[part 4 of 15: package /Cluster]
AUTOSAR XML (schema 4-3-0)
package /Cluster  (continued)
  can cluster HCP3_CANFD01: baudrate=500000, protocol-name=CAN, protocol-version=2.0, bus-off-recovery={bor-counter-l-1-to-l-2=1, bor-time-l-1=0.05, bor-time-l-2=0.2}, can-fd-baudrate=1000000  (continued)
    can physical channel CHNL: comm-connectors=CN_HCP3_CANFD01  (continued)
      frame LSR_Common_01_XIX_HCP3_CANFD01: id 0x1A5554CC, to HCP3_IONode, frame-length=12, can-addressing-mode=EXTENDED, can-frame-rx-behavior=CAN-FD, can-frame-tx-behavior=CAN-FD
        pdu LSR_Common_01_XIX_HCP3_CANFD01: length=12, transmission-mode-true-timing=cyclic-timing={time-offset=0.0, time-period=1.0}, unused-bit-pattern=0
          signal LSR_SystemMode_XIX_LSR_Common_01_XIX_HCP3_CANFD01: start 12, 1 bit, little-endian, data-type-policy=OVERRIDE, i-signal-type=PRIMITIVE, init-value=0, base-type=BT_LSR_SystemMode, compu {0=Cx0_bootloader (CM_LSR_SystemMode_Cx0_bootloader), 1=Cx1_applikation (CM_LSR_SystemMode_Cx1_applikation)}, range raw 0..1, transfer-property=PENDING, to HCP3_IONode(timeout 5 s)  # Current system mode of LSR
          signal LSR_CL30_Overvolt_Error_XIX_LSR_Common_01_XIX_HCP3_CANFD01: start 13, 1 bit, little-endian, data-type-policy=OVERRIDE, i-signal-type=PRIMITIVE, init-value=0, base-type=BT_LSR_CL30_Overvolt_Error, invalid-value=Invalid_LSR_CL30_Overvolt_Error_XIX_LSR_Common_01_XIX_HCP3_CANFD01:1, compu {1=Cx1_Fehler (CM_LSR_CL30_Overvolt_Error_Cx1_Fehler), 0=Cx0_normal (CM_LSR_CL30_Overvolt_Error_Cx0_normal)}, range raw 0..1, transfer-property=PENDING, to HCP3_IONode(timeout 5 s)  # LSR detected overvoltage error
          signal LSR_CL30_Undervoltage_Error_XIX_LSR_Common_01_XIX_HCP3_CANFD01: start 14, 1 bit, little-endian, data-type-policy=OVERRIDE, i-signal-type=PRIMITIVE, init-value=0, base-type=BT_LSR_CL30_Undervoltage_Error, invalid-value=Invalid_LSR_CL30_Undervoltage_Error_XIX_LSR_Common_01_XIX_HCP3_CANFD01:1, compu {1=Cx1_Fehler (CM_LSR_CL30_Undervoltage_Error_Cx1_Fehler), 0=Cx0_normal (CM_LSR_CL30_Undervoltage_Error_Cx0_normal)}, range raw 0..1, transfer-property=PENDING, to HCP3_IONode(timeout 5 s)  # LSR detected undervoltage error
          signal LSR_EEPROM_Error_TF_XIX_LSR_Common_01_XIX_HCP3_CANFD01: start 15, 1 bit, little-endian, data-type-policy=OVERRIDE, i-signal-type=PRIMITIVE, init-value=0, base-type=BT_LSR_EEPROM_Error_TF, compu {1=Cx1_active (CM_LSR_EEPROM_Error_TF_Cx1_active), 0=Cx0_passive (CM_LSR_EEPROM_Error_TF_Cx0_passive)}, range raw 0..1, transfer-property=PENDING, to HCP3_IONode(timeout 5 s)  # EEPROM_Error of LSR detected Diagnostic information TestFailed
          signal LSR_EEPROM_Error_TNCTOC_XIX_LSR_Common_01_XIX_HCP3_CANFD01: start 16, 1 bit, little-endian, data-type-policy=OVERRIDE, i-signal-type=PRIMITIVE, init-value=0, base-type=BT_LSR_EEPROM_Error_TNCTOC, compu {0=Cx0_completed (CM_LSR_EEPROM_Error_TNCTOC_Cx0_completed), 1=Cx1_not_completed (CM_LSR_EEPROM_Error_TNCTOC_Cx1_not_completed)}, range raw 0..1, transfer-property=PENDING, to HCP3_IONode(timeout 5 s)  # TestNotCompletedThisOperationCycle for DTC LSR_EEPROM_error
          signal LSR_dimming_PWM_XIX_LSR_Common_01_XIX_HCP3_CANFD01: start 17, 7 bit, little-endian, data-type-policy=OVERRIDE, i-signal-type=PRIMITIVE, init-value=0, base-type=BT_LSR_dimming_PWM, compu {phys=raw for raw 0..100; unit Unit_PerCent}, range phys 0..100 Unit_PerCent, raw 0..100, unit=Unit_PerCent, transfer-property=PENDING, to HCP3_IONode(timeout 5 s)  # PWM value of dimming
          signal LSR_dimming_post_carriage_XIX_LSR_Common_01_XIX_HCP3_CANFD01: start 24, 1 bit, little-endian, data-type-policy=OVERRIDE, i-signal-type=PRIMITIVE, init-value=0, base-type=BT_LSR_dimming_post_carriage, compu {0=Cx0_not_active (CM_LSR_dimming_post_carriage_Cx0_not_active), 1=Cx1_active (CM_LSR_dimming_post_carriage_Cx1_active)}, range raw 0..1, transfer-property=PENDING, to HCP3_IONode(timeout 5 s)  # dimming post carriage of LSR
          signal LSR_SW_inconsistent_TNCTOC_XIX_LSR_Common_01_XIX_HCP3_CANFD01: start 25, 1 bit, little-endian, data-type-policy=OVERRIDE, i-signal-type=PRIMITIVE, init-value=1, base-type=BT_LSR_SW_inconsistent_TNCTOC, compu {0=Cx0_completed (CM_LSR_SW_inconsistent_TNCTOC_Cx0_completed), 1=Cx1_not_completed (CM_LSR_SW_inconsistent_TNCTOC_Cx1_not_completed)}, range raw 0..1, transfer-property=PENDING, to HCP3_IONode(timeout 5 s)  # TestNotCompletedThisOperationCycle for LSR DTC LSR_SW_inconsistent
          signal LSR_SW_inconsistent_TF_XIX_LSR_Common_01_XIX_HCP3_CANFD01: start 26, 1 bit, little-endian, data-type-policy=OVERRIDE, i-signal-type=PRIMITIVE, init-value=0, base-type=BT_LSR_SW_inconsistent_TF, compu {1=Cx1_active (CM_LSR_SW_inconsistent_TF_Cx1_active), 0=Cx0_passive (CM_LSR_SW_inconsistent_TF_Cx0_passive)}, range raw 0..1, transfer-property=PENDING, to HCP3_IONode(timeout 5 s)  # SW_inconsistent of LSR detected Diagnostic information TestFailed
      frame LSR_KeyInpLSR_Req_FD_XIX_HCP3_CANFD01: id 0x1CD0246C, to HCP3_IONode, frame-length=64, can-addressing-mode=EXTENDED, can-frame-rx-behavior=CAN-FD, can-frame-tx-behavior=CAN-FD
        n pdu LSR_KeyInpLSR_Req_FD_XIX_HCP3_CANFD01: length=64
      frame LSR_KeyInpLSR_Resp_FD_XIX_HCP3_CANFD01: id 0x1CD2246C, from HCP3_IONode, frame-length=64, can-addressing-mode=EXTENDED, can-frame-rx-behavior=CAN-FD, can-frame-tx-behavior=CAN-FD
        n pdu LSR_KeyInpLSR_Resp_FD_XIX_HCP3_CANFD01: length=64
      frame MDK_02_XIX_HCP3_CANFD01: id 0x16A95574, from HCP3_IONode, frame-length=8, can-addressing-mode=EXTENDED, can-frame-rx-behavior=CAN-FD, can-frame-tx-behavior=CAN-FD
        pdu MDK_02_XIX_HCP3_CANFD01: length=8, transmission-mode-true-timing=cyclic-timing={time-offset=0.0, time-period=0.2}, unused-bit-pattern=0
          signal MDK_Change_Polling_Mode_XIX_MDK_02_XIX_HCP3_CANFD01: start 12, 4 bit, little-endian, data-type-policy=OVERRIDE, i-signal-type=PRIMITIVE, init-value=0, base-type=BT_MDK_Change_Polling_Mode, compu {1=Cx1_NormalMode (CM_MDK_Change_Polling_Mode_Cx1_NormalMode), 2=Cx2_OwnerPairingMode (CM_MDK_Change_Polling_Mode_Cx2_OwnerPairingMode), 0=Cx0_Init (CM_MDK_Change_Polling_Mode_Cx0_Init)}, range raw 0..2, transfer-property=PENDING  # Trigger um den Polling Modus zu wechseln
          signal MDK_Function_State_XIX_MDK_02_XIX_HCP3_CANFD01: start 16, 2 bit, little-endian, data-type-policy=OVERRIDE, i-signal-type=PRIMITIVE, init-value=0, base-type=BT_MDK_Function_State, compu {0=Cx0_Init (CM_MDK_Function_State_Cx0_Init), 1=Cx1_MDK_aktiviert (CM_MDK_Function_State_Cx1_MDK_aktiviert), 3=Cx3_MDK_auskodiert (CM_MDK_Function_State_Cx3_MDK_auskodiert), 2=Cx2_MDK_deaktiviert (CM_MDK_Function_State_Cx2_MDK_deaktiviert)}, range raw 0..3, transfer-property=PENDING  # Status über die Funktionalität des SW-Moduls MDK.
      frame MKGO_FBS_01_XIX_HCP3_CANFD01: id 0x16A95533, to HCP3_IONode, frame-length=64, can-addressing-mode=EXTENDED, can-frame-rx-behavior=CAN-FD, can-frame-tx-behavior=CAN-FD
        pdu MKGO_FBS_01_XIX_HCP3_CANFD01: length=64, transmission-mode-true-timing=event-controlled-timing={number-of-repetitions=0, repetition-period=0.0}, unused-bit-pattern=0
          signal MKGO_FBS_01_XIX_MKGO_FBS_01_XIX_HCP3_CANFD01: start 0, 512 bit, opaque, data-type-policy=OVERRIDE, i-signal-type=ARRAY, init-value=64 x 0, base-type=BT_MKGO_FBS_01, implementation-data-type=MKGO_FBS_01, transfer-property=TRIGGERED-WITHOUT-REPETITION  # NFC Kommunikation MKGO zu FBS
      frame MKGO_FBS_02_XIX_HCP3_CANFD01: id 0x16A95534, to HCP3_IONode, frame-length=64, can-addressing-mode=EXTENDED, can-frame-rx-behavior=CAN-FD, can-frame-tx-behavior=CAN-FD
        pdu MKGO_FBS_02_XIX_HCP3_CANFD01: length=64, transmission-mode-true-timing=event-controlled-timing={number-of-repetitions=0, repetition-period=0.0}, unused-bit-pattern=0
          signal MKGO_FBS_02_XIX_MKGO_FBS_02_XIX_HCP3_CANFD01: start 0, 512 bit, opaque, data-type-policy=OVERRIDE, i-signal-type=ARRAY, init-value=64 x 0, base-type=BT_MKGO_FBS_02, implementation-data-type=MKGO_FBS_02, transfer-property=TRIGGERED-WITHOUT-REPETITION  # NFC Kommunikation MKGO zu FBS
      frame MKGO_FBS_03_XIX_HCP3_CANFD01: id 0x16A95535, to HCP3_IONode, frame-length=64, can-addressing-mode=EXTENDED, can-frame-rx-behavior=CAN-FD, can-frame-tx-behavior=CAN-FD
        pdu MKGO_FBS_03_XIX_HCP3_CANFD01: length=64, transmission-mode-true-timing=event-controlled-timing={number-of-repetitions=0, repetition-period=0.0}, unused-bit-pattern=0
          signal MKGO_FBS_03_XIX_MKGO_FBS_03_XIX_HCP3_CANFD01: start 0, 512 bit, opaque, data-type-policy=OVERRIDE, i-signal-type=ARRAY, init-value=64 x 0, base-type=BT_MKGO_FBS_03, implementation-data-type=MKGO_FBS_03, transfer-property=TRIGGERED-WITHOUT-REPETITION  # NFC Kommunikation MKGO zu FBS
      frame MKGO_FBS_04_XIX_HCP3_CANFD01: id 0x16A95536, to HCP3_IONode, frame-length=64, can-addressing-mode=EXTENDED, can-frame-rx-behavior=CAN-FD, can-frame-tx-behavior=CAN-FD
        pdu MKGO_FBS_04_XIX_HCP3_CANFD01: length=64, transmission-mode-true-timing=event-controlled-timing={number-of-repetitions=0, repetition-period=0.0}, unused-bit-pattern=0
          signal MKGO_FBS_04_XIX_MKGO_FBS_04_XIX_HCP3_CANFD01: start 0, 512 bit, opaque, data-type-policy=OVERRIDE, i-signal-type=ARRAY, init-value=64 x 0, base-type=BT_MKGO_FBS_04, implementation-data-type=MKGO_FBS_04, transfer-property=TRIGGERED-WITHOUT-REPETITION  # NFC Kommunikation MKGO zu FBS
      frame MKGO_FBS_05_XIX_HCP3_CANFD01: id 0x16A95537, to HCP3_IONode, frame-length=64, can-addressing-mode=EXTENDED, can-frame-rx-behavior=CAN-FD, can-frame-tx-behavior=CAN-FD
        pdu MKGO_FBS_05_XIX_HCP3_CANFD01: length=64, transmission-mode-true-timing=event-controlled-timing={number-of-repetitions=0, repetition-period=0.0}, unused-bit-pattern=0
          signal MKGO_FBS_05_XIX_MKGO_FBS_05_XIX_HCP3_CANFD01: start 0, 512 bit, opaque, data-type-policy=OVERRIDE, i-signal-type=ARRAY, init-value=64 x 0, base-type=BT_MKGO_FBS_05, implementation-data-type=MKGO_FBS_05, transfer-property=TRIGGERED-WITHOUT-REPETITION  # NFC Kommunikation MKGO zu FBS
      frame NFC_MiKo_01_XIX_HCP3_CANFD01: id 0x16A9549D, to HCP3_IONode, frame-length=8, can-addressing-mode=EXTENDED, can-frame-rx-behavior=CAN-FD, can-frame-tx-behavior=CAN-FD
        pdu NFC_MiKo_01_XIX_HCP3_CANFD01: length=8, transmission-mode-true-timing=cyclic-timing={time-offset=0.0, time-period=0.2}, unused-bit-pattern=0
          signal NFC_MiKo_NFC_Device_Status_XIX_NFC_MiKo_01_XIX_HCP3_CANFD01: start 58, 3 bit, little-endian, data-type-policy=OVERRIDE, i-signal-type=PRIMITIVE, init-value=0, base-type=BT_NFC_MiKo_NFC_Device_Status, compu {3=Cx3_MDK_Applet_erkannt (CM_NFC_MiKo_NFC_Device_Status_Cx3_MDK_Applet_erkannt), 2=Cx2_MDK_Framework_erkannt (CM_NFC_MiKo_NFC_Device_Status_Cx2_MDK_Framework_erkannt), 1=Cx1_NFC_Device_erkannt (CM_NFC_MiKo_NFC_Device_Status_Cx1_NFC_Device_erkannt), 4=Cx4_MDK_Servicekarte_erkannt (CM_NFC_MiKo_NFC_Device_Status_Cx4_MDK_Servicekarte_erkannt), 5=Cx5_MDK_Device_authentifiziert (CM_NFC_MiKo_NFC_Device_Status_Cx5_MDK_Device_authentifiziert), 0=Cx0_Init_nicht_erkannt (CM_NFC_MiKo_NFC_Device_Status_Cx0_Init_nicht_erkannt)}, range raw 0..5, transfer-property=PENDING  # Status der aktuellen NFC Erkennung
          signal NFC_MiKo_NFC_Device_gekoppelt_XIX_NFC_MiKo_01_XIX_HCP3_CANFD01: start 61, 1 bit, little-endian, data-type-policy=OVERRIDE, i-signal-type=PRIMITIVE, init-value=0, base-type=BT_NFC_MiKo_NFC_Device_gekoppelt, compu {0=Cx0_Init_kein_NFC_Device_gekoppelt (CM_NFC_MiKo_NFC_Device_gekoppelt_Cx0_Init_kein_NFC_Device_gekoppelt), 1=Cx1_NFC_Device_gekoppelt (CM_NFC_MiKo_NFC_Device_gekoppelt_Cx1_NFC_Device_gekoppelt)}, range raw 0..1, transfer-property=PENDING  # Ein NFC-Device ist im Empfangsbereich und der NFC-Reader hat eine aktive Verbindung aufgebaut.
      frame NM_CCF_XIX_HCP3_CANFD01: id 0x1B000124, to HCP3_IONode, frame-length=24, can-addressing-mode=EXTENDED, can-frame-rx-behavior=CAN-FD, can-frame-tx-behavior=CAN-FD, rx-identifier-range={lower-can-id=452984832, upper-can-id=452985855}
        nm pdu NM_CCF_XIX_HCP3_CANFD01: length=24, unused-bit-pattern=0
          signal NM_CCF_CBV_AWB_XIX_NM_CCF_XIX_HCP3_CANFD01: start 4, 1 bit, little-endian, data-type-policy=OVERRIDE, i-signal-type=PRIMITIVE, init-value=0, base-type=BT_NM_CCF_CBV_AWB, compu {1=Cx1_Aktiver_WakeUp (CM_NM_CCF_CBV_AWB_Cx1_Aktiver_WakeUp), 0=Cx0_Passiver_WakeUp (CM_NM_CCF_CBV_AWB_Cx0_Passiver_WakeUp)}, range raw 0..1, transfer-property=TRIGGERED  # Das Signal ist zu setzen, wenn das SG aktiv den Bus geweckt hat 0 = Passiver_WakeUp = SG hat das Netzwerk nicht aktiv geweckt 1 = Akitiver_WakeUp = SG hat das Netzwerk aktiv geweckt
          signal NM_CCF_CBV_CRI_XIX_NM_CCF_XIX_HCP3_CANFD01: start 6, 1 bit, little-endian, data-type-policy=OVERRIDE, i-signal-type=PRIMITIVE, init-value=1, base-type=BT_NM_CCF_CBV_CRI, compu {0=Cx0_NM_ohne_Clusteranforderungen (CM_NM_CCF_CBV_CRI_Cx0_NM_ohne_Clusteranforderungen), 1=Cx1_NM_mit_Clusteranforderungen (CM_NM_CCF_CBV_CRI_Cx1_NM_mit_Clusteranforderungen)}, range raw 0..1, transfer-property=TRIGGERED  # Das Signal ist dauerhaft gesetzt, wenn das NM-Layout Cluster- Anforderungen enthält
          signal NM_CCF_FCAB_XIX_NM_CCF_XIX_HCP3_CANFD01: start 8, 56 bit, opaque, data-type-policy=OVERRIDE, i-signal-type=ARRAY, init-value=7 x 0b00000000, base-type=BT_NM_CCF_FCAB, compu {8=Cx8_04_Basefunction_DrivingAssistance (CM_NM_CCF_FCAB_Cx8_04_Basefunction_DrivingAssistance), 0=Cx0_Init (CM_NM_CCF_FCAB_Cx0_Init), 262144=Cx40000_19_Doors_Hatches (CM_NM_CCF_FCAB_Cx40000_19_Doors_Hatches), 140737488355328=Cx800000000000_48_Diagnosis_ClimateTmeLINs (CM_NM_CCF_FCAB_Cx800000000000_48_Diagnosis_ClimateTmeLINs), 1=Cx1_01_CarWakeUp (CM_NM_CCF_FCAB_Cx1_01_CarWakeUp), 2048=Cx800_12_GearSelector (CM_NM_CCF_FCAB_Cx800_12_GearSelector), 1073741824=Cx40000000_31_MultifunctionalSteeringWheel (CM_NM_CCF_FCAB_Cx40000000_31_MultifunctionalSteeringWheel), 1048576=Cx100000_21_AirSuspension (CM_NM_CCF_FCAB_Cx100000_21_AirSuspension), 4=Cx4_03_Basefunction_Chassis (CM_NM_CCF_FCAB_Cx4_03_Basefunction_Chassis), 4096=Cx1000_13_Airbag (CM_NM_CCF_FCAB_Cx1000_13_Airbag), 8192=Cx2000_14_InfotainmentExtensions (CM_NM_CCF_FCAB_Cx2000_14_InfotainmentExtensions), 8796093022208=Cx80000000000_44_Diagnosis_Infotainment (CM_NM_CCF_FCAB_Cx80000000000_44_Diagnosis_Infotainment), 2199023255552=Cx20000000000_42_Diagnosis_FlexRay (CM_NM_CCF_FCAB_Cx20000000000_42_Diagnosis_FlexRay), 32768=Cx8000_16_InfotainmentDisplay (CM_NM_CCF_FCAB_Cx8000_16_InfotainmentDisplay), 16777216=Cx1000000_25_AccessSystemSensors (CM_NM_CCF_FCAB_Cx1000000_25_AccessSystemSensors), 34359738368=Cx800000000_36_Preheater (CM_NM_CCF_FCAB_Cx800000000_36_Preheater), 64=Cx40_07_Basefunction_CrossSection (CM_NM_CCF_FCAB_Cx40_07_Basefunction_CrossSection), 281474976710656=Cx1000000000000_49_reserved (CM_NM_CCF_FCAB_Cx1000000000000_49_reserved) (49_<reserved>), 17179869184=Cx400000000_35_ExteriorSound (CM_NM_CCF_FCAB_Cx400000000_35_ExteriorSound), 68719476736=Cx1000000000_37_HighVoltage_WirelessChargingStation (CM_NM_CCF_FCAB_Cx1000000000_37_HighVoltage_WirelessChargingStation), 256=Cx100_09_reserved (CM_NM_CCF_FCAB_Cx100_09_reserved) (09_<reserved>), 4398046511104=Cx40000000000_43_Diagnosis_DrivingAssistance (CM_NM_CCF_FCAB_Cx40000000000_43_Diagnosis_DrivingAssistance), 2097152=Cx200000_22_ExteriorLights (CM_NM_CCF_FCAB_Cx200000_22_ExteriorLights), 2=Cx2_02_Basefunction_Powertrain (CM_NM_CCF_FCAB_Cx2_02_Basefunction_Powertrain), 35184372088832=Cx200000000000_46_Diagnosis_Light (CM_NM_CCF_FCAB_Cx200000000000_46_Diagnosis_Light), 36028797018963968=Cx80000000000000_56_ChargingStatus (CM_NM_CCF_FCAB_Cx80000000000000_56_ChargingStatus), 8589934592=Cx200000000_34_GPS_Localization (CM_NM_CCF_FCAB_Cx200000000_34_GPS_Localization), 128=Cx80_08_Basefunction_Connectivity (CM_NM_CCF_FCAB_Cx80_08_Basefunction_Connectivity), 4294967296=Cx100000000_33_ExternalWirelessCommunication (CM_NM_CCF_FCAB_Cx100000000_33_ExternalWirelessCommunication), 268435456=Cx10000000_29_SteeringColumnLock (CM_NM_CCF_FCAB_Cx10000000_29_SteeringColumnLock), 512=Cx200_10_Powertrain (CM_NM_CCF_FCAB_Cx200_10_Powertrain), 33554432=Cx2000000_26_HighVoltage_Charging (CM_NM_CCF_FCAB_Cx2000000_26_HighVoltage_Charging), 131072=Cx20000_18_VirtualSideMirrors (CM_NM_CCF_FCAB_Cx20000_18_VirtualSideMirrors), 16=Cx10_05_Basefunction_Infotainment (CM_NM_CCF_FCAB_Cx10_05_Basefunction_Infotainment), 67108864=Cx4000000_27_Timemaster_Timer (CM_NM_CCF_FCAB_Cx4000000_27_Timemaster_Timer), 4194304=Cx400000_23_Climate (CM_NM_CCF_FCAB_Cx400000_23_Climate), 70368744177664=Cx400000000000_47_Diagnosis_ComfortLINs (CM_NM_CCF_FCAB_Cx400000000000_47_Diagnosis_ComfortLINs), 18014398509481984=Cx40000000000000_55_Dimming (CM_NM_CCF_FCAB_Cx40000000000000_55_Dimming), 536870912=Cx20000000_30_EnergyManagement (CM_NM_CCF_FCAB_Cx20000000_30_EnergyManagement), 524288=Cx80000_20_OptionalComfort (CM_NM_CCF_FCAB_Cx80000_20_OptionalComfort), 16384=Cx4000_15_InstrumentclusterDisplay (CM_NM_CCF_FCAB_Cx4000_15_InstrumentclusterDisplay), 4503599627370496=Cx10000000000000_53_Lock_Unlock (CM_NM_CCF_FCAB_Cx10000000000000_53_Lock_Unlock), 17592186044416=Cx100000000000_45_Diagnosis_Comfort (CM_NM_CCF_FCAB_Cx100000000000_45_Diagnosis_Comfort), 1024=Cx400_11_Chassis (CM_NM_CCF_FCAB_Cx400_11_Chassis), 65536=Cx10000_17_Audio (CM_NM_CCF_FCAB_Cx10000_17_Audio), 8388608=Cx800000_24_ThermoManagement (CM_NM_CCF_FCAB_Cx800000_24_ThermoManagement), 2147483648=Cx80000000_32_OnlineAccess (CM_NM_CCF_FCAB_Cx80000000_32_OnlineAccess), 134217728=Cx8000000_28_OnboardTester_DataCollector (CM_NM_CCF_FCAB_Cx8000000_28_OnboardTester_DataCollector), 32=Cx20_06_Basefunction_ComfortLight (CM_NM_CCF_FCAB_Cx20_06_Basefunction_ComfortLight), 1099511627776=Cx10000000000_41_Diagnosis_Powertrain (CM_NM_CCF_FCAB_Cx10000000000_41_Diagnosis_Powertrain), 549755813888=Cx8000000000_40_Diagnosis_Energy (CM_NM_CCF_FCAB_Cx8000000000_40_Diagnosis_Energy), 9007199254740992=Cx20000000000000_54_reserved (CM_NM_CCF_FCAB_Cx20000000000000_54_reserved) (54_<reserved>)}, range raw 0..36028797018963968, transfer-property=TRIGGERED-ON-CHANGE  # FCAB = Funktions-Cluster-Aktiv-Bits
          signal NM_CCF_SNI_10_XIX_NM_CCF_XIX_HCP3_CANFD01: start 128, 10 bit, little-endian, data-type-policy=OVERRIDE, i-signal-type=PRIMITIVE, init-value=292, base-type=BT_NM_CCF_SNI_10, compu {292=Cx124_CCF_SNI (CM_NM_CCF_SNI_10_Cx124_CCF_SNI)}, range raw 292, transfer-property=TRIGGERED  # Source Node-Identifier (SNI) identifiziert den Sender der NM-Botschaft (Knotenadresse) eindeutig im Fahrzeug
          signal NM_CCF_NM_State_XIX_NM_CCF_XIX_HCP3_CANFD01: start 144, 6 bit, little-endian, data-type-policy=OVERRIDE, i-signal-type=PRIMITIVE, init-value=0, base-type=BT_NM_CCF_NM_State, compu {32=Cx20_reserved (CM_NM_CCF_NM_State_Cx20_reserved), 8=Cx8_NM_NO_aus_RS (CM_NM_CCF_NM_State_Cx8_NM_NO_aus_RS), 1=Cx1_NM_RM_aus_BSM (CM_NM_CCF_NM_State_Cx1_NM_RM_aus_BSM), 2=Cx2_NM_RM_aus_PBSM (CM_NM_CCF_NM_State_Cx2_NM_RM_aus_PBSM), 0=Cx0_Init (CM_NM_CCF_NM_State_Cx0_Init), 4=Cx4_NM_NO_aus_RM (CM_NM_CCF_NM_State_Cx4_NM_NO_aus_RM), 16=Cx10_reserved (CM_NM_CCF_NM_State_Cx10_reserved)}, range raw 0..32, transfer-property=TRIGGERED  # 1 = Zustand Repeat Message (<-- Bus-Sleep Mode) 2 = Zustand Repeat Message (<-- Prepare Bus-Sleep Mode) 4 = Zustand Normal Operation (<-- Repeat Message) 8 = Zustand Normal Operation (<-- Ready Sleep)
          signal NM_CCF_UDS_CC_XIX_NM_CCF_XIX_HCP3_CANFD01: start 151, 1 bit, little-endian, data-type-policy=OVERRIDE, i-signal-type=PRIMITIVE, init-value=0, base-type=BT_NM_CCF_UDS_CC, compu {0=Cx0_Inaktiv (CM_NM_CCF_UDS_CC_Cx0_Inaktiv), 1=Cx1_CC_aktiv (CM_NM_CCF_UDS_CC_Cx1_CC_aktiv)}, range raw 0..1, transfer-property=TRIGGERED  # Funktionseinschränkung aufgrund aktivem UDS-Communication Control, siehe VW80124
          signal NM_CCF_Wakeup_V12_XIX_NM_CCF_XIX_HCP3_CANFD01: start 152, 8 bit, little-endian, data-type-policy=OVERRIDE, i-signal-type=PRIMITIVE, init-value=0, base-type=BT_NM_CCF_Wakeup_V12, compu {0=Cx0_Peripherie_Wakeup_Ursache_nicht_bekannt (CM_NM_CCF_Wakeup_V12_Cx0_Peripherie_Wakeup_Ursache_nicht_bekannt), 1=Cx1_Bus_Wakeup (CM_NM_CCF_Wakeup_V12_Cx1_Bus_Wakeup), 2=Cx2_KL15_HW (CM_NM_CCF_Wakeup_V12_Cx2_KL15_HW)}, range raw 0..2, transfer-property=TRIGGERED  # enthält die Weckursache; stehen mehrere Weckursachen parallel an, dann muss der kleinste Wert übertragen werden
          signal NM_CCF_NM_aktiv_KL15_XIX_NM_CCF_XIX_HCP3_CANFD01: start 160, 1 bit, little-endian, data-type-policy=OVERRIDE, i-signal-type=PRIMITIVE, init-value=0, base-type=BT_NM_CCF_NM_aktiv_KL15, compu {0=Cx0_Inaktiv (CM_NM_CCF_NM_aktiv_KL15_Cx0_Inaktiv), 1=Cx1_KL15_EIN (CM_NM_CCF_NM_aktiv_KL15_Cx1_KL15_EIN)}, range raw 0..1, transfer-property=TRIGGERED  # Steuergerät hat KL15-EIN erkannt
          signal NM_CCF_NM_aktiv_Diag_XIX_NM_CCF_XIX_HCP3_CANFD01: start 161, 1 bit, little-endian, data-type-policy=OVERRIDE, i-signal-type=PRIMITIVE, init-value=0, base-type=BT_NM_CCF_NM_aktiv_Diag, compu {1=Cx1_Diagnose_aktiv (CM_NM_CCF_NM_aktiv_Diag_Cx1_Diagnose_aktiv), 0=Cx0_Inaktiv (CM_NM_CCF_NM_aktiv_Diag_Cx0_Inaktiv)}, range raw 0..1, transfer-property=TRIGGERED  # Diagnose befindet sich nach VW80124 in einer NonDefaultDiagnostic-Session, z.B. ExtendedDiagnostic-Session
          signal NM_CCF_NM_aktiv_Tmin_XIX_NM_CCF_XIX_HCP3_CANFD01: start 162, 1 bit, little-endian, data-type-policy=OVERRIDE, i-signal-type=PRIMITIVE, init-value=0, base-type=BT_NM_CCF_NM_aktiv_Tmin, compu {1=Cx1_Mindestaktivzeit (CM_NM_CCF_NM_aktiv_Tmin_Cx1_Mindestaktivzeit), 0=Cx0_Inaktiv (CM_NM_CCF_NM_aktiv_Tmin_Cx0_Inaktiv)}, range raw 0..1, transfer-property=TRIGGERED  # Mindestaktivzeit ist noch nicht abgelaufen (bei jedem Weckereignis wird die Mindestaktivzeit neu gestartet)
      frame NM_CID_XIX_HCP3_CANFD01: id 0x1B000122, to HCP3_IONode, frame-length=24, can-addressing-mode=EXTENDED, can-frame-rx-behavior=CAN-FD, can-frame-tx-behavior=CAN-FD, rx-identifier-range={lower-can-id=452984832, upper-can-id=452985855}
        nm pdu NM_CID_XIX_HCP3_CANFD01: length=24, unused-bit-pattern=0
          signal NM_CID_CBV_AWB_XIX_NM_CID_XIX_HCP3_CANFD01: start 4, 1 bit, little-endian, data-type-policy=OVERRIDE, i-signal-type=PRIMITIVE, init-value=0, base-type=BT_NM_CID_CBV_AWB, compu {0=Cx0_Passiver_WakeUp (CM_NM_CID_CBV_AWB_Cx0_Passiver_WakeUp), 1=Cx1_Aktiver_WakeUp (CM_NM_CID_CBV_AWB_Cx1_Aktiver_WakeUp)}, range raw 0..1, transfer-property=TRIGGERED  # Das Signal ist zu setzen, wenn das SG aktiv den Bus geweckt hat 0 = Passiver_WakeUp = SG hat das Netzwerk nicht aktiv geweckt 1 = Akitiver_WakeUp = SG hat das Netzwerk aktiv geweckt
          signal NM_CID_CBV_CRI_XIX_NM_CID_XIX_HCP3_CANFD01: start 6, 1 bit, little-endian, data-type-policy=OVERRIDE, i-signal-type=PRIMITIVE, init-value=1, base-type=BT_NM_CID_CBV_CRI, compu {1=Cx1_NM_mit_Clusteranforderungen (CM_NM_CID_CBV_CRI_Cx1_NM_mit_Clusteranforderungen), 0=Cx0_NM_ohne_Clusteranforderungen (CM_NM_CID_CBV_CRI_Cx0_NM_ohne_Clusteranforderungen)}, range raw 0..1, transfer-property=TRIGGERED  # Das Signal ist dauerhaft gesetzt, wenn das NM-Layout Cluster- Anforderungen enthält
          signal NM_CID_FCAB_XIX_NM_CID_XIX_HCP3_CANFD01: start 8, 56 bit, opaque, data-type-policy=OVERRIDE, i-signal-type=ARRAY, init-value=7 x 0b00000000, base-type=BT_NM_CID_FCAB, compu {1099511627776=Cx10000000000_41_Diagnosis_Powertrain (CM_NM_CID_FCAB_Cx10000000000_41_Diagnosis_Powertrain), 4194304=Cx400000_23_Climate (CM_NM_CID_FCAB_Cx400000_23_Climate), 0=Cx0_Init (CM_NM_CID_FCAB_Cx0_Init), 512=Cx200_10_Powertrain (CM_NM_CID_FCAB_Cx200_10_Powertrain), 2147483648=Cx80000000_32_OnlineAccess (CM_NM_CID_FCAB_Cx80000000_32_OnlineAccess), 262144=Cx40000_19_Doors_Hatches (CM_NM_CID_FCAB_Cx40000_19_Doors_Hatches), 4096=Cx1000_13_Airbag (CM_NM_CID_FCAB_Cx1000_13_Airbag), 128=Cx80_08_Basefunction_Connectivity (CM_NM_CID_FCAB_Cx80_08_Basefunction_Connectivity), 35184372088832=Cx200000000000_46_Diagnosis_Light (CM_NM_CID_FCAB_Cx200000000000_46_Diagnosis_Light), 68719476736=Cx1000000000_37_HighVoltage_WirelessChargingStation (CM_NM_CID_FCAB_Cx1000000000_37_HighVoltage_WirelessChargingStation), 140737488355328=Cx800000000000_48_Diagnosis_ClimateTmeLINs (CM_NM_CID_FCAB_Cx800000000000_48_Diagnosis_ClimateTmeLINs), 4=Cx4_03_Basefunction_Chassis (CM_NM_CID_FCAB_Cx4_03_Basefunction_Chassis), 8796093022208=Cx80000000000_44_Diagnosis_Infotainment (CM_NM_CID_FCAB_Cx80000000000_44_Diagnosis_Infotainment), 4398046511104=Cx40000000000_43_Diagnosis_DrivingAssistance (CM_NM_CID_FCAB_Cx40000000000_43_Diagnosis_DrivingAssistance), 4294967296=Cx100000000_33_ExternalWirelessCommunication (CM_NM_CID_FCAB_Cx100000000_33_ExternalWirelessCommunication), 256=Cx100_09_reserved (CM_NM_CID_FCAB_Cx100_09_reserved) (09_<reserved>), 16=Cx10_05_Basefunction_Infotainment (CM_NM_CID_FCAB_Cx10_05_Basefunction_Infotainment), 8589934592=Cx200000000_34_GPS_Localization (CM_NM_CID_FCAB_Cx200000000_34_GPS_Localization), 67108864=Cx4000000_27_Timemaster_Timer (CM_NM_CID_FCAB_Cx4000000_27_Timemaster_Timer), 4503599627370496=Cx10000000000000_53_Lock_Unlock (CM_NM_CID_FCAB_Cx10000000000000_53_Lock_Unlock), 65536=Cx10000_17_Audio (CM_NM_CID_FCAB_Cx10000_17_Audio), 131072=Cx20000_18_VirtualSideMirrors (CM_NM_CID_FCAB_Cx20000_18_VirtualSideMirrors), 32768=Cx8000_16_InfotainmentDisplay (CM_NM_CID_FCAB_Cx8000_16_InfotainmentDisplay), 8=Cx8_04_Basefunction_DrivingAssistance (CM_NM_CID_FCAB_Cx8_04_Basefunction_DrivingAssistance), 70368744177664=Cx400000000000_47_Diagnosis_ComfortLINs (CM_NM_CID_FCAB_Cx400000000000_47_Diagnosis_ComfortLINs), 8388608=Cx800000_24_ThermoManagement (CM_NM_CID_FCAB_Cx800000_24_ThermoManagement), 16777216=Cx1000000_25_AccessSystemSensors (CM_NM_CID_FCAB_Cx1000000_25_AccessSystemSensors), 8192=Cx2000_14_InfotainmentExtensions (CM_NM_CID_FCAB_Cx2000_14_InfotainmentExtensions), 549755813888=Cx8000000000_40_Diagnosis_Energy (CM_NM_CID_FCAB_Cx8000000000_40_Diagnosis_Energy), 1048576=Cx100000_21_AirSuspension (CM_NM_CID_FCAB_Cx100000_21_AirSuspension), 2=Cx2_02_Basefunction_Powertrain (CM_NM_CID_FCAB_Cx2_02_Basefunction_Powertrain), 1073741824=Cx40000000_31_MultifunctionalSteeringWheel (CM_NM_CID_FCAB_Cx40000000_31_MultifunctionalSteeringWheel), 34359738368=Cx800000000_36_Preheater (CM_NM_CID_FCAB_Cx800000000_36_Preheater), 2199023255552=Cx20000000000_42_Diagnosis_FlexRay (CM_NM_CID_FCAB_Cx20000000000_42_Diagnosis_FlexRay), 16384=Cx4000_15_InstrumentclusterDisplay (CM_NM_CID_FCAB_Cx4000_15_InstrumentclusterDisplay), 33554432=Cx2000000_26_HighVoltage_Charging (CM_NM_CID_FCAB_Cx2000000_26_HighVoltage_Charging), 2097152=Cx200000_22_ExteriorLights (CM_NM_CID_FCAB_Cx200000_22_ExteriorLights), 268435456=Cx10000000_29_SteeringColumnLock (CM_NM_CID_FCAB_Cx10000000_29_SteeringColumnLock), 1=Cx1_01_CarWakeUp (CM_NM_CID_FCAB_Cx1_01_CarWakeUp), 17179869184=Cx400000000_35_ExteriorSound (CM_NM_CID_FCAB_Cx400000000_35_ExteriorSound), 1024=Cx400_11_Chassis (CM_NM_CID_FCAB_Cx400_11_Chassis), 17592186044416=Cx100000000000_45_Diagnosis_Comfort (CM_NM_CID_FCAB_Cx100000000000_45_Diagnosis_Comfort), 524288=Cx80000_20_OptionalComfort (CM_NM_CID_FCAB_Cx80000_20_OptionalComfort), 281474976710656=Cx1000000000000_49_reserved (CM_NM_CID_FCAB_Cx1000000000000_49_reserved) (49_<reserved>), 2048=Cx800_12_GearSelector (CM_NM_CID_FCAB_Cx800_12_GearSelector), 64=Cx40_07_Basefunction_CrossSection (CM_NM_CID_FCAB_Cx40_07_Basefunction_CrossSection), 134217728=Cx8000000_28_OnboardTester_DataCollector (CM_NM_CID_FCAB_Cx8000000_28_OnboardTester_DataCollector), 536870912=Cx20000000_30_EnergyManagement (CM_NM_CID_FCAB_Cx20000000_30_EnergyManagement), 32=Cx20_06_Basefunction_ComfortLight (CM_NM_CID_FCAB_Cx20_06_Basefunction_ComfortLight), 36028797018963968=Cx80000000000000_56_ChargingStatus (CM_NM_CID_FCAB_Cx80000000000000_56_ChargingStatus), 18014398509481984=Cx40000000000000_55_Dimming (CM_NM_CID_FCAB_Cx40000000000000_55_Dimming), 9007199254740992=Cx20000000000000_54_reserved (CM_NM_CID_FCAB_Cx20000000000000_54_reserved) (54_<reserved>)}, range raw 0..36028797018963968, transfer-property=TRIGGERED-ON-CHANGE  # FCAB = Funktions-Cluster-Aktiv-Bits
          signal NM_CID_SNI_10_XIX_NM_CID_XIX_HCP3_CANFD01: start 128, 10 bit, little-endian, data-type-policy=OVERRIDE, i-signal-type=PRIMITIVE, init-value=290, base-type=BT_NM_CID_SNI_10, compu {290=Cx122_CID_SNI (CM_NM_CID_SNI_10_Cx122_CID_SNI)}, range raw 290, transfer-property=TRIGGERED  # Source Node-Identifier (SNI) identifiziert den Sender der NM-Botschaft (Knotenadresse) eindeutig im Fahrzeug
          signal NM_CID_NM_State_XIX_NM_CID_XIX_HCP3_CANFD01: start 144, 6 bit, little-endian, data-type-policy=OVERRIDE, i-signal-type=PRIMITIVE, init-value=0, base-type=BT_NM_CID_NM_State, compu {32=Cx20_reserved (CM_NM_CID_NM_State_Cx20_reserved), 1=Cx1_NM_RM_aus_BSM (CM_NM_CID_NM_State_Cx1_NM_RM_aus_BSM), 4=Cx4_NM_NO_aus_RM (CM_NM_CID_NM_State_Cx4_NM_NO_aus_RM), 0=Cx0_Init (CM_NM_CID_NM_State_Cx0_Init), 2=Cx2_NM_RM_aus_PBSM (CM_NM_CID_NM_State_Cx2_NM_RM_aus_PBSM), 8=Cx8_NM_NO_aus_RS (CM_NM_CID_NM_State_Cx8_NM_NO_aus_RS), 16=Cx10_reserved (CM_NM_CID_NM_State_Cx10_reserved)}, range raw 0..32, transfer-property=TRIGGERED  # 1 = Zustand Repeat Message (<-- Bus-Sleep Mode) 2 = Zustand Repeat Message (<-- Prepare Bus-Sleep Mode) 4 = Zustand Normal Operation (<-- Repeat Message) 8 = Zustand Normal Operation (<-- Ready Sleep)
          signal NM_CID_UDS_CC_XIX_NM_CID_XIX_HCP3_CANFD01: start 151, 1 bit, little-endian, data-type-policy=OVERRIDE, i-signal-type=PRIMITIVE, init-value=0, base-type=BT_NM_CID_UDS_CC, compu {1=Cx1_CC_aktiv (CM_NM_CID_UDS_CC_Cx1_CC_aktiv), 0=Cx0_Inaktiv (CM_NM_CID_UDS_CC_Cx0_Inaktiv)}, range raw 0..1, transfer-property=TRIGGERED  # Funktionseinschränkung aufgrund aktivem UDS-Communication Control, siehe VW80124
          signal NM_CID_Wakeup_V12_XIX_NM_CID_XIX_HCP3_CANFD01: start 152, 8 bit, little-endian, data-type-policy=OVERRIDE, i-signal-type=PRIMITIVE, init-value=0, base-type=BT_NM_CID_Wakeup_V12, compu {2=Cx2_KL15_HW (CM_NM_CID_Wakeup_V12_Cx2_KL15_HW), 0=Cx0_Peripherie_Wakeup_Ursache_nicht_bekannt (CM_NM_CID_Wakeup_V12_Cx0_Peripherie_Wakeup_Ursache_nicht_bekannt), 1=Cx1_Bus_Wakeup (CM_NM_CID_Wakeup_V12_Cx1_Bus_Wakeup)}, range raw 0..2, transfer-property=TRIGGERED  # enthält die Weckursache; stehen mehrere Weckursachen parallel an, dann muss der kleinste Wert übertragen werden
          signal NM_CID_NM_aktiv_KL15_XIX_NM_CID_XIX_HCP3_CANFD01: start 160, 1 bit, little-endian, data-type-policy=OVERRIDE, i-signal-type=PRIMITIVE, init-value=0, base-type=BT_NM_CID_NM_aktiv_KL15, compu {1=Cx1_KL15_EIN (CM_NM_CID_NM_aktiv_KL15_Cx1_KL15_EIN), 0=Cx0_Inaktiv (CM_NM_CID_NM_aktiv_KL15_Cx0_Inaktiv)}, range raw 0..1, transfer-property=TRIGGERED  # Steuergerät hat KL15-EIN erkannt
          signal NM_CID_NM_aktiv_Diag_XIX_NM_CID_XIX_HCP3_CANFD01: start 161, 1 bit, little-endian, data-type-policy=OVERRIDE, i-signal-type=PRIMITIVE, init-value=0, base-type=BT_NM_CID_NM_aktiv_Diag, compu {1=Cx1_Diagnose_aktiv (CM_NM_CID_NM_aktiv_Diag_Cx1_Diagnose_aktiv), 0=Cx0_Inaktiv (CM_NM_CID_NM_aktiv_Diag_Cx0_Inaktiv)}, range raw 0..1, transfer-property=TRIGGERED  # Diagnose befindet sich nach VW80124 in einer NonDefaultDiagnostic-Session, z.B. ExtendedDiagnostic-Session
          signal NM_CID_NM_aktiv_Tmin_XIX_NM_CID_XIX_HCP3_CANFD01: start 162, 1 bit, little-endian, data-type-policy=OVERRIDE, i-signal-type=PRIMITIVE, init-value=0, base-type=BT_NM_CID_NM_aktiv_Tmin, compu {1=Cx1_Mindestaktivzeit (CM_NM_CID_NM_aktiv_Tmin_Cx1_Mindestaktivzeit), 0=Cx0_Inaktiv (CM_NM_CID_NM_aktiv_Tmin_Cx0_Inaktiv)}, range raw 0..1, transfer-property=TRIGGERED  # Mindestaktivzeit ist noch nicht abgelaufen (bei jedem Weckereignis wird die Mindestaktivzeit neu gestartet)
      frame NM_DispKBI_FS_XIX_HCP3_CANFD01: id 0x1B000109, to HCP3_IONode, frame-length=24, can-addressing-mode=EXTENDED, can-frame-rx-behavior=CAN-FD, can-frame-tx-behavior=CAN-FD, rx-identifier-range={lower-can-id=452984832, upper-can-id=452985855}
        nm pdu NM_DispKBI_FS_XIX_HCP3_CANFD01: length=24, unused-bit-pattern=0
          signal NM_DispKBI_FS_CBV_AWB_XIX_NM_DispKBI_FS_XIX_HCP3_CANFD01: start 4, 1 bit, little-endian, data-type-policy=OVERRIDE, i-signal-type=PRIMITIVE, init-value=0, base-type=BT_NM_DispKBI_FS_CBV_AWB, compu {1=Cx1_Aktiver_WakeUp (CM_NM_DispKBI_FS_CBV_AWB_Cx1_Aktiver_WakeUp), 0=Cx0_Passiver_WakeUp (CM_NM_DispKBI_FS_CBV_AWB_Cx0_Passiver_WakeUp)}, range raw 0..1, transfer-property=TRIGGERED  # Das Signal ist zu setzen, wenn das SG aktiv den Bus geweckt hat
          signal NM_DispKBI_FS_CBV_CRI_XIX_NM_DispKBI_FS_XIX_HCP3_CANFD01: start 6, 1 bit, little-endian, data-type-policy=OVERRIDE, i-signal-type=PRIMITIVE, init-value=1, base-type=BT_NM_DispKBI_FS_CBV_CRI, compu {1=Cx1_NM_mit_Clusteranforderungen (CM_NM_DispKBI_FS_CBV_CRI_Cx1_NM_mit_Clusteranforderungen), 0=Cx0_NM_ohne_Clusteranforderungen (CM_NM_DispKBI_FS_CBV_CRI_Cx0_NM_ohne_Clusteranforderungen)}, range raw 0..1, transfer-property=TRIGGERED  # Das Signal ist dauerhaft gesetzt, wenn das NM-Layout Cluster- Anforderungen enthält
          signal NM_DispKBI_FS_FCAB_XIX_NM_DispKBI_FS_XIX_HCP3_CANFD01: start 8, 56 bit, opaque, data-type-policy=OVERRIDE, i-signal-type=ARRAY, init-value=7 x 0b00000000, base-type=BT_NM_DispKBI_FS_FCAB, compu {2199023255552=Cx20000000000_42_Diagnosis_FlexRay (CM_NM_DispKBI_FS_FCAB_Cx20000000000_42_Diagnosis_FlexRay), 8=Cx8_04_Basefunction_DrivingAssistance (CM_NM_DispKBI_FS_FCAB_Cx8_04_Basefunction_DrivingAssistance), 2097152=Cx200000_22_ExteriorLights (CM_NM_DispKBI_FS_FCAB_Cx200000_22_ExteriorLights), 8589934592=Cx200000000_34_GPS_Localization (CM_NM_DispKBI_FS_FCAB_Cx200000000_34_GPS_Localization), 9007199254740992=Cx20000000000000_54_reserved (CM_NM_DispKBI_FS_FCAB_Cx20000000000000_54_reserved) (54_<reserved>), 281474976710656=Cx1000000000000_49_reserved (CM_NM_DispKBI_FS_FCAB_Cx1000000000000_49_reserved) (49_<reserved>), 0=Cx0_Init (CM_NM_DispKBI_FS_FCAB_Cx0_Init), 32768=Cx8000_16_InfotainmentDisplay (CM_NM_DispKBI_FS_FCAB_Cx8000_16_InfotainmentDisplay), 8796093022208=Cx80000000000_44_Diagnosis_Infotainment (CM_NM_DispKBI_FS_FCAB_Cx80000000000_44_Diagnosis_Infotainment), 2048=Cx800_12_GearSelector (CM_NM_DispKBI_FS_FCAB_Cx800_12_GearSelector), 140737488355328=Cx800000000000_48_Diagnosis_ClimateTmeLINs (CM_NM_DispKBI_FS_FCAB_Cx800000000000_48_Diagnosis_ClimateTmeLINs), 16777216=Cx1000000_25_AccessSystemSensors (CM_NM_DispKBI_FS_FCAB_Cx1000000_25_AccessSystemSensors), 34359738368=Cx800000000_36_Preheater (CM_NM_DispKBI_FS_FCAB_Cx800000000_36_Preheater), 524288=Cx80000_20_OptionalComfort (CM_NM_DispKBI_FS_FCAB_Cx80000_20_OptionalComfort), 32=Cx20_06_Basefunction_ComfortLight (CM_NM_DispKBI_FS_FCAB_Cx20_06_Basefunction_ComfortLight), 16=Cx10_05_Basefunction_Infotainment (CM_NM_DispKBI_FS_FCAB_Cx10_05_Basefunction_Infotainment), 1024=Cx400_11_Chassis (CM_NM_DispKBI_FS_FCAB_Cx400_11_Chassis), 268435456=Cx10000000_29_SteeringColumnLock (CM_NM_DispKBI_FS_FCAB_Cx10000000_29_SteeringColumnLock), 36028797018963968=Cx80000000000000_56_ChargingStatus (CM_NM_DispKBI_FS_FCAB_Cx80000000000000_56_ChargingStatus), 256=Cx100_09_reserved (CM_NM_DispKBI_FS_FCAB_Cx100_09_reserved) (09_<reserved>), 17592186044416=Cx100000000000_45_Diagnosis_Comfort (CM_NM_DispKBI_FS_FCAB_Cx100000000000_45_Diagnosis_Comfort), 16384=Cx4000_15_InstrumentclusterDisplay (CM_NM_DispKBI_FS_FCAB_Cx4000_15_InstrumentclusterDisplay), 1=Cx1_01_CarWakeUp (CM_NM_DispKBI_FS_FCAB_Cx1_01_CarWakeUp), 4503599627370496=Cx10000000000000_53_Lock_Unlock (CM_NM_DispKBI_FS_FCAB_Cx10000000000000_53_Lock_Unlock), 1073741824=Cx40000000_31_MultifunctionalSteeringWheel (CM_NM_DispKBI_FS_FCAB_Cx40000000_31_MultifunctionalSteeringWheel), 2147483648=Cx80000000_32_OnlineAccess (CM_NM_DispKBI_FS_FCAB_Cx80000000_32_OnlineAccess), 536870912=Cx20000000_30_EnergyManagement (CM_NM_DispKBI_FS_FCAB_Cx20000000_30_EnergyManagement), 18014398509481984=Cx40000000000000_55_Dimming (CM_NM_DispKBI_FS_FCAB_Cx40000000000000_55_Dimming), 65536=Cx10000_17_Audio (CM_NM_DispKBI_FS_FCAB_Cx10000_17_Audio), 68719476736=Cx1000000000_37_HighVoltage_WirelessChargingStation (CM_NM_DispKBI_FS_FCAB_Cx1000000000_37_HighVoltage_WirelessChargingStation), 2=Cx2_02_Basefunction_Powertrain (CM_NM_DispKBI_FS_FCAB_Cx2_02_Basefunction_Powertrain), 17179869184=Cx400000000_35_ExteriorSound (CM_NM_DispKBI_FS_FCAB_Cx400000000_35_ExteriorSound), 8192=Cx2000_14_InfotainmentExtensions (CM_NM_DispKBI_FS_FCAB_Cx2000_14_InfotainmentExtensions), 4096=Cx1000_13_Airbag (CM_NM_DispKBI_FS_FCAB_Cx1000_13_Airbag), 262144=Cx40000_19_Doors_Hatches (CM_NM_DispKBI_FS_FCAB_Cx40000_19_Doors_Hatches), 70368744177664=Cx400000000000_47_Diagnosis_ComfortLINs (CM_NM_DispKBI_FS_FCAB_Cx400000000000_47_Diagnosis_ComfortLINs), 67108864=Cx4000000_27_Timemaster_Timer (CM_NM_DispKBI_FS_FCAB_Cx4000000_27_Timemaster_Timer), 35184372088832=Cx200000000000_46_Diagnosis_Light (CM_NM_DispKBI_FS_FCAB_Cx200000000000_46_Diagnosis_Light), 33554432=Cx2000000_26_HighVoltage_Charging (CM_NM_DispKBI_FS_FCAB_Cx2000000_26_HighVoltage_Charging), 549755813888=Cx8000000000_40_Diagnosis_Energy (CM_NM_DispKBI_FS_FCAB_Cx8000000000_40_Diagnosis_Energy), 64=Cx40_07_Basefunction_CrossSection (CM_NM_DispKBI_FS_FCAB_Cx40_07_Basefunction_CrossSection), 131072=Cx20000_18_VirtualSideMirrors (CM_NM_DispKBI_FS_FCAB_Cx20000_18_VirtualSideMirrors), 1048576=Cx100000_21_AirSuspension (CM_NM_DispKBI_FS_FCAB_Cx100000_21_AirSuspension), 134217728=Cx8000000_28_OnboardTester_DataCollector (CM_NM_DispKBI_FS_FCAB_Cx8000000_28_OnboardTester_DataCollector), 512=Cx200_10_Powertrain (CM_NM_DispKBI_FS_FCAB_Cx200_10_Powertrain), 4194304=Cx400000_23_Climate (CM_NM_DispKBI_FS_FCAB_Cx400000_23_Climate), 128=Cx80_08_Basefunction_Connectivity (CM_NM_DispKBI_FS_FCAB_Cx80_08_Basefunction_Connectivity), 4398046511104=Cx40000000000_43_Diagnosis_DrivingAssistance (CM_NM_DispKBI_FS_FCAB_Cx40000000000_43_Diagnosis_DrivingAssistance), 4=Cx4_03_Basefunction_Chassis (CM_NM_DispKBI_FS_FCAB_Cx4_03_Basefunction_Chassis), 8388608=Cx800000_24_ThermoManagement (CM_NM_DispKBI_FS_FCAB_Cx800000_24_ThermoManagement), 1099511627776=Cx10000000000_41_Diagnosis_Powertrain (CM_NM_DispKBI_FS_FCAB_Cx10000000000_41_Diagnosis_Powertrain), 4294967296=Cx100000000_33_ExternalWirelessCommunication (CM_NM_DispKBI_FS_FCAB_Cx100000000_33_ExternalWirelessCommunication)}, range raw 0..36028797018963968, transfer-property=TRIGGERED-ON-CHANGE  # FCAB = Funktions-Cluster-Aktiv-Bits
          signal NM_DispKBI_FS_SNI_10_XIX_NM_DispKBI_FS_XIX_HCP3_CANFD01: start 128, 10 bit, little-endian, data-type-policy=OVERRIDE, i-signal-type=PRIMITIVE, init-value=265, base-type=BT_NM_DispKBI_FS_SNI_10, compu {265=Cx109_DispKBI_FS_SNI (CM_NM_DispKBI_FS_SNI_10_Cx109_DispKBI_FS_SNI)}, range raw 265, transfer-property=TRIGGERED  # Source Node-Identifier (SNI) identifiziert den Sender der NM-Botschaft (Knotenadresse) eindeutig im Fahrzeug
          signal NM_DispKBI_FS_NM_State_XIX_NM_DispKBI_FS_XIX_HCP3_CANFD01: start 144, 6 bit, little-endian, data-type-policy=OVERRIDE, i-signal-type=PRIMITIVE, init-value=0, base-type=BT_NM_DispKBI_FS_NM_State, compu {1=Cx1_NM_RM_aus_BSM (CM_NM_DispKBI_FS_NM_State_Cx1_NM_RM_aus_BSM), 0=Cx0_Init (CM_NM_DispKBI_FS_NM_State_Cx0_Init), 16=Cx10_reserved (CM_NM_DispKBI_FS_NM_State_Cx10_reserved), 2=Cx2_NM_RM_aus_PBSM (CM_NM_DispKBI_FS_NM_State_Cx2_NM_RM_aus_PBSM), 8=Cx8_NM_NO_aus_RS (CM_NM_DispKBI_FS_NM_State_Cx8_NM_NO_aus_RS), 4=Cx4_NM_NO_aus_RM (CM_NM_DispKBI_FS_NM_State_Cx4_NM_NO_aus_RM), 32=Cx20_reserved (CM_NM_DispKBI_FS_NM_State_Cx20_reserved)}, range raw 0..32, transfer-property=TRIGGERED  # 1 = Zustand Repeat Message (<-- Bus-Sleep Mode) 2 = Zustand Repeat Message (<-- Prepare Bus-Sleep Mode) 4 = Zustand Normal Operation (<-- Repeat Message) 8 = Zustand Normal Operation (<-- Ready Sleep)
          signal NM_DispKBI_FS_UDS_CC_XIX_NM_DispKBI_FS_XIX_HCP3_CANFD01: start 151, 1 bit, little-endian, data-type-policy=OVERRIDE, i-signal-type=PRIMITIVE, init-value=0, base-type=BT_NM_DispKBI_FS_UDS_CC, compu {0=Cx0_Inaktiv (CM_NM_DispKBI_FS_UDS_CC_Cx0_Inaktiv), 1=Cx1_CC_aktiv (CM_NM_DispKBI_FS_UDS_CC_Cx1_CC_aktiv)}, range raw 0..1, transfer-property=TRIGGERED  # Funktionseinschränkung aufgrund aktivem UDS-Communication Control, siehe VW80124
          signal NM_DispKBI_FS_Wakeup_V12_XIX_NM_DispKBI_FS_XIX_HCP3_CANFD01: start 152, 8 bit, little-endian, data-type-policy=OVERRIDE, i-signal-type=PRIMITIVE, init-value=0, base-type=BT_NM_DispKBI_FS_Wakeup_V12, compu {1=Cx1_Bus_Wakeup (CM_NM_DispKBI_FS_Wakeup_V12_Cx1_Bus_Wakeup), 3=Cx3_KL30_Reset (CM_NM_DispKBI_FS_Wakeup_V12_Cx3_KL30_Reset), 2=Cx2_KL15_HW (CM_NM_DispKBI_FS_Wakeup_V12_Cx2_KL15_HW), 0=Cx0_Peripherie_Wakeup_Ursache_nicht_bekannt (CM_NM_DispKBI_FS_Wakeup_V12_Cx0_Peripherie_Wakeup_Ursache_nicht_bekannt)}, range raw 0..3, transfer-property=TRIGGERED  # enthält die Weckursache; stehen mehrere Weckursachen parallel an, dann muss der kleinste Wert übertragen werden
          signal NM_DispKBI_FS_NM_aktiv_Diag_XIX_NM_DispKBI_FS_XIX_HCP3_CANFD01: start 160, 1 bit, little-endian, data-type-policy=OVERRIDE, i-signal-type=PRIMITIVE, init-value=0, base-type=BT_NM_DispKBI_FS_NM_aktiv_Diag, compu {1=Cx1_Diagnose_aktiv (CM_NM_DispKBI_FS_NM_aktiv_Diag_Cx1_Diagnose_aktiv), 0=Cx0_Inaktiv (CM_NM_DispKBI_FS_NM_aktiv_Diag_Cx0_Inaktiv)}, range raw 0..1, transfer-property=TRIGGERED  # Diagnose befindet sich nach VW80124 in einer NonDefaultDiagnostic-Session, z.B. ExtendedDiagnostic-Session
          signal NM_DispKBI_FS_NM_aktiv_KL15_XIX_NM_DispKBI_FS_XIX_HCP3_CANFD01: start 161, 1 bit, little-endian, data-type-policy=OVERRIDE, i-signal-type=PRIMITIVE, init-value=0, base-type=BT_NM_DispKBI_FS_NM_aktiv_KL15, compu {0=Cx0_Inaktiv (CM_NM_DispKBI_FS_NM_aktiv_KL15_Cx0_Inaktiv), 1=Cx1_KL15_EIN (CM_NM_DispKBI_FS_NM_aktiv_KL15_Cx1_KL15_EIN)}, range raw 0..1, transfer-property=TRIGGERED  # Steuergerät hat KL15-EIN erkannt
          signal NM_DispKBI_FS_NM_aktiv_Tmin_XIX_NM_DispKBI_FS_XIX_HCP3_CANFD01: start 162, 1 bit, little-endian, data-type-policy=OVERRIDE, i-signal-type=PRIMITIVE, init-value=0, base-type=BT_NM_DispKBI_FS_NM_aktiv_Tmin, compu {1=Cx1_Mindestaktivzeit (CM_NM_DispKBI_FS_NM_aktiv_Tmin_Cx1_Mindestaktivzeit), 0=Cx0_Inaktiv (CM_NM_DispKBI_FS_NM_aktiv_Tmin_Cx0_Inaktiv)}, range raw 0..1, transfer-property=TRIGGERED  # Mindestaktivzeit ist noch nicht abgelaufen (bei jedem Weckereignis wird die Mindestaktivzeit neu gestartet)
          signal NM_aktiv_KL30_Reset_Kombi_XIX_NM_DispKBI_FS_XIX_HCP3_CANFD01: start 163, 1 bit, little-endian, data-type-policy=OVERRIDE, i-signal-type=PRIMITIVE, init-value=0, base-type=BT_NM_aktiv_KL30_Reset_Kombi, compu {0=Cx0_Inaktiv (CM_NM_aktiv_KL30_Reset_Kombi_Cx0_Inaktiv), 1=Cx1_Aktiv (CM_NM_aktiv_KL30_Reset_Kombi_Cx1_Aktiv)}, range raw 0..1, transfer-property=TRIGGERED  # Bei Kontaktierung der Betriebsspannung Kl.30 wird das Kombiinstrument initialiert. (
      frame NM_HUD_XIX_HCP3_CANFD01: id 0x1B00001B, to HCP3_IONode, frame-length=24, can-addressing-mode=EXTENDED, can-frame-rx-behavior=CAN-FD, can-frame-tx-behavior=CAN-FD, rx-identifier-range={lower-can-id=452984832, upper-can-id=452985855}
        nm pdu NM_HUD_XIX_HCP3_CANFD01: length=24, unused-bit-pattern=0
          signal NM_HUD_CBV_AWB_XIX_NM_HUD_XIX_HCP3_CANFD01: start 4, 1 bit, little-endian, data-type-policy=OVERRIDE, i-signal-type=PRIMITIVE, init-value=0, base-type=BT_NM_HUD_CBV_AWB, compu {1=Cx1_Aktiver_WakeUp (CM_NM_HUD_CBV_AWB_Cx1_Aktiver_WakeUp), 0=Cx0_Passiver_WakeUp (CM_NM_HUD_CBV_AWB_Cx0_Passiver_WakeUp)}, range raw 0..1, transfer-property=TRIGGERED  # Das Signal ist zu setzen, wenn das SG aktiv den Bus geweckt hat 0 = Passiver_WakeUp = SG hat das Netzwerk nicht aktiv geweckt 1 = Akitiver_WakeUp = SG hat das Netzwerk aktiv geweckt
          signal NM_HUD_CBV_CRI_XIX_NM_HUD_XIX_HCP3_CANFD01: start 6, 1 bit, little-endian, data-type-policy=OVERRIDE, i-signal-type=PRIMITIVE, init-value=1, base-type=BT_NM_HUD_CBV_CRI, compu {1=Cx1_NM_mit_Clusteranforderungen (CM_NM_HUD_CBV_CRI_Cx1_NM_mit_Clusteranforderungen), 0=Cx0_NM_ohne_Clusteranforderungen (CM_NM_HUD_CBV_CRI_Cx0_NM_ohne_Clusteranforderungen)}, range raw 0..1, transfer-property=TRIGGERED  # Das Signal ist dauerhaft gesetzt, wenn das NM-Layout Cluster- Anforderungen enthält
          signal NM_HUD_FCAB_XIX_NM_HUD_XIX_HCP3_CANFD01: start 8, 56 bit, opaque, data-type-policy=OVERRIDE, i-signal-type=ARRAY, init-value=7 x 0b00000000, base-type=BT_NM_HUD_FCAB, compu {17179869184=Cx400000000_35_ExteriorSound (CM_NM_HUD_FCAB_Cx400000000_35_ExteriorSound), 4194304=Cx400000_23_Climate (CM_NM_HUD_FCAB_Cx400000_23_Climate), 1048576=Cx100000_21_AirSuspension (CM_NM_HUD_FCAB_Cx100000_21_AirSuspension), 32=Cx20_06_Basefunction_ComfortLight (CM_NM_HUD_FCAB_Cx20_06_Basefunction_ComfortLight), 0=Cx0_Init (CM_NM_HUD_FCAB_Cx0_Init), 1=Cx1_01_CarWakeUp (CM_NM_HUD_FCAB_Cx1_01_CarWakeUp), 2=Cx2_02_Basefunction_Powertrain (CM_NM_HUD_FCAB_Cx2_02_Basefunction_Powertrain), 65536=Cx10000_17_Audio (CM_NM_HUD_FCAB_Cx10000_17_Audio), 268435456=Cx10000000_29_SteeringColumnLock (CM_NM_HUD_FCAB_Cx10000000_29_SteeringColumnLock), 8589934592=Cx200000000_34_GPS_Localization (CM_NM_HUD_FCAB_Cx200000000_34_GPS_Localization), 4398046511104=Cx40000000000_43_Diagnosis_DrivingAssistance (CM_NM_HUD_FCAB_Cx40000000000_43_Diagnosis_DrivingAssistance), 524288=Cx80000_20_OptionalComfort (CM_NM_HUD_FCAB_Cx80000_20_OptionalComfort), 4503599627370496=Cx10000000000000_53_Lock_Unlock (CM_NM_HUD_FCAB_Cx10000000000000_53_Lock_Unlock), 68719476736=Cx1000000000_37_HighVoltage_WirelessChargingStation (CM_NM_HUD_FCAB_Cx1000000000_37_HighVoltage_WirelessChargingStation), 1073741824=Cx40000000_31_MultifunctionalSteeringWheel (CM_NM_HUD_FCAB_Cx40000000_31_MultifunctionalSteeringWheel), 131072=Cx20000_18_VirtualSideMirrors (CM_NM_HUD_FCAB_Cx20000_18_VirtualSideMirrors), 8=Cx8_04_Basefunction_DrivingAssistance (CM_NM_HUD_FCAB_Cx8_04_Basefunction_DrivingAssistance), 2199023255552=Cx20000000000_42_Diagnosis_FlexRay (CM_NM_HUD_FCAB_Cx20000000000_42_Diagnosis_FlexRay), 17592186044416=Cx100000000000_45_Diagnosis_Comfort (CM_NM_HUD_FCAB_Cx100000000000_45_Diagnosis_Comfort), 2147483648=Cx80000000_32_OnlineAccess (CM_NM_HUD_FCAB_Cx80000000_32_OnlineAccess), 536870912=Cx20000000_30_EnergyManagement (CM_NM_HUD_FCAB_Cx20000000_30_EnergyManagement), 1099511627776=Cx10000000000_41_Diagnosis_Powertrain (CM_NM_HUD_FCAB_Cx10000000000_41_Diagnosis_Powertrain), 1024=Cx400_11_Chassis (CM_NM_HUD_FCAB_Cx400_11_Chassis), 8388608=Cx800000_24_ThermoManagement (CM_NM_HUD_FCAB_Cx800000_24_ThermoManagement), 140737488355328=Cx800000000000_48_Diagnosis_ClimateTmeLINs (CM_NM_HUD_FCAB_Cx800000000000_48_Diagnosis_ClimateTmeLINs), 134217728=Cx8000000_28_OnboardTester_DataCollector (CM_NM_HUD_FCAB_Cx8000000_28_OnboardTester_DataCollector), 8796093022208=Cx80000000000_44_Diagnosis_Infotainment (CM_NM_HUD_FCAB_Cx80000000000_44_Diagnosis_Infotainment), 256=Cx100_09_reserved (CM_NM_HUD_FCAB_Cx100_09_reserved) (09_<reserved>), 70368744177664=Cx400000000000_47_Diagnosis_ComfortLINs (CM_NM_HUD_FCAB_Cx400000000000_47_Diagnosis_ComfortLINs), 16777216=Cx1000000_25_AccessSystemSensors (CM_NM_HUD_FCAB_Cx1000000_25_AccessSystemSensors), 281474976710656=Cx1000000000000_49_reserved (CM_NM_HUD_FCAB_Cx1000000000000_49_reserved) (49_<reserved>), 35184372088832=Cx200000000000_46_Diagnosis_Light (CM_NM_HUD_FCAB_Cx200000000000_46_Diagnosis_Light), 4294967296=Cx100000000_33_ExternalWirelessCommunication (CM_NM_HUD_FCAB_Cx100000000_33_ExternalWirelessCommunication), 9007199254740992=Cx20000000000000_54_reserved (CM_NM_HUD_FCAB_Cx20000000000000_54_reserved) (54_<reserved>), 32768=Cx8000_16_InfotainmentDisplay (CM_NM_HUD_FCAB_Cx8000_16_InfotainmentDisplay), 36028797018963968=Cx80000000000000_56_ChargingStatus (CM_NM_HUD_FCAB_Cx80000000000000_56_ChargingStatus), 33554432=Cx2000000_26_HighVoltage_Charging (CM_NM_HUD_FCAB_Cx2000000_26_HighVoltage_Charging), 512=Cx200_10_Powertrain (CM_NM_HUD_FCAB_Cx200_10_Powertrain), 2048=Cx800_12_GearSelector (CM_NM_HUD_FCAB_Cx800_12_GearSelector), 18014398509481984=Cx40000000000000_55_Dimming (CM_NM_HUD_FCAB_Cx40000000000000_55_Dimming), 16384=Cx4000_15_InstrumentclusterDisplay (CM_NM_HUD_FCAB_Cx4000_15_InstrumentclusterDisplay), 16=Cx10_05_Basefunction_Infotainment (CM_NM_HUD_FCAB_Cx10_05_Basefunction_Infotainment), 8192=Cx2000_14_InfotainmentExtensions (CM_NM_HUD_FCAB_Cx2000_14_InfotainmentExtensions), 128=Cx80_08_Basefunction_Connectivity (CM_NM_HUD_FCAB_Cx80_08_Basefunction_Connectivity), 34359738368=Cx800000000_36_Preheater (CM_NM_HUD_FCAB_Cx800000000_36_Preheater), 64=Cx40_07_Basefunction_CrossSection (CM_NM_HUD_FCAB_Cx40_07_Basefunction_CrossSection), 2097152=Cx200000_22_ExteriorLights (CM_NM_HUD_FCAB_Cx200000_22_ExteriorLights), 4=Cx4_03_Basefunction_Chassis (CM_NM_HUD_FCAB_Cx4_03_Basefunction_Chassis), 262144=Cx40000_19_Doors_Hatches (CM_NM_HUD_FCAB_Cx40000_19_Doors_Hatches), 549755813888=Cx8000000000_40_Diagnosis_Energy (CM_NM_HUD_FCAB_Cx8000000000_40_Diagnosis_Energy), 67108864=Cx4000000_27_Timemaster_Timer (CM_NM_HUD_FCAB_Cx4000000_27_Timemaster_Timer), 4096=Cx1000_13_Airbag (CM_NM_HUD_FCAB_Cx1000_13_Airbag)}, range raw 0..36028797018963968, transfer-property=TRIGGERED-ON-CHANGE  # FCAB = Funktions-Cluster-Aktiv-Bits
          signal NM_HUD_SNI_10_XIX_NM_HUD_XIX_HCP3_CANFD01: start 128, 10 bit, little-endian, data-type-policy=OVERRIDE, i-signal-type=PRIMITIVE, init-value=27, base-type=BT_NM_HUD_SNI_10, compu {27=Cx1b_HUD_SNI (CM_NM_HUD_SNI_10_Cx1b_HUD_SNI)}, range raw 27, transfer-property=TRIGGERED  # Source Node-Identifier (SNI) identifiziert den Sender der NM-Botschaft (Knotenadresse) eindeutig im Fahrzeug
          signal NM_HUD_NM_State_XIX_NM_HUD_XIX_HCP3_CANFD01: start 144, 6 bit, little-endian, data-type-policy=OVERRIDE, i-signal-type=PRIMITIVE, init-value=0, base-type=BT_NM_HUD_NM_State, compu {4=Cx4_NM_NO_aus_RM (CM_NM_HUD_NM_State_Cx4_NM_NO_aus_RM), 32=Cx20_reserved (CM_NM_HUD_NM_State_Cx20_reserved), 16=Cx10_reserved (CM_NM_HUD_NM_State_Cx10_reserved), 0=Cx0_Init (CM_NM_HUD_NM_State_Cx0_Init), 2=Cx2_NM_RM_aus_PBSM (CM_NM_HUD_NM_State_Cx2_NM_RM_aus_PBSM), 1=Cx1_NM_RM_aus_BSM (CM_NM_HUD_NM_State_Cx1_NM_RM_aus_BSM), 8=Cx8_NM_NO_aus_RS (CM_NM_HUD_NM_State_Cx8_NM_NO_aus_RS)}, range raw 0..32, transfer-property=TRIGGERED  # 1 = Zustand Repeat Message (<-- Bus-Sleep Mode) 2 = Zustand Repeat Message (<-- Prepare Bus-Sleep Mode) 4 = Zustand Normal Operation (<-- Repeat Message) 8 = Zustand Normal Operation (<-- Ready Sleep)
          signal NM_HUD_UDS_CC_XIX_NM_HUD_XIX_HCP3_CANFD01: start 151, 1 bit, little-endian, data-type-policy=OVERRIDE, i-signal-type=PRIMITIVE, init-value=0, base-type=BT_NM_HUD_UDS_CC, compu {0=Cx0_Inaktiv (CM_NM_HUD_UDS_CC_Cx0_Inaktiv), 1=Cx1_CC_aktiv (CM_NM_HUD_UDS_CC_Cx1_CC_aktiv)}, range raw 0..1, transfer-property=TRIGGERED  # Funktionseinschränkung aufgrund aktivem UDS-Communication Control, siehe VW80124
          signal NM_HUD_Wakeup_V12_XIX_NM_HUD_XIX_HCP3_CANFD01: start 152, 8 bit, little-endian, data-type-policy=OVERRIDE, i-signal-type=PRIMITIVE, init-value=0, base-type=BT_NM_HUD_Wakeup_V12, compu {2=Cx2_KL15_HW (CM_NM_HUD_Wakeup_V12_Cx2_KL15_HW), 1=Cx1_Bus_Wakeup (CM_NM_HUD_Wakeup_V12_Cx1_Bus_Wakeup), 0=Cx0_Peripherie_Wakeup_Ursache_nicht_bekannt (CM_NM_HUD_Wakeup_V12_Cx0_Peripherie_Wakeup_Ursache_nicht_bekannt)}, range raw 0..2, transfer-property=TRIGGERED  # enthält die Weckursache; stehen mehrere Weckursachen parallel an, dann muss der kleinste Wert übertragen werden
          signal NM_HUD_NM_aktiv_KL15_XIX_NM_HUD_XIX_HCP3_CANFD01: start 160, 1 bit, little-endian, data-type-policy=OVERRIDE, i-signal-type=PRIMITIVE, init-value=0, base-type=BT_NM_HUD_NM_aktiv_KL15, compu {0=Cx0_Inaktiv (CM_NM_HUD_NM_aktiv_KL15_Cx0_Inaktiv), 1=Cx1_KL15_EIN (CM_NM_HUD_NM_aktiv_KL15_Cx1_KL15_EIN)}, range raw 0..1, transfer-property=TRIGGERED  # Steuergerät hat KL15-EIN erkannt
          signal NM_HUD_NM_aktiv_Diag_XIX_NM_HUD_XIX_HCP3_CANFD01: start 161, 1 bit, little-endian, data-type-policy=OVERRIDE, i-signal-type=PRIMITIVE, init-value=0, base-type=BT_NM_HUD_NM_aktiv_Diag, compu {0=Cx0_Inaktiv (CM_NM_HUD_NM_aktiv_Diag_Cx0_Inaktiv), 1=Cx1_Diagnose_aktiv (CM_NM_HUD_NM_aktiv_Diag_Cx1_Diagnose_aktiv)}, range raw 0..1, transfer-property=TRIGGERED  # Diagnose befindet sich nach VW80124 in einer NonDefaultDiagnostic-Session, z.B. ExtendedDiagnostic-Session
          signal NM_HUD_NM_aktiv_Tmin_XIX_NM_HUD_XIX_HCP3_CANFD01: start 162, 1 bit, little-endian, data-type-policy=OVERRIDE, i-signal-type=PRIMITIVE, init-value=0, base-type=BT_NM_HUD_NM_aktiv_Tmin, compu {1=Cx1_Mindestaktivzeit (CM_NM_HUD_NM_aktiv_Tmin_Cx1_Mindestaktivzeit), 0=Cx0_Inaktiv (CM_NM_HUD_NM_aktiv_Tmin_Cx0_Inaktiv)}, range raw 0..1, transfer-property=TRIGGERED  # Mindestaktivzeit ist noch nicht abgelaufen (bei jedem Weckereignis wird die Mindestaktivzeit neu gestartet)
      frame NM_Info_El_XIX_HCP3_CANFD01: id 0x1B000073, from HCP3_IONode, frame-length=24, can-addressing-mode=EXTENDED, can-frame-rx-behavior=CAN-FD, can-frame-tx-behavior=CAN-FD, rx-identifier-range={lower-can-id=452984832, upper-can-id=452985855}
        nm pdu NM_Info_El_XIX_HCP3_CANFD01: length=24, unused-bit-pattern=0
          signal NM_Info_El_CBV_AWB_XIX_NM_Info_El_XIX_HCP3_CANFD01: start 4, 1 bit, little-endian, data-type-policy=OVERRIDE, i-signal-type=PRIMITIVE, init-value=0, base-type=BT_NM_Info_El_CBV_AWB, compu {1=Cx1_Aktiver_WakeUp (CM_NM_Info_El_CBV_AWB_Cx1_Aktiver_WakeUp), 0=Cx0_Passiver_WakeUp (CM_NM_Info_El_CBV_AWB_Cx0_Passiver_WakeUp)}, range raw 0..1, transfer-property=TRIGGERED  # Das Signal ist zu setzen, wenn das SG aktiv den Bus geweckt hat 0 = Passiver_WakeUp = SG hat das Netzwerk nicht aktiv geweckt 1 = Akitiver_WakeUp = SG hat das Netzwerk aktiv geweckt
          signal NM_Info_El_CBV_CRI_XIX_NM_Info_El_XIX_HCP3_CANFD01: start 6, 1 bit, little-endian, data-type-policy=OVERRIDE, i-signal-type=PRIMITIVE, init-value=1, base-type=BT_NM_Info_El_CBV_CRI, compu {0=Cx0_NM_ohne_Clusteranforderungen (CM_NM_Info_El_CBV_CRI_Cx0_NM_ohne_Clusteranforderungen), 1=Cx1_NM_mit_Clusteranforderungen (CM_NM_Info_El_CBV_CRI_Cx1_NM_mit_Clusteranforderungen)}, range raw 0..1, transfer-property=TRIGGERED  # Das Signal ist dauerhaft gesetzt, wenn das NM-Layout Cluster- Anforderungen enthält
          signal NM_Info_El_FCAB_XIX_NM_Info_El_XIX_HCP3_CANFD01: start 8, 56 bit, opaque, data-type-policy=OVERRIDE, i-signal-type=ARRAY, init-value=7 x 0b00000000, base-type=BT_NM_Info_El_FCAB, compu {34359738368=Cx800000000_36_Preheater (CM_NM_Info_El_FCAB_Cx800000000_36_Preheater), 131072=Cx20000_18_VirtualSideMirrors (CM_NM_Info_El_FCAB_Cx20000_18_VirtualSideMirrors), 140737488355328=Cx800000000000_48_Diagnosis_ClimateTmeLINs (CM_NM_Info_El_FCAB_Cx800000000000_48_Diagnosis_ClimateTmeLINs), 36028797018963968=Cx80000000000000_56_ChargingStatus (CM_NM_Info_El_FCAB_Cx80000000000000_56_ChargingStatus), 549755813888=Cx8000000000_40_Diagnosis_Energy (CM_NM_Info_El_FCAB_Cx8000000000_40_Diagnosis_Energy), 134217728=Cx8000000_28_OnboardTester_DataCollector (CM_NM_Info_El_FCAB_Cx8000000_28_OnboardTester_DataCollector), 18014398509481984=Cx40000000000000_55_Dimming (CM_NM_Info_El_FCAB_Cx40000000000000_55_Dimming), 1024=Cx400_11_Chassis (CM_NM_Info_El_FCAB_Cx400_11_Chassis), 9007199254740992=Cx20000000000000_54_reserved (CM_NM_Info_El_FCAB_Cx20000000000000_54_reserved) (54_<reserved>), 2=Cx2_02_Basefunction_Powertrain (CM_NM_Info_El_FCAB_Cx2_02_Basefunction_Powertrain), 17592186044416=Cx100000000000_45_Diagnosis_Comfort (CM_NM_Info_El_FCAB_Cx100000000000_45_Diagnosis_Comfort), 262144=Cx40000_19_Doors_Hatches (CM_NM_Info_El_FCAB_Cx40000_19_Doors_Hatches), 16384=Cx4000_15_InstrumentclusterDisplay (CM_NM_Info_El_FCAB_Cx4000_15_InstrumentclusterDisplay), 70368744177664=Cx400000000000_47_Diagnosis_ComfortLINs (CM_NM_Info_El_FCAB_Cx400000000000_47_Diagnosis_ComfortLINs), 8=Cx8_04_Basefunction_DrivingAssistance (CM_NM_Info_El_FCAB_Cx8_04_Basefunction_DrivingAssistance), 2048=Cx800_12_GearSelector (CM_NM_Info_El_FCAB_Cx800_12_GearSelector), 65536=Cx10000_17_Audio (CM_NM_Info_El_FCAB_Cx10000_17_Audio), 68719476736=Cx1000000000_37_HighVoltage_WirelessChargingStation (CM_NM_Info_El_FCAB_Cx1000000000_37_HighVoltage_WirelessChargingStation), 128=Cx80_08_Basefunction_Connectivity (CM_NM_Info_El_FCAB_Cx80_08_Basefunction_Connectivity), 1=Cx1_01_CarWakeUp (CM_NM_Info_El_FCAB_Cx1_01_CarWakeUp), 536870912=Cx20000000_30_EnergyManagement (CM_NM_Info_El_FCAB_Cx20000000_30_EnergyManagement), 2199023255552=Cx20000000000_42_Diagnosis_FlexRay (CM_NM_Info_El_FCAB_Cx20000000000_42_Diagnosis_FlexRay), 524288=Cx80000_20_OptionalComfort (CM_NM_Info_El_FCAB_Cx80000_20_OptionalComfort), 67108864=Cx4000000_27_Timemaster_Timer (CM_NM_Info_El_FCAB_Cx4000000_27_Timemaster_Timer), 512=Cx200_10_Powertrain (CM_NM_Info_El_FCAB_Cx200_10_Powertrain), 35184372088832=Cx200000000000_46_Diagnosis_Light (CM_NM_Info_El_FCAB_Cx200000000000_46_Diagnosis_Light), 8796093022208=Cx80000000000_44_Diagnosis_Infotainment (CM_NM_Info_El_FCAB_Cx80000000000_44_Diagnosis_Infotainment), 0=Cx0_Init (CM_NM_Info_El_FCAB_Cx0_Init), 8388608=Cx800000_24_ThermoManagement (CM_NM_Info_El_FCAB_Cx800000_24_ThermoManagement), 268435456=Cx10000000_29_SteeringColumnLock (CM_NM_Info_El_FCAB_Cx10000000_29_SteeringColumnLock), 17179869184=Cx400000000_35_ExteriorSound (CM_NM_Info_El_FCAB_Cx400000000_35_ExteriorSound), 32=Cx20_06_Basefunction_ComfortLight (CM_NM_Info_El_FCAB_Cx20_06_Basefunction_ComfortLight), 4503599627370496=Cx10000000000000_53_Lock_Unlock (CM_NM_Info_El_FCAB_Cx10000000000000_53_Lock_Unlock), 8192=Cx2000_14_InfotainmentExtensions (CM_NM_Info_El_FCAB_Cx2000_14_InfotainmentExtensions), 2147483648=Cx80000000_32_OnlineAccess (CM_NM_Info_El_FCAB_Cx80000000_32_OnlineAccess), 64=Cx40_07_Basefunction_CrossSection (CM_NM_Info_El_FCAB_Cx40_07_Basefunction_CrossSection), 16=Cx10_05_Basefunction_Infotainment (CM_NM_Info_El_FCAB_Cx10_05_Basefunction_Infotainment), 1073741824=Cx40000000_31_MultifunctionalSteeringWheel (CM_NM_Info_El_FCAB_Cx40000000_31_MultifunctionalSteeringWheel), 16777216=Cx1000000_25_AccessSystemSensors (CM_NM_Info_El_FCAB_Cx1000000_25_AccessSystemSensors), 8589934592=Cx200000000_34_GPS_Localization (CM_NM_Info_El_FCAB_Cx200000000_34_GPS_Localization), 1048576=Cx100000_21_AirSuspension (CM_NM_Info_El_FCAB_Cx100000_21_AirSuspension), 1099511627776=Cx10000000000_41_Diagnosis_Powertrain (CM_NM_Info_El_FCAB_Cx10000000000_41_Diagnosis_Powertrain), 4194304=Cx400000_23_Climate (CM_NM_Info_El_FCAB_Cx400000_23_Climate), 4294967296=Cx100000000_33_ExternalWirelessCommunication (CM_NM_Info_El_FCAB_Cx100000000_33_ExternalWirelessCommunication), 32768=Cx8000_16_InfotainmentDisplay (CM_NM_Info_El_FCAB_Cx8000_16_InfotainmentDisplay), 4=Cx4_03_Basefunction_Chassis (CM_NM_Info_El_FCAB_Cx4_03_Basefunction_Chassis), 2097152=Cx200000_22_ExteriorLights (CM_NM_Info_El_FCAB_Cx200000_22_ExteriorLights), 256=Cx100_09_reserved (CM_NM_Info_El_FCAB_Cx100_09_reserved) (09_<reserved>), 33554432=Cx2000000_26_HighVoltage_Charging (CM_NM_Info_El_FCAB_Cx2000000_26_HighVoltage_Charging), 4096=Cx1000_13_Airbag (CM_NM_Info_El_FCAB_Cx1000_13_Airbag), 4398046511104=Cx40000000000_43_Diagnosis_DrivingAssistance (CM_NM_Info_El_FCAB_Cx40000000000_43_Diagnosis_DrivingAssistance), 281474976710656=Cx1000000000000_49_reserved (CM_NM_Info_El_FCAB_Cx1000000000000_49_reserved) (49_<reserved>)}, range raw 0..36028797018963968, transfer-property=TRIGGERED-ON-CHANGE  # FCAB = Funktions-Cluster-Aktiv-Bits
          signal NM_Info_El_SNI_10_XIX_NM_Info_El_XIX_HCP3_CANFD01: start 128, 10 bit, little-endian, data-type-policy=OVERRIDE, i-signal-type=PRIMITIVE, init-value=115, base-type=BT_NM_Info_El_SNI_10, compu {115=Cx73_Info_El_SNI (CM_NM_Info_El_SNI_10_Cx73_Info_El_SNI)}, range raw 115, transfer-property=TRIGGERED  # Source Node-Identifier (SNI) identifiziert den Sender der NM-Botschaft (Knotenadresse) eindeutig im Fahrzeug
          signal NM_Info_El_NM_State_XIX_NM_Info_El_XIX_HCP3_CANFD01: start 144, 6 bit, little-endian, data-type-policy=OVERRIDE, i-signal-type=PRIMITIVE, init-value=0, base-type=BT_NM_Info_El_NM_State, compu {8=Cx8_NM_NO_aus_RS (CM_NM_Info_El_NM_State_Cx8_NM_NO_aus_RS), 2=Cx2_NM_RM_aus_PBSM (CM_NM_Info_El_NM_State_Cx2_NM_RM_aus_PBSM), 0=Cx0_Init (CM_NM_Info_El_NM_State_Cx0_Init), 4=Cx4_NM_NO_aus_RM (CM_NM_Info_El_NM_State_Cx4_NM_NO_aus_RM), 32=Cx20_reserved (CM_NM_Info_El_NM_State_Cx20_reserved), 1=Cx1_NM_RM_aus_BSM (CM_NM_Info_El_NM_State_Cx1_NM_RM_aus_BSM), 16=Cx10_reserved (CM_NM_Info_El_NM_State_Cx10_reserved)}, range raw 0..32, transfer-property=TRIGGERED  # 1 = Zustand Repeat Message (<-- Bus-Sleep Mode) 2 = Zustand Repeat Message (<-- Prepare Bus-Sleep Mode) 4 = Zustand Normal Operation (<-- Repeat Message) 8 = Zustand Normal Operation (<-- Ready Sleep)
          signal NM_Info_El_UDS_CC_XIX_NM_Info_El_XIX_HCP3_CANFD01: start 151, 1 bit, little-endian, data-type-policy=OVERRIDE, i-signal-type=PRIMITIVE, init-value=0, base-type=BT_NM_Info_El_UDS_CC, compu {0=Cx0_Inaktiv (CM_NM_Info_El_UDS_CC_Cx0_Inaktiv), 1=Cx1_CC_aktiv (CM_NM_Info_El_UDS_CC_Cx1_CC_aktiv)}, range raw 0..1, transfer-property=TRIGGERED  # Funktionseinschränkung aufgrund aktivem UDS-Communication Control, siehe VW80124
          signal NM_Info_El_Wakeup_V12_XIX_NM_Info_El_XIX_HCP3_CANFD01: start 152, 8 bit, little-endian, data-type-policy=OVERRIDE, i-signal-type=PRIMITIVE, init-value=0, base-type=BT_NM_Info_El_Wakeup_V12, compu {132=Cx84_IVIPartition_3 (CM_NM_Info_El_Wakeup_V12_Cx84_IVIPartition_3), 131=Cx83_IVIPartition_2 (CM_NM_Info_El_Wakeup_V12_Cx83_IVIPartition_2), 129=Cx81_ScreenUpdate (CM_NM_Info_El_Wakeup_V12_Cx81_ScreenUpdate), 135=Cx87_Systempartition_3 (CM_NM_Info_El_Wakeup_V12_Cx87_Systempartition_3), 2=Cx2_KL15_HW (CM_NM_Info_El_Wakeup_V12_Cx2_KL15_HW), 130=Cx82_IVIPartition_1 (CM_NM_Info_El_Wakeup_V12_Cx82_IVIPartition_1), 136=Cx88_User_Anmeldung (CM_NM_Info_El_Wakeup_V12_Cx88_User_Anmeldung), 0=Cx0_Peripherie_Wakeup_Ursache_nicht_bekannt (CM_NM_Info_El_Wakeup_V12_Cx0_Peripherie_Wakeup_Ursache_nicht_bekannt), 137=Cx89_BAP_Kommunikation_Klima (CM_NM_Info_El_Wakeup_V12_Cx89_BAP_Kommunikation_Klima), 1=Cx1_Bus_Wakeup (CM_NM_Info_El_Wakeup_V12_Cx1_Bus_Wakeup), 167=Cxa7_SOK_Master_Anforderung (CM_NM_Info_El_Wakeup_V12_Cxa7_SOK_Master_Anforderung), 4=Cx4_Buswakeup_WU_HCP3_CANFD (CM_NM_Info_El_Wakeup_V12_Cx4_Buswakeup_WU_HCP3_CANFD), 134=Cx86_Systempartition_2 (CM_NM_Info_El_Wakeup_V12_Cx86_Systempartition_2), 5=Cx5_Buswakeup_HCP3_CANFD01 (CM_NM_Info_El_Wakeup_V12_Cx5_Buswakeup_HCP3_CANFD01), 6=Cx6_Buswakeup_HCP3_CANFD02 (CM_NM_Info_El_Wakeup_V12_Cx6_Buswakeup_HCP3_CANFD02), 133=Cx85_Systempartition_1 (CM_NM_Info_El_Wakeup_V12_Cx85_Systempartition_1), 128=Cx80_VNSM_Anforderung (CM_NM_Info_El_Wakeup_V12_Cx80_VNSM_Anforderung)}, range raw 0..167, transfer-property=TRIGGERED  # enthält die Weckursache; stehen mehrere Weckursachen parallel an, dann muss der kleinste Wert übertragen werden
          signal NM_Info_El_NM_aktiv_KL15_XIX_NM_Info_El_XIX_HCP3_CANFD01: start 160, 1 bit, little-endian, data-type-policy=OVERRIDE, i-signal-type=PRIMITIVE, init-value=0, base-type=BT_NM_Info_El_NM_aktiv_KL15, compu {1=Cx1_KL15_EIN (CM_NM_Info_El_NM_aktiv_KL15_Cx1_KL15_EIN), 0=Cx0_Inaktiv (CM_NM_Info_El_NM_aktiv_KL15_Cx0_Inaktiv)}, range raw 0..1, transfer-property=TRIGGERED  # Steuergerät hat KL15-EIN erkannt
          signal NM_Info_El_NM_aktiv_Diag_XIX_NM_Info_El_XIX_HCP3_CANFD01: start 161, 1 bit, little-endian, data-type-policy=OVERRIDE, i-signal-type=PRIMITIVE, init-value=0, base-type=BT_NM_Info_El_NM_aktiv_Diag, compu {1=Cx1_Diagnose_aktiv (CM_NM_Info_El_NM_aktiv_Diag_Cx1_Diagnose_aktiv), 0=Cx0_Inaktiv (CM_NM_Info_El_NM_aktiv_Diag_Cx0_Inaktiv)}, range raw 0..1, transfer-property=TRIGGERED  # Diagnose befindet sich nach VW80124 in einer NonDefaultDiagnostic-Session, z.B. ExtendedDiagnostic-Session
          signal NM_Info_El_NM_aktiv_Tmin_XIX_NM_Info_El_XIX_HCP3_CANFD01: start 162, 1 bit, little-endian, data-type-policy=OVERRIDE, i-signal-type=PRIMITIVE, init-value=0, base-type=BT_NM_Info_El_NM_aktiv_Tmin, compu {1=Cx1_Mindestaktivzeit (CM_NM_Info_El_NM_aktiv_Tmin_Cx1_Mindestaktivzeit), 0=Cx0_Inaktiv (CM_NM_Info_El_NM_aktiv_Tmin_Cx0_Inaktiv)}, range raw 0..1, transfer-property=TRIGGERED  # Mindestaktivzeit ist noch nicht abgelaufen (bei jedem Weckereignis wird die Mindestaktivzeit neu gestartet)
          signal NM_Info_El_NM_aktiv_CABaktiv_XIX_NM_Info_El_XIX_HCP3_CANFD01: start 163, 1 bit, little-endian, data-type-policy=OVERRIDE, i-signal-type=PRIMITIVE, init-value=0, base-type=BT_NM_Info_El_NM_aktiv_CABaktiv, compu {1=Cx1_Cluster_Min_Req_TimeOfVNSM (CM_NM_Info_El_NM_aktiv_CABaktiv_Cx1_Cluster_Min_Req_TimeOfVNSM), 0=Cx0_Inaktiv (CM_NM_Info_El_NM_aktiv_CABaktiv_Cx0_Inaktiv)}, range raw 0..1, transfer-property=TRIGGERED  # Nachlauf aufgrund Funktionscluster Anforderung
          signal NM_aktiv_GoodbyeScreen_XIX_NM_Info_El_XIX_HCP3_CANFD01: start 164, 1 bit, little-endian, data-type-policy=OVERRIDE, i-signal-type=PRIMITIVE, init-value=0, base-type=BT_NM_aktiv_GoodbyeScreen, compu {1=Cx1_Aktiv (CM_NM_aktiv_GoodbyeScreen_Cx1_Aktiv), 0=Cx0_Inaktiv (CM_NM_aktiv_GoodbyeScreen_Cx0_Inaktiv)}, range raw 0..1, transfer-property=TRIGGERED  # Der Goodbye-Screen wird im Infotainment beim wechsel von KL15=ON zu KL15=OFF aufgeschalten und beinhaltet unterschiedliche Informationen die beim Aussteigen von Relevanz sind.
          signal NM_aktiv_SysPartition_1_XIX_NM_Info_El_XIX_HCP3_CANFD01: start 165, 1 bit, little-endian, data-type-policy=OVERRIDE, i-signal-type=PRIMITIVE, init-value=0, base-type=BT_NM_aktiv_SysPartition_1, compu {1=Cx1_Aktiv (CM_NM_aktiv_SysPartition_1_Cx1_Aktiv), 0=Cx0_Inaktiv (CM_NM_aktiv_SysPartition_1_Cx0_Inaktiv)}, range raw 0..1, transfer-property=TRIGGERED  # Vorhalt VNSM_UsrId und NM-Aktivgrund-Signal für künftig möglichen Funktionshub ohne erforderlichen K-Matrix Update
          signal NM_aktiv_SysPartition_2_XIX_NM_Info_El_XIX_HCP3_CANFD01: start 166, 1 bit, little-endian, data-type-policy=OVERRIDE, i-signal-type=PRIMITIVE, init-value=0, base-type=BT_NM_aktiv_SysPartition_2, compu {0=Cx0_Inaktiv (CM_NM_aktiv_SysPartition_2_Cx0_Inaktiv), 1=Cx1_Aktiv (CM_NM_aktiv_SysPartition_2_Cx1_Aktiv)}, range raw 0..1, transfer-property=PENDING  # Vorhalt VNSM_UsrId und NM-Aktivgrund-Signal für künftig möglichen Funktionshub ohne erforderlichen K-Matrix Update
          signal NM_aktiv_SysPartition_3_XIX_NM_Info_El_XIX_HCP3_CANFD01: start 167, 1 bit, little-endian, data-type-policy=OVERRIDE, i-signal-type=PRIMITIVE, init-value=0, base-type=BT_NM_aktiv_SysPartition_3, compu {0=Cx0_Inaktiv (CM_NM_aktiv_SysPartition_3_Cx0_Inaktiv), 1=Cx1_Aktiv (CM_NM_aktiv_SysPartition_3_Cx1_Aktiv)}, range raw 0..1, transfer-property=TRIGGERED  # Vorhalt VNSM_UsrId und NM-Aktivgrund-Signal für künftig möglichen Funktionshub ohne erforderlichen K-Matrix Update
          signal NM_aktiv_IVIPartition_1_XIX_NM_Info_El_XIX_HCP3_CANFD01: start 168, 1 bit, little-endian, data-type-policy=OVERRIDE, i-signal-type=PRIMITIVE, init-value=0, base-type=BT_NM_aktiv_IVIPartition_1, compu {0=Cx0_Inaktiv (CM_NM_aktiv_IVIPartition_1_Cx0_Inaktiv), 1=Cx1_Aktiv (CM_NM_aktiv_IVIPartition_1_Cx1_Aktiv)}, range raw 0..1, transfer-property=TRIGGERED  # Vorhalt VNSM_UsrId und NM-Aktivgrund-Signal für künftig möglichen Funktionshub ohne erforderlichen K-Matrix Update
          signal NM_aktiv_IVIPartition_2_XIX_NM_Info_El_XIX_HCP3_CANFD01: start 169, 1 bit, little-endian, data-type-policy=OVERRIDE, i-signal-type=PRIMITIVE, init-value=0, base-type=BT_NM_aktiv_IVIPartition_2, compu {0=Cx0_Inaktiv (CM_NM_aktiv_IVIPartition_2_Cx0_Inaktiv), 1=Cx1_Aktiv (CM_NM_aktiv_IVIPartition_2_Cx1_Aktiv)}, range raw 0..1, transfer-property=TRIGGERED  # Vorhalt VNSM_UsrId und NM-Aktivgrund-Signal für künftig möglichen Funktionshub ohne erforderlichen K-Matrix Update
          signal NM_aktiv_IVIPartition_3_XIX_NM_Info_El_XIX_HCP3_CANFD01: start 170, 1 bit, little-endian, data-type-policy=OVERRIDE, i-signal-type=PRIMITIVE, base-type=BT_NM_aktiv_IVIPartition_3, compu {0=Cx0_Inaktiv (CM_NM_aktiv_IVIPartition_3_Cx0_Inaktiv), 1=Cx1_Aktiv (CM_NM_aktiv_IVIPartition_3_Cx1_Aktiv)}, range raw 0..1, transfer-property=PENDING  # Vorhalt VNSM_UsrId und NM-Aktivgrund-Signal für künftig möglichen Funktionshub ohne erforderlichen K-Matrix Update
          signal NM_aktiv_Internetverbindung_XIX_NM_Info_El_XIX_HCP3_CANFD01: start 171, 1 bit, little-endian, data-type-policy=OVERRIDE, i-signal-type=PRIMITIVE, init-value=0, base-type=BT_NM_aktiv_Internetverbindung, compu {0=Cx0_Inaktiv (CM_NM_aktiv_Internetverbindung_Cx0_Inaktiv), 1=Cx1_Aktiv (CM_NM_aktiv_Internetverbindung_Cx1_Aktiv)}, range raw 0..1, transfer-property=TRIGGERED  # Nach Klemme 15 aus wird eine Anbindung an die ConMod benötigt, um Internet-Funktionalitäten sicherzustellen.
          signal NM_aktiv_Tankinhalt_ermitteln_XIX_NM_Info_El_XIX_HCP3_CANFD01: start 172, 1 bit, little-endian, data-type-policy=OVERRIDE, i-signal-type=PRIMITIVE, init-value=0, base-type=BT_NM_aktiv_Tankinhalt_ermitteln, compu {1=Cx1_Aktiv (CM_NM_aktiv_Tankinhalt_ermitteln_Cx1_Aktiv), 0=Cx0_Inaktiv (CM_NM_aktiv_Tankinhalt_ermitteln_Cx0_Inaktiv)}, range raw 0..1, transfer-property=TRIGGERED  # Der Tankalgorithmus bildet für die Nachtankerkennung beginnend mit Fahrzeugstillstand einen Referenzwert aus mindestens 8 gültigen Tankfüllstands- Messwerten. Fällt der Vorgang unmittelbar in eine KL15 Aus -phase, so muss der Bus wachgehalten werden bis die Referenzwertbildung abgeschlossen ist.
          signal NM_aktiv_SOK_Master_Anf_Info_El_XIX_NM_Info_El_XIX_HCP3_CANFD01: start 173, 1 bit, little-endian, data-type-policy=OVERRIDE, i-signal-type=PRIMITIVE, init-value=0, base-type=BT_NM_aktiv_SOK_Master_Anf_Info_El, compu {0=Cx0_Inaktiv (CM_NM_aktiv_SOK_Master_Anf_Info_El_Cx0_Inaktiv), 1=Cx1_Aktiv (CM_NM_aktiv_SOK_Master_Anf_Info_El_Cx1_Aktiv)}, range raw 0..1, transfer-property=TRIGGERED  # Für die korrekte Funktionsweise von SOK wird der sog. SOK Zeimtaster auf dem HCP5 µC benötigt.
          signal NM_aktiv_User_Anmeldung_XIX_NM_Info_El_XIX_HCP3_CANFD01: start 174, 1 bit, little-endian, data-type-policy=OVERRIDE, i-signal-type=PRIMITIVE, init-value=0, base-type=BT_NM_aktiv_User_Anmeldung, compu {0=Cx0_Inaktiv (CM_NM_aktiv_User_Anmeldung_Cx0_Inaktiv), 1=Cx1_Aktiv (CM_NM_aktiv_User_Anmeldung_Cx1_Aktiv)}, range raw 0..1, transfer-property=TRIGGERED  # Zur Nutzung des Nutzerlogins bzw. der Nutzerumschaltung auch bei KL15 Aus ist es notwendig, dass die beteiligten Steuergeräte wie HCP4, HCP5 und als Wecker HCP3 aufgeweckt und wachgehalten werden.
          signal NM_aktiv_Innenraumerlebnis_XIX_NM_Info_El_XIX_HCP3_CANFD01: start 175, 1 bit, little-endian, data-type-policy=OVERRIDE, i-signal-type=PRIMITIVE, init-value=0, base-type=BT_NM_aktiv_Innenraumerlebnis, compu {1=Cx1_Aktiv (CM_NM_aktiv_Innenraumerlebnis_Cx1_Aktiv), 0=Cx0_Inaktiv (CM_NM_aktiv_Innenraumerlebnis_Cx0_Inaktiv)}, range raw 0..1, transfer-property=TRIGGERED  # Erlebnis Innenraum (Inszenierungsmaster-App im HCP3) schaltet verschiedene Komfortfunktionen möglichst harmonisch zusammen um dem Kunden den Fahrzeuginnenraum zu inszenieren. Dabei überstimmt die Funktion für die Dauer der Inszenierung die Kundeneinstellungen, z.B. im Ambientelicht und am Ende der Inszenierung stellt die Funktion wieder die letzte Kundeneinstellung ein.
          signal NM_aktiv_BAP_Kommunikation_SYS_XIX_NM_Info_El_XIX_HCP3_CANFD01: start 176, 1 bit, little-endian, data-type-policy=OVERRIDE, i-signal-type=PRIMITIVE, init-value=0, base-type=BT_NM_aktiv_BAP_Kommunikation_SYS, compu {1=Cx1_Aktiv (CM_NM_aktiv_BAP_Kommunikation_SYS_Cx1_Aktiv), 0=Cx0_Inaktiv (CM_NM_aktiv_BAP_Kommunikation_SYS_Cx0_Inaktiv)}, range raw 0..1, transfer-property=PENDING  # Die Native BAP Business Logik ist eine SW Komponente die im HCP3 für die BAP Kommunikation zuständig ist. Da es funktionen gibt gibt die eine BAP Kommunikation bei KL15=OFF benötigen (Klima, TME) muss diese SW Komponente die Möglichkeit haben CABs anzufragen/wecken/wachzuhalten um die BAP Kommuniation für die betroffenen Funktionen auch bei KL15=OFF zu ermöglichen.
      frame NM_LSR_1_XIX_HCP3_CANFD01: id 0x1B0000F6, to HCP3_IONode, frame-length=24, can-addressing-mode=EXTENDED, can-frame-rx-behavior=CAN-FD, can-frame-tx-behavior=CAN-FD, rx-identifier-range={lower-can-id=452984832, upper-can-id=452985855}
        nm pdu NM_LSR_1_XIX_HCP3_CANFD01: length=24, unused-bit-pattern=0
          signal NM_LSR_1_CBV_AWB_XIX_NM_LSR_1_XIX_HCP3_CANFD01: start 4, 1 bit, little-endian, data-type-policy=OVERRIDE, i-signal-type=PRIMITIVE, init-value=0, base-type=BT_NM_LSR_1_CBV_AWB, compu {1=Cx1_Aktiver_WakeUp (CM_NM_LSR_1_CBV_AWB_Cx1_Aktiver_WakeUp), 0=Cx0_Passiver_WakeUp (CM_NM_LSR_1_CBV_AWB_Cx0_Passiver_WakeUp)}, range raw 0..1, transfer-property=TRIGGERED  # Das Signal ist zu setzen, wenn das SG aktiv den Bus geweckt hat 0 = Passiver_WakeUp = SG hat das Netzwerk nicht aktiv geweckt 1 = Akitiver_WakeUp = SG hat das Netzwerk aktiv geweckt
          signal NM_LSR_1_CBV_CRI_XIX_NM_LSR_1_XIX_HCP3_CANFD01: start 6, 1 bit, little-endian, data-type-policy=OVERRIDE, i-signal-type=PRIMITIVE, init-value=1, base-type=BT_NM_LSR_1_CBV_CRI, compu {1=Cx1_NM_mit_Clusteranforderungen (CM_NM_LSR_1_CBV_CRI_Cx1_NM_mit_Clusteranforderungen), 0=Cx0_NM_ohne_Clusteranforderungen (CM_NM_LSR_1_CBV_CRI_Cx0_NM_ohne_Clusteranforderungen)}, range raw 0..1, transfer-property=TRIGGERED  # Das Signal ist dauerhaft gesetzt, wenn das NM-Layout Cluster- Anforderungen enthält
          signal NM_LSR_1_FCAB_XIX_NM_LSR_1_XIX_HCP3_CANFD01: start 8, 56 bit, opaque, data-type-policy=OVERRIDE, i-signal-type=ARRAY, init-value=7 x 0b00000000, base-type=BT_NM_LSR_1_FCAB, compu {4398046511104=Cx40000000000_43_Diagnosis_DrivingAssistance (CM_NM_LSR_1_FCAB_Cx40000000000_43_Diagnosis_DrivingAssistance), 68719476736=Cx1000000000_37_HighVoltage_WirelessChargingStation (CM_NM_LSR_1_FCAB_Cx1000000000_37_HighVoltage_WirelessChargingStation), 140737488355328=Cx800000000000_48_Diagnosis_ClimateTmeLINs (CM_NM_LSR_1_FCAB_Cx800000000000_48_Diagnosis_ClimateTmeLINs), 1099511627776=Cx10000000000_41_Diagnosis_Powertrain (CM_NM_LSR_1_FCAB_Cx10000000000_41_Diagnosis_Powertrain), 4194304=Cx400000_23_Climate (CM_NM_LSR_1_FCAB_Cx400000_23_Climate), 17592186044416=Cx100000000000_45_Diagnosis_Comfort (CM_NM_LSR_1_FCAB_Cx100000000000_45_Diagnosis_Comfort), 64=Cx40_07_Basefunction_CrossSection (CM_NM_LSR_1_FCAB_Cx40_07_Basefunction_CrossSection), 4294967296=Cx100000000_33_ExternalWirelessCommunication (CM_NM_LSR_1_FCAB_Cx100000000_33_ExternalWirelessCommunication), 512=Cx200_10_Powertrain (CM_NM_LSR_1_FCAB_Cx200_10_Powertrain), 134217728=Cx8000000_28_OnboardTester_DataCollector (CM_NM_LSR_1_FCAB_Cx8000000_28_OnboardTester_DataCollector), 17179869184=Cx400000000_35_ExteriorSound (CM_NM_LSR_1_FCAB_Cx400000000_35_ExteriorSound), 65536=Cx10000_17_Audio (CM_NM_LSR_1_FCAB_Cx10000_17_Audio), 34359738368=Cx800000000_36_Preheater (CM_NM_LSR_1_FCAB_Cx800000000_36_Preheater), 8589934592=Cx200000000_34_GPS_Localization (CM_NM_LSR_1_FCAB_Cx200000000_34_GPS_Localization), 1024=Cx400_11_Chassis (CM_NM_LSR_1_FCAB_Cx400_11_Chassis), 16=Cx10_05_Basefunction_Infotainment (CM_NM_LSR_1_FCAB_Cx10_05_Basefunction_Infotainment), 36028797018963968=Cx80000000000000_56_ChargingStatus (CM_NM_LSR_1_FCAB_Cx80000000000000_56_ChargingStatus), 35184372088832=Cx200000000000_46_Diagnosis_Light (CM_NM_LSR_1_FCAB_Cx200000000000_46_Diagnosis_Light), 0=Cx0_Init (CM_NM_LSR_1_FCAB_Cx0_Init), 4096=Cx1000_13_Airbag (CM_NM_LSR_1_FCAB_Cx1000_13_Airbag), 8=Cx8_04_Basefunction_DrivingAssistance (CM_NM_LSR_1_FCAB_Cx8_04_Basefunction_DrivingAssistance), 549755813888=Cx8000000000_40_Diagnosis_Energy (CM_NM_LSR_1_FCAB_Cx8000000000_40_Diagnosis_Energy), 16384=Cx4000_15_InstrumentclusterDisplay (CM_NM_LSR_1_FCAB_Cx4000_15_InstrumentclusterDisplay), 8796093022208=Cx80000000000_44_Diagnosis_Infotainment (CM_NM_LSR_1_FCAB_Cx80000000000_44_Diagnosis_Infotainment), 16777216=Cx1000000_25_AccessSystemSensors (CM_NM_LSR_1_FCAB_Cx1000000_25_AccessSystemSensors), 2147483648=Cx80000000_32_OnlineAccess (CM_NM_LSR_1_FCAB_Cx80000000_32_OnlineAccess), 131072=Cx20000_18_VirtualSideMirrors (CM_NM_LSR_1_FCAB_Cx20000_18_VirtualSideMirrors), 268435456=Cx10000000_29_SteeringColumnLock (CM_NM_LSR_1_FCAB_Cx10000000_29_SteeringColumnLock), 2=Cx2_02_Basefunction_Powertrain (CM_NM_LSR_1_FCAB_Cx2_02_Basefunction_Powertrain), 2048=Cx800_12_GearSelector (CM_NM_LSR_1_FCAB_Cx800_12_GearSelector), 2097152=Cx200000_22_ExteriorLights (CM_NM_LSR_1_FCAB_Cx200000_22_ExteriorLights), 128=Cx80_08_Basefunction_Connectivity (CM_NM_LSR_1_FCAB_Cx80_08_Basefunction_Connectivity), 1=Cx1_01_CarWakeUp (CM_NM_LSR_1_FCAB_Cx1_01_CarWakeUp), 524288=Cx80000_20_OptionalComfort (CM_NM_LSR_1_FCAB_Cx80000_20_OptionalComfort), 9007199254740992=Cx20000000000000_54_reserved (CM_NM_LSR_1_FCAB_Cx20000000000000_54_reserved) (54_<reserved>), 8192=Cx2000_14_InfotainmentExtensions (CM_NM_LSR_1_FCAB_Cx2000_14_InfotainmentExtensions), 536870912=Cx20000000_30_EnergyManagement (CM_NM_LSR_1_FCAB_Cx20000000_30_EnergyManagement), 32=Cx20_06_Basefunction_ComfortLight (CM_NM_LSR_1_FCAB_Cx20_06_Basefunction_ComfortLight), 1048576=Cx100000_21_AirSuspension (CM_NM_LSR_1_FCAB_Cx100000_21_AirSuspension), 70368744177664=Cx400000000000_47_Diagnosis_ComfortLINs (CM_NM_LSR_1_FCAB_Cx400000000000_47_Diagnosis_ComfortLINs), 262144=Cx40000_19_Doors_Hatches (CM_NM_LSR_1_FCAB_Cx40000_19_Doors_Hatches), 32768=Cx8000_16_InfotainmentDisplay (CM_NM_LSR_1_FCAB_Cx8000_16_InfotainmentDisplay), 8388608=Cx800000_24_ThermoManagement (CM_NM_LSR_1_FCAB_Cx800000_24_ThermoManagement), 2199023255552=Cx20000000000_42_Diagnosis_FlexRay (CM_NM_LSR_1_FCAB_Cx20000000000_42_Diagnosis_FlexRay), 256=Cx100_09_reserved (CM_NM_LSR_1_FCAB_Cx100_09_reserved) (09_<reserved>), 18014398509481984=Cx40000000000000_55_Dimming (CM_NM_LSR_1_FCAB_Cx40000000000000_55_Dimming), 1073741824=Cx40000000_31_MultifunctionalSteeringWheel (CM_NM_LSR_1_FCAB_Cx40000000_31_MultifunctionalSteeringWheel), 67108864=Cx4000000_27_Timemaster_Timer (CM_NM_LSR_1_FCAB_Cx4000000_27_Timemaster_Timer), 4=Cx4_03_Basefunction_Chassis (CM_NM_LSR_1_FCAB_Cx4_03_Basefunction_Chassis), 33554432=Cx2000000_26_HighVoltage_Charging (CM_NM_LSR_1_FCAB_Cx2000000_26_HighVoltage_Charging), 4503599627370496=Cx10000000000000_53_Lock_Unlock (CM_NM_LSR_1_FCAB_Cx10000000000000_53_Lock_Unlock), 281474976710656=Cx1000000000000_49_reserved (CM_NM_LSR_1_FCAB_Cx1000000000000_49_reserved) (49_<reserved>)}, range raw 0..36028797018963968, transfer-property=TRIGGERED-ON-CHANGE  # FCAB = Funktions-Cluster-Aktiv-Bits
          signal NM_LSR_1_SNI_10_XIX_NM_LSR_1_XIX_HCP3_CANFD01: start 128, 10 bit, little-endian, data-type-policy=OVERRIDE, i-signal-type=PRIMITIVE, init-value=147, base-type=BT_NM_LSR_1_SNI_10, compu {147=Cx93_LSR_1_SNI (CM_NM_LSR_1_SNI_10_Cx93_LSR_1_SNI)}, range raw 147, transfer-property=TRIGGERED  # Source Node-Identifier (SNI) identifiziert den Sender der NM-Botschaft (Knotenadresse) eindeutig im Fahrzeug
          signal NM_LSR_1_NM_State_XIX_NM_LSR_1_XIX_HCP3_CANFD01: start 144, 6 bit, little-endian, data-type-policy=OVERRIDE, i-signal-type=PRIMITIVE, init-value=0, base-type=BT_NM_LSR_1_NM_State, compu {0=Cx0_Init (CM_NM_LSR_1_NM_State_Cx0_Init), 4=Cx4_NM_NO_aus_RM (CM_NM_LSR_1_NM_State_Cx4_NM_NO_aus_RM), 1=Cx1_NM_RM_aus_BSM (CM_NM_LSR_1_NM_State_Cx1_NM_RM_aus_BSM), 8=Cx8_NM_NO_aus_RS (CM_NM_LSR_1_NM_State_Cx8_NM_NO_aus_RS), 2=Cx2_NM_RM_aus_PBSM (CM_NM_LSR_1_NM_State_Cx2_NM_RM_aus_PBSM), 16=Cx10_reserved (CM_NM_LSR_1_NM_State_Cx10_reserved), 32=Cx20_reserved (CM_NM_LSR_1_NM_State_Cx20_reserved)}, range raw 0..32, transfer-property=TRIGGERED  # 1 = Zustand Repeat Message (<-- Bus-Sleep Mode) 2 = Zustand Repeat Message (<-- Prepare Bus-Sleep Mode) 4 = Zustand Normal Operation (<-- Repeat Message) 8 = Zustand Normal Operation (<-- Ready Sleep)
          signal NM_LSR_1_UDS_CC_XIX_NM_LSR_1_XIX_HCP3_CANFD01: start 151, 1 bit, little-endian, data-type-policy=OVERRIDE, i-signal-type=PRIMITIVE, init-value=0, base-type=BT_NM_LSR_1_UDS_CC, compu {1=Cx1_CC_aktiv (CM_NM_LSR_1_UDS_CC_Cx1_CC_aktiv), 0=Cx0_Inaktiv (CM_NM_LSR_1_UDS_CC_Cx0_Inaktiv)}, range raw 0..1, transfer-property=TRIGGERED  # Funktionseinschränkung aufgrund aktivem UDS-Communication Control, siehe VW80124
          signal NM_LSR_1_Wakeup_V12_XIX_NM_LSR_1_XIX_HCP3_CANFD01: start 152, 8 bit, little-endian, data-type-policy=OVERRIDE, i-signal-type=PRIMITIVE, init-value=0, base-type=BT_NM_LSR_1_Wakeup_V12, compu {4=Cx4_OnOff_Tasterbetaetigung (CM_NM_LSR_1_Wakeup_V12_Cx4_OnOff_Tasterbetaetigung), 2=Cx2_KL15_HW (CM_NM_LSR_1_Wakeup_V12_Cx2_KL15_HW), 0=Cx0_Peripherie_Wakeup_Ursache_nicht_bekannt (CM_NM_LSR_1_Wakeup_V12_Cx0_Peripherie_Wakeup_Ursache_nicht_bekannt), 1=Cx1_Bus_Wakeup (CM_NM_LSR_1_Wakeup_V12_Cx1_Bus_Wakeup)}, range raw 0..4, transfer-property=TRIGGERED  # enthält die Weckursache; stehen mehrere Weckursachen parallel an, dann muss der kleinste Wert übertragen werden
          signal NM_LSR_1_NM_aktiv_KL15_XIX_NM_LSR_1_XIX_HCP3_CANFD01: start 160, 1 bit, little-endian, data-type-policy=OVERRIDE, i-signal-type=PRIMITIVE, init-value=0, base-type=BT_NM_LSR_1_NM_aktiv_KL15, compu {1=Cx1_KL15_EIN (CM_NM_LSR_1_NM_aktiv_KL15_Cx1_KL15_EIN), 0=Cx0_Inaktiv (CM_NM_LSR_1_NM_aktiv_KL15_Cx0_Inaktiv)}, range raw 0..1, transfer-property=TRIGGERED  # Steuergerät hat KL15-EIN erkannt
          signal NM_LSR_1_NM_aktiv_Diag_XIX_NM_LSR_1_XIX_HCP3_CANFD01: start 161, 1 bit, little-endian, data-type-policy=OVERRIDE, i-signal-type=PRIMITIVE, init-value=0, base-type=BT_NM_LSR_1_NM_aktiv_Diag, compu {1=Cx1_Diagnose_aktiv (CM_NM_LSR_1_NM_aktiv_Diag_Cx1_Diagnose_aktiv), 0=Cx0_Inaktiv (CM_NM_LSR_1_NM_aktiv_Diag_Cx0_Inaktiv)}, range raw 0..1, transfer-property=TRIGGERED  # Diagnose befindet sich nach VW80124 in einer NonDefaultDiagnostic-Session, z.B. ExtendedDiagnostic-Session
          signal NM_LSR_1_NM_aktiv_Tmin_XIX_NM_LSR_1_XIX_HCP3_CANFD01: start 162, 1 bit, little-endian, data-type-policy=OVERRIDE, i-signal-type=PRIMITIVE, init-value=0, base-type=BT_NM_LSR_1_NM_aktiv_Tmin, compu {1=Cx1_Mindestaktivzeit (CM_NM_LSR_1_NM_aktiv_Tmin_Cx1_Mindestaktivzeit), 0=Cx0_Inaktiv (CM_NM_LSR_1_NM_aktiv_Tmin_Cx0_Inaktiv)}, range raw 0..1, transfer-property=TRIGGERED  # Mindestaktivzeit ist noch nicht abgelaufen (bei jedem Weckereignis wird die Mindestaktivzeit neu gestartet)
          signal NM_aktiv_OnOff_Lautstaerkeregler_XIX_NM_LSR_1_XIX_HCP3_CANFD01: start 163, 1 bit, little-endian, data-type-policy=OVERRIDE, i-signal-type=PRIMITIVE, init-value=0, base-type=BT_NM_aktiv_OnOff_Lautstaerkeregler, compu {1=Cx1_Aktiv (CM_NM_aktiv_OnOff_Lautstaerkeregler_Cx1_Aktiv), 0=Cx0_Inaktiv (CM_NM_aktiv_OnOff_Lautstaerkeregler_Cx0_Inaktiv)}, range raw 0..1, transfer-property=TRIGGERED  # Durch Kundenbetätigung des OnOff-Tasters des Lautstärkereglers soll das MIB über den CAN geweckt werden.
      frame NM_PID_XIX_HCP3_CANFD01: id 0x1B000123, to HCP3_IONode, frame-length=24, can-addressing-mode=EXTENDED, can-frame-rx-behavior=CAN-FD, can-frame-tx-behavior=CAN-FD, rx-identifier-range={lower-can-id=452984832, upper-can-id=452985855}
        nm pdu NM_PID_XIX_HCP3_CANFD01: length=24, unused-bit-pattern=0
          signal NM_PID_CBV_AWB_XIX_NM_PID_XIX_HCP3_CANFD01: start 4, 1 bit, little-endian, data-type-policy=OVERRIDE, i-signal-type=PRIMITIVE, init-value=0, base-type=BT_NM_PID_CBV_AWB, compu {0=Cx0_Passiver_WakeUp (CM_NM_PID_CBV_AWB_Cx0_Passiver_WakeUp), 1=Cx1_Aktiver_WakeUp (CM_NM_PID_CBV_AWB_Cx1_Aktiver_WakeUp)}, range raw 0..1, transfer-property=TRIGGERED  # Das Signal ist zu setzen, wenn das SG aktiv den Bus geweckt hat 0 = Passiver_WakeUp = SG hat das Netzwerk nicht aktiv geweckt 1 = Akitiver_WakeUp = SG hat das Netzwerk aktiv geweckt
          signal NM_PID_CBV_CRI_XIX_NM_PID_XIX_HCP3_CANFD01: start 6, 1 bit, little-endian, data-type-policy=OVERRIDE, i-signal-type=PRIMITIVE, init-value=1, base-type=BT_NM_PID_CBV_CRI, compu {1=Cx1_NM_mit_Clusteranforderungen (CM_NM_PID_CBV_CRI_Cx1_NM_mit_Clusteranforderungen), 0=Cx0_NM_ohne_Clusteranforderungen (CM_NM_PID_CBV_CRI_Cx0_NM_ohne_Clusteranforderungen)}, range raw 0..1, transfer-property=TRIGGERED  # Das Signal ist dauerhaft gesetzt, wenn das NM-Layout Cluster- Anforderungen enthält
          signal NM_PID_FCAB_XIX_NM_PID_XIX_HCP3_CANFD01: start 8, 56 bit, opaque, data-type-policy=OVERRIDE, i-signal-type=ARRAY, init-value=7 x 0b00000000, base-type=BT_NM_PID_FCAB, compu {65536=Cx10000_17_Audio (CM_NM_PID_FCAB_Cx10000_17_Audio), 17179869184=Cx400000000_35_ExteriorSound (CM_NM_PID_FCAB_Cx400000000_35_ExteriorSound), 1024=Cx400_11_Chassis (CM_NM_PID_FCAB_Cx400_11_Chassis), 4194304=Cx400000_23_Climate (CM_NM_PID_FCAB_Cx400000_23_Climate), 8796093022208=Cx80000000000_44_Diagnosis_Infotainment (CM_NM_PID_FCAB_Cx80000000000_44_Diagnosis_Infotainment), 16777216=Cx1000000_25_AccessSystemSensors (CM_NM_PID_FCAB_Cx1000000_25_AccessSystemSensors), 262144=Cx40000_19_Doors_Hatches (CM_NM_PID_FCAB_Cx40000_19_Doors_Hatches), 18014398509481984=Cx40000000000000_55_Dimming (CM_NM_PID_FCAB_Cx40000000000000_55_Dimming), 268435456=Cx10000000_29_SteeringColumnLock (CM_NM_PID_FCAB_Cx10000000_29_SteeringColumnLock), 35184372088832=Cx200000000000_46_Diagnosis_Light (CM_NM_PID_FCAB_Cx200000000000_46_Diagnosis_Light), 4294967296=Cx100000000_33_ExternalWirelessCommunication (CM_NM_PID_FCAB_Cx100000000_33_ExternalWirelessCommunication), 36028797018963968=Cx80000000000000_56_ChargingStatus (CM_NM_PID_FCAB_Cx80000000000000_56_ChargingStatus), 2147483648=Cx80000000_32_OnlineAccess (CM_NM_PID_FCAB_Cx80000000_32_OnlineAccess), 512=Cx200_10_Powertrain (CM_NM_PID_FCAB_Cx200_10_Powertrain), 4398046511104=Cx40000000000_43_Diagnosis_DrivingAssistance (CM_NM_PID_FCAB_Cx40000000000_43_Diagnosis_DrivingAssistance), 140737488355328=Cx800000000000_48_Diagnosis_ClimateTmeLINs (CM_NM_PID_FCAB_Cx800000000000_48_Diagnosis_ClimateTmeLINs), 549755813888=Cx8000000000_40_Diagnosis_Energy (CM_NM_PID_FCAB_Cx8000000000_40_Diagnosis_Energy), 4503599627370496=Cx10000000000000_53_Lock_Unlock (CM_NM_PID_FCAB_Cx10000000000000_53_Lock_Unlock), 524288=Cx80000_20_OptionalComfort (CM_NM_PID_FCAB_Cx80000_20_OptionalComfort), 256=Cx100_09_reserved (CM_NM_PID_FCAB_Cx100_09_reserved) (09_<reserved>), 536870912=Cx20000000_30_EnergyManagement (CM_NM_PID_FCAB_Cx20000000_30_EnergyManagement), 1099511627776=Cx10000000000_41_Diagnosis_Powertrain (CM_NM_PID_FCAB_Cx10000000000_41_Diagnosis_Powertrain), 34359738368=Cx800000000_36_Preheater (CM_NM_PID_FCAB_Cx800000000_36_Preheater), 70368744177664=Cx400000000000_47_Diagnosis_ComfortLINs (CM_NM_PID_FCAB_Cx400000000000_47_Diagnosis_ComfortLINs), 134217728=Cx8000000_28_OnboardTester_DataCollector (CM_NM_PID_FCAB_Cx8000000_28_OnboardTester_DataCollector), 2048=Cx800_12_GearSelector (CM_NM_PID_FCAB_Cx800_12_GearSelector), 64=Cx40_07_Basefunction_CrossSection (CM_NM_PID_FCAB_Cx40_07_Basefunction_CrossSection), 32=Cx20_06_Basefunction_ComfortLight (CM_NM_PID_FCAB_Cx20_06_Basefunction_ComfortLight), 4=Cx4_03_Basefunction_Chassis (CM_NM_PID_FCAB_Cx4_03_Basefunction_Chassis), 32768=Cx8000_16_InfotainmentDisplay (CM_NM_PID_FCAB_Cx8000_16_InfotainmentDisplay), 67108864=Cx4000000_27_Timemaster_Timer (CM_NM_PID_FCAB_Cx4000000_27_Timemaster_Timer), 1048576=Cx100000_21_AirSuspension (CM_NM_PID_FCAB_Cx100000_21_AirSuspension), 2097152=Cx200000_22_ExteriorLights (CM_NM_PID_FCAB_Cx200000_22_ExteriorLights), 33554432=Cx2000000_26_HighVoltage_Charging (CM_NM_PID_FCAB_Cx2000000_26_HighVoltage_Charging), 128=Cx80_08_Basefunction_Connectivity (CM_NM_PID_FCAB_Cx80_08_Basefunction_Connectivity), 281474976710656=Cx1000000000000_49_reserved (CM_NM_PID_FCAB_Cx1000000000000_49_reserved) (49_<reserved>), 16384=Cx4000_15_InstrumentclusterDisplay (CM_NM_PID_FCAB_Cx4000_15_InstrumentclusterDisplay), 8589934592=Cx200000000_34_GPS_Localization (CM_NM_PID_FCAB_Cx200000000_34_GPS_Localization), 8=Cx8_04_Basefunction_DrivingAssistance (CM_NM_PID_FCAB_Cx8_04_Basefunction_DrivingAssistance), 1=Cx1_01_CarWakeUp (CM_NM_PID_FCAB_Cx1_01_CarWakeUp), 8388608=Cx800000_24_ThermoManagement (CM_NM_PID_FCAB_Cx800000_24_ThermoManagement), 0=Cx0_Init (CM_NM_PID_FCAB_Cx0_Init), 1073741824=Cx40000000_31_MultifunctionalSteeringWheel (CM_NM_PID_FCAB_Cx40000000_31_MultifunctionalSteeringWheel), 4096=Cx1000_13_Airbag (CM_NM_PID_FCAB_Cx1000_13_Airbag), 17592186044416=Cx100000000000_45_Diagnosis_Comfort (CM_NM_PID_FCAB_Cx100000000000_45_Diagnosis_Comfort), 9007199254740992=Cx20000000000000_54_reserved (CM_NM_PID_FCAB_Cx20000000000000_54_reserved) (54_<reserved>), 2=Cx2_02_Basefunction_Powertrain (CM_NM_PID_FCAB_Cx2_02_Basefunction_Powertrain), 8192=Cx2000_14_InfotainmentExtensions (CM_NM_PID_FCAB_Cx2000_14_InfotainmentExtensions), 2199023255552=Cx20000000000_42_Diagnosis_FlexRay (CM_NM_PID_FCAB_Cx20000000000_42_Diagnosis_FlexRay), 68719476736=Cx1000000000_37_HighVoltage_WirelessChargingStation (CM_NM_PID_FCAB_Cx1000000000_37_HighVoltage_WirelessChargingStation), 131072=Cx20000_18_VirtualSideMirrors (CM_NM_PID_FCAB_Cx20000_18_VirtualSideMirrors), 16=Cx10_05_Basefunction_Infotainment (CM_NM_PID_FCAB_Cx10_05_Basefunction_Infotainment)}, range raw 0..36028797018963968, transfer-property=TRIGGERED-ON-CHANGE  # FCAB = Funktions-Cluster-Aktiv-Bits
          signal NM_PID_SNI_10_XIX_NM_PID_XIX_HCP3_CANFD01: start 128, 10 bit, little-endian, data-type-policy=OVERRIDE, i-signal-type=PRIMITIVE, init-value=291, base-type=BT_NM_PID_SNI_10, compu {291=Cx123_PID_SNI (CM_NM_PID_SNI_10_Cx123_PID_SNI)}, range raw 291, transfer-property=TRIGGERED  # Source Node-Identifier (SNI) identifiziert den Sender der NM-Botschaft (Knotenadresse) eindeutig im Fahrzeug
          signal NM_PID_NM_State_XIX_NM_PID_XIX_HCP3_CANFD01: start 144, 6 bit, little-endian, data-type-policy=OVERRIDE, i-signal-type=PRIMITIVE, init-value=0, base-type=BT_NM_PID_NM_State, compu {0=Cx0_Init (CM_NM_PID_NM_State_Cx0_Init), 2=Cx2_NM_RM_aus_PBSM (CM_NM_PID_NM_State_Cx2_NM_RM_aus_PBSM), 32=Cx20_reserved (CM_NM_PID_NM_State_Cx20_reserved), 16=Cx10_reserved (CM_NM_PID_NM_State_Cx10_reserved), 1=Cx1_NM_RM_aus_BSM (CM_NM_PID_NM_State_Cx1_NM_RM_aus_BSM), 8=Cx8_NM_NO_aus_RS (CM_NM_PID_NM_State_Cx8_NM_NO_aus_RS), 4=Cx4_NM_NO_aus_RM (CM_NM_PID_NM_State_Cx4_NM_NO_aus_RM)}, range raw 0..32, transfer-property=TRIGGERED  # 1 = Zustand Repeat Message (<-- Bus-Sleep Mode) 2 = Zustand Repeat Message (<-- Prepare Bus-Sleep Mode) 4 = Zustand Normal Operation (<-- Repeat Message) 8 = Zustand Normal Operation (<-- Ready Sleep)
          signal NM_PID_UDS_CC_XIX_NM_PID_XIX_HCP3_CANFD01: start 151, 1 bit, little-endian, data-type-policy=OVERRIDE, i-signal-type=PRIMITIVE, init-value=0, base-type=BT_NM_PID_UDS_CC, compu {0=Cx0_Inaktiv (CM_NM_PID_UDS_CC_Cx0_Inaktiv), 1=Cx1_CC_aktiv (CM_NM_PID_UDS_CC_Cx1_CC_aktiv)}, range raw 0..1, transfer-property=TRIGGERED  # Funktionseinschränkung aufgrund aktivem UDS-Communication Control, siehe VW80124
          signal NM_PID_Wakeup_V12_XIX_NM_PID_XIX_HCP3_CANFD01: start 152, 8 bit, little-endian, data-type-policy=OVERRIDE, i-signal-type=PRIMITIVE, init-value=0, base-type=BT_NM_PID_Wakeup_V12, compu {0=Cx0_Peripherie_Wakeup_Ursache_nicht_bekannt (CM_NM_PID_Wakeup_V12_Cx0_Peripherie_Wakeup_Ursache_nicht_bekannt), 2=Cx2_KL15_HW (CM_NM_PID_Wakeup_V12_Cx2_KL15_HW), 1=Cx1_Bus_Wakeup (CM_NM_PID_Wakeup_V12_Cx1_Bus_Wakeup)}, range raw 0..2, transfer-property=TRIGGERED  # enthält die Weckursache; stehen mehrere Weckursachen parallel an, dann muss der kleinste Wert übertragen werden
          signal NM_PID_NM_aktiv_KL15_XIX_NM_PID_XIX_HCP3_CANFD01: start 160, 1 bit, little-endian, data-type-policy=OVERRIDE, i-signal-type=PRIMITIVE, init-value=0, base-type=BT_NM_PID_NM_aktiv_KL15, compu {0=Cx0_Inaktiv (CM_NM_PID_NM_aktiv_KL15_Cx0_Inaktiv), 1=Cx1_KL15_EIN (CM_NM_PID_NM_aktiv_KL15_Cx1_KL15_EIN)}, range raw 0..1, transfer-property=TRIGGERED  # Steuergerät hat KL15-EIN erkannt
          signal NM_PID_NM_aktiv_Diag_XIX_NM_PID_XIX_HCP3_CANFD01: start 161, 1 bit, little-endian, data-type-policy=OVERRIDE, i-signal-type=PRIMITIVE, init-value=0, base-type=BT_NM_PID_NM_aktiv_Diag, compu {1=Cx1_Diagnose_aktiv (CM_NM_PID_NM_aktiv_Diag_Cx1_Diagnose_aktiv), 0=Cx0_Inaktiv (CM_NM_PID_NM_aktiv_Diag_Cx0_Inaktiv)}, range raw 0..1, transfer-property=TRIGGERED  # Diagnose befindet sich nach VW80124 in einer NonDefaultDiagnostic-Session, z.B. ExtendedDiagnostic-Session
          signal NM_PID_NM_aktiv_Tmin_XIX_NM_PID_XIX_HCP3_CANFD01: start 162, 1 bit, little-endian, data-type-policy=OVERRIDE, i-signal-type=PRIMITIVE, init-value=0, base-type=BT_NM_PID_NM_aktiv_Tmin, compu {1=Cx1_Mindestaktivzeit (CM_NM_PID_NM_aktiv_Tmin_Cx1_Mindestaktivzeit), 0=Cx0_Inaktiv (CM_NM_PID_NM_aktiv_Tmin_Cx0_Inaktiv)}, range raw 0..1, transfer-property=TRIGGERED  # Mindestaktivzeit ist noch nicht abgelaufen (bei jedem Weckereignis wird die Mindestaktivzeit neu gestartet)
      frame NM_WLC1_XIX_HCP3_CANFD01: id 0x1B0000A5, to HCP3_IONode, frame-length=24, can-addressing-mode=EXTENDED, can-frame-rx-behavior=CAN-FD, can-frame-tx-behavior=CAN-FD, rx-identifier-range={lower-can-id=452984832, upper-can-id=452985855}
        nm pdu NM_WLC1_XIX_HCP3_CANFD01: length=24, unused-bit-pattern=0
          signal NM_WLC1_CBV_AWB_XIX_NM_WLC1_XIX_HCP3_CANFD01: start 4, 1 bit, little-endian, data-type-policy=OVERRIDE, i-signal-type=PRIMITIVE, init-value=0, base-type=BT_NM_WLC1_CBV_AWB, compu {1=Cx1_Aktiver_WakeUp (CM_NM_WLC1_CBV_AWB_Cx1_Aktiver_WakeUp), 0=Cx0_Passiver_WakeUp (CM_NM_WLC1_CBV_AWB_Cx0_Passiver_WakeUp)}, range raw 0..1, transfer-property=TRIGGERED  # Das Signal ist zu setzen, wenn das SG aktiv den Bus geweckt hat 0 = Passiver_WakeUp = SG hat das Netzwerk nicht aktiv geweckt 1 = Akitiver_WakeUp = SG hat das Netzwerk aktiv geweckt
          signal NM_WLC1_CBV_CRI_XIX_NM_WLC1_XIX_HCP3_CANFD01: start 6, 1 bit, little-endian, data-type-policy=OVERRIDE, i-signal-type=PRIMITIVE, init-value=1, base-type=BT_NM_WLC1_CBV_CRI, compu {0=Cx0_NM_ohne_Clusteranforderungen (CM_NM_WLC1_CBV_CRI_Cx0_NM_ohne_Clusteranforderungen), 1=Cx1_NM_mit_Clusteranforderungen (CM_NM_WLC1_CBV_CRI_Cx1_NM_mit_Clusteranforderungen)}, range raw 0..1, transfer-property=TRIGGERED  # Das Signal ist dauerhaft gesetzt, wenn das NM-Layout Cluster- Anforderungen enthält
          signal NM_WLC1_FCAB_XIX_NM_WLC1_XIX_HCP3_CANFD01: start 8, 56 bit, opaque, data-type-policy=OVERRIDE, i-signal-type=ARRAY, init-value=7 x 0b00000000, base-type=BT_NM_WLC1_FCAB, compu {16384=Cx4000_15_InstrumentclusterDisplay (CM_NM_WLC1_FCAB_Cx4000_15_InstrumentclusterDisplay), 17179869184=Cx400000000_35_ExteriorSound (CM_NM_WLC1_FCAB_Cx400000000_35_ExteriorSound), 16777216=Cx1000000_25_AccessSystemSensors (CM_NM_WLC1_FCAB_Cx1000000_25_AccessSystemSensors), 140737488355328=Cx800000000000_48_Diagnosis_ClimateTmeLINs (CM_NM_WLC1_FCAB_Cx800000000000_48_Diagnosis_ClimateTmeLINs), 4=Cx4_03_Basefunction_Chassis (CM_NM_WLC1_FCAB_Cx4_03_Basefunction_Chassis), 256=Cx100_09_reserved (CM_NM_WLC1_FCAB_Cx100_09_reserved) (09_<reserved>), 64=Cx40_07_Basefunction_CrossSection (CM_NM_WLC1_FCAB_Cx40_07_Basefunction_CrossSection), 2097152=Cx200000_22_ExteriorLights (CM_NM_WLC1_FCAB_Cx200000_22_ExteriorLights), 2147483648=Cx80000000_32_OnlineAccess (CM_NM_WLC1_FCAB_Cx80000000_32_OnlineAccess), 8=Cx8_04_Basefunction_DrivingAssistance (CM_NM_WLC1_FCAB_Cx8_04_Basefunction_DrivingAssistance), 1024=Cx400_11_Chassis (CM_NM_WLC1_FCAB_Cx400_11_Chassis), 512=Cx200_10_Powertrain (CM_NM_WLC1_FCAB_Cx200_10_Powertrain), 1099511627776=Cx10000000000_41_Diagnosis_Powertrain (CM_NM_WLC1_FCAB_Cx10000000000_41_Diagnosis_Powertrain), 536870912=Cx20000000_30_EnergyManagement (CM_NM_WLC1_FCAB_Cx20000000_30_EnergyManagement), 18014398509481984=Cx40000000000000_55_Dimming (CM_NM_WLC1_FCAB_Cx40000000000000_55_Dimming), 4503599627370496=Cx10000000000000_53_Lock_Unlock (CM_NM_WLC1_FCAB_Cx10000000000000_53_Lock_Unlock), 16=Cx10_05_Basefunction_Infotainment (CM_NM_WLC1_FCAB_Cx10_05_Basefunction_Infotainment), 2199023255552=Cx20000000000_42_Diagnosis_FlexRay (CM_NM_WLC1_FCAB_Cx20000000000_42_Diagnosis_FlexRay), 70368744177664=Cx400000000000_47_Diagnosis_ComfortLINs (CM_NM_WLC1_FCAB_Cx400000000000_47_Diagnosis_ComfortLINs), 0=Cx0_Init (CM_NM_WLC1_FCAB_Cx0_Init), 134217728=Cx8000000_28_OnboardTester_DataCollector (CM_NM_WLC1_FCAB_Cx8000000_28_OnboardTester_DataCollector), 131072=Cx20000_18_VirtualSideMirrors (CM_NM_WLC1_FCAB_Cx20000_18_VirtualSideMirrors), 1073741824=Cx40000000_31_MultifunctionalSteeringWheel (CM_NM_WLC1_FCAB_Cx40000000_31_MultifunctionalSteeringWheel), 1048576=Cx100000_21_AirSuspension (CM_NM_WLC1_FCAB_Cx100000_21_AirSuspension), 1=Cx1_01_CarWakeUp (CM_NM_WLC1_FCAB_Cx1_01_CarWakeUp), 2=Cx2_02_Basefunction_Powertrain (CM_NM_WLC1_FCAB_Cx2_02_Basefunction_Powertrain), 4194304=Cx400000_23_Climate (CM_NM_WLC1_FCAB_Cx400000_23_Climate), 34359738368=Cx800000000_36_Preheater (CM_NM_WLC1_FCAB_Cx800000000_36_Preheater), 33554432=Cx2000000_26_HighVoltage_Charging (CM_NM_WLC1_FCAB_Cx2000000_26_HighVoltage_Charging), 67108864=Cx4000000_27_Timemaster_Timer (CM_NM_WLC1_FCAB_Cx4000000_27_Timemaster_Timer), 262144=Cx40000_19_Doors_Hatches (CM_NM_WLC1_FCAB_Cx40000_19_Doors_Hatches), 524288=Cx80000_20_OptionalComfort (CM_NM_WLC1_FCAB_Cx80000_20_OptionalComfort), 549755813888=Cx8000000000_40_Diagnosis_Energy (CM_NM_WLC1_FCAB_Cx8000000000_40_Diagnosis_Energy), 17592186044416=Cx100000000000_45_Diagnosis_Comfort (CM_NM_WLC1_FCAB_Cx100000000000_45_Diagnosis_Comfort), 8796093022208=Cx80000000000_44_Diagnosis_Infotainment (CM_NM_WLC1_FCAB_Cx80000000000_44_Diagnosis_Infotainment), 32=Cx20_06_Basefunction_ComfortLight (CM_NM_WLC1_FCAB_Cx20_06_Basefunction_ComfortLight), 8192=Cx2000_14_InfotainmentExtensions (CM_NM_WLC1_FCAB_Cx2000_14_InfotainmentExtensions), 36028797018963968=Cx80000000000000_56_ChargingStatus (CM_NM_WLC1_FCAB_Cx80000000000000_56_ChargingStatus), 4096=Cx1000_13_Airbag (CM_NM_WLC1_FCAB_Cx1000_13_Airbag), 35184372088832=Cx200000000000_46_Diagnosis_Light (CM_NM_WLC1_FCAB_Cx200000000000_46_Diagnosis_Light), 8388608=Cx800000_24_ThermoManagement (CM_NM_WLC1_FCAB_Cx800000_24_ThermoManagement), 2048=Cx800_12_GearSelector (CM_NM_WLC1_FCAB_Cx800_12_GearSelector), 4294967296=Cx100000000_33_ExternalWirelessCommunication (CM_NM_WLC1_FCAB_Cx100000000_33_ExternalWirelessCommunication), 68719476736=Cx1000000000_37_HighVoltage_WirelessChargingStation (CM_NM_WLC1_FCAB_Cx1000000000_37_HighVoltage_WirelessChargingStation), 9007199254740992=Cx20000000000000_54_reserved (CM_NM_WLC1_FCAB_Cx20000000000000_54_reserved) (54_<reserved>), 128=Cx80_08_Basefunction_Connectivity (CM_NM_WLC1_FCAB_Cx80_08_Basefunction_Connectivity), 8589934592=Cx200000000_34_GPS_Localization (CM_NM_WLC1_FCAB_Cx200000000_34_GPS_Localization), 32768=Cx8000_16_InfotainmentDisplay (CM_NM_WLC1_FCAB_Cx8000_16_InfotainmentDisplay), 65536=Cx10000_17_Audio (CM_NM_WLC1_FCAB_Cx10000_17_Audio), 281474976710656=Cx1000000000000_49_reserved (CM_NM_WLC1_FCAB_Cx1000000000000_49_reserved) (49_<reserved>), 268435456=Cx10000000_29_SteeringColumnLock (CM_NM_WLC1_FCAB_Cx10000000_29_SteeringColumnLock), 4398046511104=Cx40000000000_43_Diagnosis_DrivingAssistance (CM_NM_WLC1_FCAB_Cx40000000000_43_Diagnosis_DrivingAssistance)}, range raw 0..36028797018963968, transfer-property=TRIGGERED-ON-CHANGE  # FCAB = Funktions-Cluster-Aktiv-Bits
          signal NM_WLC1_SNI_10_XIX_NM_WLC1_XIX_HCP3_CANFD01: start 128, 10 bit, little-endian, data-type-policy=OVERRIDE, i-signal-type=PRIMITIVE, init-value=165, base-type=BT_NM_WLC1_SNI_10, compu {165=Cxa5_WLC1_SNI (CM_NM_WLC1_SNI_10_Cxa5_WLC1_SNI)}, range raw 165, transfer-property=TRIGGERED  # Source Node-Identifier (SNI) identifiziert den Sender der NM-Botschaft (Knotenadresse) eindeutig im Fahrzeug
          signal NM_WLC1_NM_State_XIX_NM_WLC1_XIX_HCP3_CANFD01: start 144, 6 bit, little-endian, data-type-policy=OVERRIDE, i-signal-type=PRIMITIVE, init-value=0, base-type=BT_NM_WLC1_NM_State, compu {1=Cx1_NM_RM_aus_BSM (CM_NM_WLC1_NM_State_Cx1_NM_RM_aus_BSM), 2=Cx2_NM_RM_aus_PBSM (CM_NM_WLC1_NM_State_Cx2_NM_RM_aus_PBSM), 8=Cx8_NM_NO_aus_RS (CM_NM_WLC1_NM_State_Cx8_NM_NO_aus_RS), 32=Cx20_reserved (CM_NM_WLC1_NM_State_Cx20_reserved), 4=Cx4_NM_NO_aus_RM (CM_NM_WLC1_NM_State_Cx4_NM_NO_aus_RM), 0=Cx0_Init (CM_NM_WLC1_NM_State_Cx0_Init), 16=Cx10_reserved (CM_NM_WLC1_NM_State_Cx10_reserved)}, range raw 0..32, transfer-property=TRIGGERED  # 1 = Zustand Repeat Message (<-- Bus-Sleep Mode) 2 = Zustand Repeat Message (<-- Prepare Bus-Sleep Mode) 4 = Zustand Normal Operation (<-- Repeat Message) 8 = Zustand Normal Operation (<-- Ready Sleep)
          signal NM_WLC1_UDS_CC_XIX_NM_WLC1_XIX_HCP3_CANFD01: start 151, 1 bit, little-endian, data-type-policy=OVERRIDE, i-signal-type=PRIMITIVE, init-value=0, base-type=BT_NM_WLC1_UDS_CC, compu {1=Cx1_CC_aktiv (CM_NM_WLC1_UDS_CC_Cx1_CC_aktiv), 0=Cx0_Inaktiv (CM_NM_WLC1_UDS_CC_Cx0_Inaktiv)}, range raw 0..1, transfer-property=TRIGGERED  # Funktionseinschränkung aufgrund aktivem UDS-Communication Control, siehe VW80124
          signal NM_WLC1_Wakeup_V12_XIX_NM_WLC1_XIX_HCP3_CANFD01: start 152, 8 bit, little-endian, data-type-policy=OVERRIDE, i-signal-type=PRIMITIVE, init-value=0, base-type=BT_NM_WLC1_Wakeup_V12, compu {0=Cx0_Peripherie_Wakeup_Ursache_nicht_bekannt (CM_NM_WLC1_Wakeup_V12_Cx0_Peripherie_Wakeup_Ursache_nicht_bekannt), 1=Cx1_Bus_Wakeup (CM_NM_WLC1_Wakeup_V12_Cx1_Bus_Wakeup), 2=Cx2_KL15_HW (CM_NM_WLC1_Wakeup_V12_Cx2_KL15_HW)}, range raw 0..2, transfer-property=TRIGGERED  # enthält die Weckursache; stehen mehrere Weckursachen parallel an, dann muss der kleinste Wert übertragen werden
          signal NM_WLC1_NM_aktiv_KL15_XIX_NM_WLC1_XIX_HCP3_CANFD01: start 160, 1 bit, little-endian, data-type-policy=OVERRIDE, i-signal-type=PRIMITIVE, init-value=0, base-type=BT_NM_WLC1_NM_aktiv_KL15, compu {0=Cx0_Inaktiv (CM_NM_WLC1_NM_aktiv_KL15_Cx0_Inaktiv), 1=Cx1_KL15_EIN (CM_NM_WLC1_NM_aktiv_KL15_Cx1_KL15_EIN)}, range raw 0..1, transfer-property=TRIGGERED  # Steuergerät hat KL15-EIN erkannt
          signal NM_WLC1_NM_aktiv_Diag_XIX_NM_WLC1_XIX_HCP3_CANFD01: start 161, 1 bit, little-endian, data-type-policy=OVERRIDE, i-signal-type=PRIMITIVE, init-value=0, base-type=BT_NM_WLC1_NM_aktiv_Diag, compu {1=Cx1_Diagnose_aktiv (CM_NM_WLC1_NM_aktiv_Diag_Cx1_Diagnose_aktiv), 0=Cx0_Inaktiv (CM_NM_WLC1_NM_aktiv_Diag_Cx0_Inaktiv)}, range raw 0..1, transfer-property=TRIGGERED  # Diagnose befindet sich nach VW80124 in einer NonDefaultDiagnostic-Session, z.B. ExtendedDiagnostic-Session
          signal NM_WLC1_NM_aktiv_Tmin_XIX_NM_WLC1_XIX_HCP3_CANFD01: start 162, 1 bit, little-endian, data-type-policy=OVERRIDE, i-signal-type=PRIMITIVE, init-value=0, base-type=BT_NM_WLC1_NM_aktiv_Tmin, compu {0=Cx0_Inaktiv (CM_NM_WLC1_NM_aktiv_Tmin_Cx0_Inaktiv), 1=Cx1_Mindestaktivzeit (CM_NM_WLC1_NM_aktiv_Tmin_Cx1_Mindestaktivzeit)}, range raw 0..1, transfer-property=TRIGGERED  # Mindestaktivzeit ist noch nicht abgelaufen (bei jedem Weckereignis wird die Mindestaktivzeit neu gestartet)
      frame NM_WLC2_XIX_HCP3_CANFD01: id 0x1B0000A6, to HCP3_IONode, frame-length=24, can-addressing-mode=EXTENDED, can-frame-rx-behavior=CAN-FD, can-frame-tx-behavior=CAN-FD, rx-identifier-range={lower-can-id=452984832, upper-can-id=452985855}
        nm pdu NM_WLC2_XIX_HCP3_CANFD01: length=24, unused-bit-pattern=0
          signal NM_WLC2_CBV_AWB_XIX_NM_WLC2_XIX_HCP3_CANFD01: start 4, 1 bit, little-endian, data-type-policy=OVERRIDE, i-signal-type=PRIMITIVE, init-value=0, base-type=BT_NM_WLC2_CBV_AWB, compu {1=Cx1_Aktiver_WakeUp (CM_NM_WLC2_CBV_AWB_Cx1_Aktiver_WakeUp), 0=Cx0_Passiver_WakeUp (CM_NM_WLC2_CBV_AWB_Cx0_Passiver_WakeUp)}, range raw 0..1, transfer-property=TRIGGERED  # Das Signal ist zu setzen, wenn das SG aktiv den Bus geweckt hat 0 = Passiver_WakeUp = SG hat das Netzwerk nicht aktiv geweckt 1 = Akitiver_WakeUp = SG hat das Netzwerk aktiv geweckt
          signal NM_WLC2_CBV_CRI_XIX_NM_WLC2_XIX_HCP3_CANFD01: start 6, 1 bit, little-endian, data-type-policy=OVERRIDE, i-signal-type=PRIMITIVE, init-value=1, base-type=BT_NM_WLC2_CBV_CRI, compu {0=Cx0_NM_ohne_Clusteranforderungen (CM_NM_WLC2_CBV_CRI_Cx0_NM_ohne_Clusteranforderungen), 1=Cx1_NM_mit_Clusteranforderungen (CM_NM_WLC2_CBV_CRI_Cx1_NM_mit_Clusteranforderungen)}, range raw 0..1, transfer-property=TRIGGERED  # Das Signal ist dauerhaft gesetzt, wenn das NM-Layout Cluster- Anforderungen enthält
          signal NM_WLC2_FCAB_XIX_NM_WLC2_XIX_HCP3_CANFD01: start 8, 56 bit, opaque, data-type-policy=OVERRIDE, i-signal-type=ARRAY, init-value=7 x 0b00000000, base-type=BT_NM_WLC2_FCAB, compu {32=Cx20_06_Basefunction_ComfortLight (CM_NM_WLC2_FCAB_Cx20_06_Basefunction_ComfortLight), 8589934592=Cx200000000_34_GPS_Localization (CM_NM_WLC2_FCAB_Cx200000000_34_GPS_Localization), 4096=Cx1000_13_Airbag (CM_NM_WLC2_FCAB_Cx1000_13_Airbag), 4294967296=Cx100000000_33_ExternalWirelessCommunication (CM_NM_WLC2_FCAB_Cx100000000_33_ExternalWirelessCommunication), 9007199254740992=Cx20000000000000_54_reserved (CM_NM_WLC2_FCAB_Cx20000000000000_54_reserved) (54_<reserved>), 68719476736=Cx1000000000_37_HighVoltage_WirelessChargingStation (CM_NM_WLC2_FCAB_Cx1000000000_37_HighVoltage_WirelessChargingStation), 2097152=Cx200000_22_ExteriorLights (CM_NM_WLC2_FCAB_Cx200000_22_ExteriorLights), 1024=Cx400_11_Chassis (CM_NM_WLC2_FCAB_Cx400_11_Chassis), 70368744177664=Cx400000000000_47_Diagnosis_ComfortLINs (CM_NM_WLC2_FCAB_Cx400000000000_47_Diagnosis_ComfortLINs), 1048576=Cx100000_21_AirSuspension (CM_NM_WLC2_FCAB_Cx100000_21_AirSuspension), 17179869184=Cx400000000_35_ExteriorSound (CM_NM_WLC2_FCAB_Cx400000000_35_ExteriorSound), 16777216=Cx1000000_25_AccessSystemSensors (CM_NM_WLC2_FCAB_Cx1000000_25_AccessSystemSensors), 64=Cx40_07_Basefunction_CrossSection (CM_NM_WLC2_FCAB_Cx40_07_Basefunction_CrossSection), 549755813888=Cx8000000000_40_Diagnosis_Energy (CM_NM_WLC2_FCAB_Cx8000000000_40_Diagnosis_Energy), 2048=Cx800_12_GearSelector (CM_NM_WLC2_FCAB_Cx800_12_GearSelector), 281474976710656=Cx1000000000000_49_reserved (CM_NM_WLC2_FCAB_Cx1000000000000_49_reserved) (49_<reserved>), 1073741824=Cx40000000_31_MultifunctionalSteeringWheel (CM_NM_WLC2_FCAB_Cx40000000_31_MultifunctionalSteeringWheel), 16384=Cx4000_15_InstrumentclusterDisplay (CM_NM_WLC2_FCAB_Cx4000_15_InstrumentclusterDisplay), 1099511627776=Cx10000000000_41_Diagnosis_Powertrain (CM_NM_WLC2_FCAB_Cx10000000000_41_Diagnosis_Powertrain), 8=Cx8_04_Basefunction_DrivingAssistance (CM_NM_WLC2_FCAB_Cx8_04_Basefunction_DrivingAssistance), 128=Cx80_08_Basefunction_Connectivity (CM_NM_WLC2_FCAB_Cx80_08_Basefunction_Connectivity), 34359738368=Cx800000000_36_Preheater (CM_NM_WLC2_FCAB_Cx800000000_36_Preheater), 4194304=Cx400000_23_Climate (CM_NM_WLC2_FCAB_Cx400000_23_Climate), 262144=Cx40000_19_Doors_Hatches (CM_NM_WLC2_FCAB_Cx40000_19_Doors_Hatches), 18014398509481984=Cx40000000000000_55_Dimming (CM_NM_WLC2_FCAB_Cx40000000000000_55_Dimming), 4503599627370496=Cx10000000000000_53_Lock_Unlock (CM_NM_WLC2_FCAB_Cx10000000000000_53_Lock_Unlock), 134217728=Cx8000000_28_OnboardTester_DataCollector (CM_NM_WLC2_FCAB_Cx8000000_28_OnboardTester_DataCollector), 8388608=Cx800000_24_ThermoManagement (CM_NM_WLC2_FCAB_Cx800000_24_ThermoManagement), 16=Cx10_05_Basefunction_Infotainment (CM_NM_WLC2_FCAB_Cx10_05_Basefunction_Infotainment), 8192=Cx2000_14_InfotainmentExtensions (CM_NM_WLC2_FCAB_Cx2000_14_InfotainmentExtensions), 8796093022208=Cx80000000000_44_Diagnosis_Infotainment (CM_NM_WLC2_FCAB_Cx80000000000_44_Diagnosis_Infotainment), 524288=Cx80000_20_OptionalComfort (CM_NM_WLC2_FCAB_Cx80000_20_OptionalComfort), 2=Cx2_02_Basefunction_Powertrain (CM_NM_WLC2_FCAB_Cx2_02_Basefunction_Powertrain), 36028797018963968=Cx80000000000000_56_ChargingStatus (CM_NM_WLC2_FCAB_Cx80000000000000_56_ChargingStatus), 35184372088832=Cx200000000000_46_Diagnosis_Light (CM_NM_WLC2_FCAB_Cx200000000000_46_Diagnosis_Light), 0=Cx0_Init (CM_NM_WLC2_FCAB_Cx0_Init), 256=Cx100_09_reserved (CM_NM_WLC2_FCAB_Cx100_09_reserved) (09_<reserved>), 67108864=Cx4000000_27_Timemaster_Timer (CM_NM_WLC2_FCAB_Cx4000000_27_Timemaster_Timer), 65536=Cx10000_17_Audio (CM_NM_WLC2_FCAB_Cx10000_17_Audio), 2199023255552=Cx20000000000_42_Diagnosis_FlexRay (CM_NM_WLC2_FCAB_Cx20000000000_42_Diagnosis_FlexRay), 32768=Cx8000_16_InfotainmentDisplay (CM_NM_WLC2_FCAB_Cx8000_16_InfotainmentDisplay), 140737488355328=Cx800000000000_48_Diagnosis_ClimateTmeLINs (CM_NM_WLC2_FCAB_Cx800000000000_48_Diagnosis_ClimateTmeLINs), 512=Cx200_10_Powertrain (CM_NM_WLC2_FCAB_Cx200_10_Powertrain), 17592186044416=Cx100000000000_45_Diagnosis_Comfort (CM_NM_WLC2_FCAB_Cx100000000000_45_Diagnosis_Comfort), 1=Cx1_01_CarWakeUp (CM_NM_WLC2_FCAB_Cx1_01_CarWakeUp), 536870912=Cx20000000_30_EnergyManagement (CM_NM_WLC2_FCAB_Cx20000000_30_EnergyManagement), 4398046511104=Cx40000000000_43_Diagnosis_DrivingAssistance (CM_NM_WLC2_FCAB_Cx40000000000_43_Diagnosis_DrivingAssistance), 2147483648=Cx80000000_32_OnlineAccess (CM_NM_WLC2_FCAB_Cx80000000_32_OnlineAccess), 268435456=Cx10000000_29_SteeringColumnLock (CM_NM_WLC2_FCAB_Cx10000000_29_SteeringColumnLock), 33554432=Cx2000000_26_HighVoltage_Charging (CM_NM_WLC2_FCAB_Cx2000000_26_HighVoltage_Charging), 131072=Cx20000_18_VirtualSideMirrors (CM_NM_WLC2_FCAB_Cx20000_18_VirtualSideMirrors), 4=Cx4_03_Basefunction_Chassis (CM_NM_WLC2_FCAB_Cx4_03_Basefunction_Chassis)}, range raw 0..36028797018963968, transfer-property=TRIGGERED-ON-CHANGE  # FCAB = Funktions-Cluster-Aktiv-Bits
          signal NM_WLC2_SNI_10_XIX_NM_WLC2_XIX_HCP3_CANFD01: start 128, 10 bit, little-endian, data-type-policy=OVERRIDE, i-signal-type=PRIMITIVE, init-value=166, base-type=BT_NM_WLC2_SNI_10, compu {166=Cxa6_WLC2_SNI (CM_NM_WLC2_SNI_10_Cxa6_WLC2_SNI)}, range raw 166, transfer-property=TRIGGERED  # Source Node-Identifier (SNI) identifiziert den Sender der NM-Botschaft (Knotenadresse) eindeutig im Fahrzeug
          signal NM_WLC2_NM_State_XIX_NM_WLC2_XIX_HCP3_CANFD01: start 144, 6 bit, little-endian, data-type-policy=OVERRIDE, i-signal-type=PRIMITIVE, init-value=0, base-type=BT_NM_WLC2_NM_State, compu {8=Cx8_NM_NO_aus_RS (CM_NM_WLC2_NM_State_Cx8_NM_NO_aus_RS), 32=Cx20_reserved (CM_NM_WLC2_NM_State_Cx20_reserved), 16=Cx10_reserved (CM_NM_WLC2_NM_State_Cx10_reserved), 2=Cx2_NM_RM_aus_PBSM (CM_NM_WLC2_NM_State_Cx2_NM_RM_aus_PBSM), 1=Cx1_NM_RM_aus_BSM (CM_NM_WLC2_NM_State_Cx1_NM_RM_aus_BSM), 4=Cx4_NM_NO_aus_RM (CM_NM_WLC2_NM_State_Cx4_NM_NO_aus_RM), 0=Cx0_Init (CM_NM_WLC2_NM_State_Cx0_Init)}, range raw 0..32, transfer-property=TRIGGERED  # 1 = Zustand Repeat Message (<-- Bus-Sleep Mode) 2 = Zustand Repeat Message (<-- Prepare Bus-Sleep Mode) 4 = Zustand Normal Operation (<-- Repeat Message) 8 = Zustand Normal Operation (<-- Ready Sleep)
          signal NM_WLC2_UDS_CC_XIX_NM_WLC2_XIX_HCP3_CANFD01: start 151, 1 bit, little-endian, data-type-policy=OVERRIDE, i-signal-type=PRIMITIVE, init-value=0, base-type=BT_NM_WLC2_UDS_CC, compu {0=Cx0_Inaktiv (CM_NM_WLC2_UDS_CC_Cx0_Inaktiv), 1=Cx1_CC_aktiv (CM_NM_WLC2_UDS_CC_Cx1_CC_aktiv)}, range raw 0..1, transfer-property=TRIGGERED  # Funktionseinschränkung aufgrund aktivem UDS-Communication Control, siehe VW80124
          signal NM_WLC2_Wakeup_V12_XIX_NM_WLC2_XIX_HCP3_CANFD01: start 152, 8 bit, little-endian, data-type-policy=OVERRIDE, i-signal-type=PRIMITIVE, init-value=0, base-type=BT_NM_WLC2_Wakeup_V12, compu {1=Cx1_Bus_Wakeup (CM_NM_WLC2_Wakeup_V12_Cx1_Bus_Wakeup), 0=Cx0_Peripherie_Wakeup_Ursache_nicht_bekannt (CM_NM_WLC2_Wakeup_V12_Cx0_Peripherie_Wakeup_Ursache_nicht_bekannt), 2=Cx2_KL15_HW (CM_NM_WLC2_Wakeup_V12_Cx2_KL15_HW)}, range raw 0..2, transfer-property=TRIGGERED  # enthält die Weckursache; stehen mehrere Weckursachen parallel an, dann muss der kleinste Wert übertragen werden
          signal NM_WLC2_NM_aktiv_KL15_XIX_NM_WLC2_XIX_HCP3_CANFD01: start 160, 1 bit, little-endian, data-type-policy=OVERRIDE, i-signal-type=PRIMITIVE, init-value=0, base-type=BT_NM_WLC2_NM_aktiv_KL15, compu {1=Cx1_KL15_EIN (CM_NM_WLC2_NM_aktiv_KL15_Cx1_KL15_EIN), 0=Cx0_Inaktiv (CM_NM_WLC2_NM_aktiv_KL15_Cx0_Inaktiv)}, range raw 0..1, transfer-property=TRIGGERED  # Steuergerät hat KL15-EIN erkannt
          signal NM_WLC2_NM_aktiv_Diag_XIX_NM_WLC2_XIX_HCP3_CANFD01: start 161, 1 bit, little-endian, data-type-policy=OVERRIDE, i-signal-type=PRIMITIVE, init-value=0, base-type=BT_NM_WLC2_NM_aktiv_Diag, compu {1=Cx1_Diagnose_aktiv (CM_NM_WLC2_NM_aktiv_Diag_Cx1_Diagnose_aktiv), 0=Cx0_Inaktiv (CM_NM_WLC2_NM_aktiv_Diag_Cx0_Inaktiv)}, range raw 0..1, transfer-property=TRIGGERED  # Diagnose befindet sich nach VW80124 in einer NonDefaultDiagnostic-Session, z.B. ExtendedDiagnostic-Session
          signal NM_WLC2_NM_aktiv_Tmin_XIX_NM_WLC2_XIX_HCP3_CANFD01: start 162, 1 bit, little-endian, data-type-policy=OVERRIDE, i-signal-type=PRIMITIVE, init-value=0, base-type=BT_NM_WLC2_NM_aktiv_Tmin, compu {1=Cx1_Mindestaktivzeit (CM_NM_WLC2_NM_aktiv_Tmin_Cx1_Mindestaktivzeit), 0=Cx0_Inaktiv (CM_NM_WLC2_NM_aktiv_Tmin_Cx0_Inaktiv)}, range raw 0..1, transfer-property=TRIGGERED  # Mindestaktivzeit ist noch nicht abgelaufen (bei jedem Weckereignis wird die Mindestaktivzeit neu gestartet)
      frame NVEM_12_XIX_HCP3_CANFD01: id 0x237, from HCP3_IONode, frame-length=12, can-addressing-mode=STANDARD, can-frame-rx-behavior=CAN-FD, can-frame-tx-behavior=CAN-FD
        pdu NVEM_12_XIX_HCP3_CANFD01: length=12, transmission-mode-true-timing=cyclic-timing={time-offset=0.0, time-period=0.1}, unused-bit-pattern=0
          signal NVEM_12_CRC_XIX_NVEM_12_XIX_HCP3_CANFD01: start 0, 8 bit, little-endian, data-type-policy=OVERRIDE, i-signal-type=PRIMITIVE, init-value=0, base-type=BT_NVEM_12_CRC, compu {phys=raw for raw 0..255}, range phys 0..255, raw 0..255, transfer-property=TRIGGERED-WITHOUT-REPETITION  # Für MLB: Berechnung siehe Lastenheft "Kommunikationsabsicherung für FlexRay und CAN" Ab MQB und MLBevo: Berechnung siehe Lastenheft "End-to-End Kommunikationsabsicherung" Endwerte siehe Begleitdokument "S-PDU Kennungsfolgen"
          signal NVEM_12_BZ_XIX_NVEM_12_XIX_HCP3_CANFD01: start 8, 4 bit, little-endian, data-type-policy=OVERRIDE, i-signal-type=PRIMITIVE, init-value=0, base-type=BT_NVEM_12_BZ, compu {phys=raw for raw 0..15}, range phys 0..15, raw 0..15, transfer-property=TRIGGERED-WITHOUT-REPETITION  # 4bit Botschaftszähler, wird mit jeder Sendebotschaft inkrementiert
          signal NVEM_Bordnetzdiagnose_XIX_NVEM_12_XIX_HCP3_CANFD01: start 12, 2 bit, little-endian, data-type-policy=OVERRIDE, i-signal-type=PRIMITIVE, init-value=0, base-type=BT_NVEM_Bordnetzdiagnose, compu {1=Cx1_Warnung_1 (CM_NVEM_Bordnetzdiagnose_Cx1_Warnung_1), 2=Cx2_Warnung_2 (CM_NVEM_Bordnetzdiagnose_Cx2_Warnung_2), 3=Cx3_Warnung_3 (CM_NVEM_Bordnetzdiagnose_Cx3_Warnung_3), 0=Cx0_kein_Fehler (CM_NVEM_Bordnetzdiagnose_Cx0_kein_Fehler)}, range raw 0..3, transfer-property=TRIGGERED-WITHOUT-REPETITION  # Wird vom NVEM im NV-Netz ein Bordnetz-Fehler erkannt, so soll dies zu einer mehrstufigen Anzeige führen.
          signal NVEM_Last_Anf_XIX_NVEM_12_XIX_HCP3_CANFD01: start 14, 2 bit, little-endian, data-type-policy=OVERRIDE, i-signal-type=PRIMITIVE, init-value=0, base-type=BT_NVEM_Last_Anf, compu {3=Cx3_Verbraucher_Anforderung_Stufe_3 (CM_NVEM_Last_Anf_Cx3_Verbraucher_Anforderung_Stufe_3), 1=Cx1_Verbraucher_Anforderung_Stufe_1 (CM_NVEM_Last_Anf_Cx1_Verbraucher_Anforderung_Stufe_1), 0=Cx0_keine_Anforderung (CM_NVEM_Last_Anf_Cx0_keine_Anforderung) (keine Anforderung), 2=Cx2_Verbraucher_Anforderung_Stufe_2 (CM_NVEM_Last_Anf_Cx2_Verbraucher_Anforderung_Stufe_2)}, range raw 0..3, transfer-property=TRIGGERED-WITHOUT-REPETITION  # Das NVEM fordert für die Batteriediagnose einen Lastimpuls vom Fahrzeug an, der durch kontrollierte Verbraucherzuschaltungen (z. B. Aktivierung Heckscheibenheizung) generiert wird
          signal BEM_HL_Regelung_Status_XIX_NVEM_12_XIX_HCP3_CANFD01: start 16, 3 bit, little-endian, data-type-policy=OVERRIDE, i-signal-type=PRIMITIVE, init-value=0, base-type=BT_BEM_HL_Regelung_Status, compu {1=Cx1_HL_Regelung_Stufe_1 (CM_BEM_HL_Regelung_Status_Cx1_HL_Regelung_Stufe_1), 2=Cx2_HL_Regelung_Stufe_2 (CM_BEM_HL_Regelung_Status_Cx2_HL_Regelung_Stufe_2), 7=Cx7_Default (CM_BEM_HL_Regelung_Status_Cx7_Default), 4=Cx4_Verbrauchernotabschaltung_VNA (CM_BEM_HL_Regelung_Status_Cx4_Verbrauchernotabschaltung_VNA) (Verbrauchernotabschaltung_(VNA)), 0=Cx0_HL_Regelung_inaktiv_vor_und_waehrend_Motorstart (CM_BEM_HL_Regelung_Status_Cx0_HL_Regelung_inaktiv_vor_und_waehrend_Motorstart) (HL_Regelung_inaktiv_(vor_und_waehrend_Motorstart)), 3=Cx3_HL_Regelung_Stufe_3 (CM_BEM_HL_Regelung_Status_Cx3_HL_Regelung_Stufe_3), 5=Cx5_HL_Regelung_Stufe_5 (CM_BEM_HL_Regelung_Status_Cx5_HL_Regelung_Stufe_5)}, range raw 0..7, transfer-property=TRIGGERED-WITHOUT-REPETITION  # Status Regelung Heizleistung
          signal NVEM_Abschaltstufe_XIX_NVEM_12_XIX_HCP3_CANFD01: start 19, 2 bit, little-endian, data-type-policy=OVERRIDE, i-signal-type=PRIMITIVE, init-value=0, base-type=BT_NVEM_Abschaltstufe, compu {3=Cx3_Stufe_3 (CM_NVEM_Abschaltstufe_Cx3_Stufe_3), 0=Cx0_Stufe_0_keine_Einschraenkung (CM_NVEM_Abschaltstufe_Cx0_Stufe_0_keine_Einschraenkung), 2=Cx2_Stufe_2 (CM_NVEM_Abschaltstufe_Cx2_Stufe_2), 1=Cx1_Stufe_1 (CM_NVEM_Abschaltstufe_Cx1_Stufe_1)}, range raw 0..3, transfer-property=TRIGGERED-WITHOUT-REPETITION  # Abschaltstufe aus dem Ruheenergiemanagement Maßnahmen des Empfängers werden im QLAH Ruhestrommanagement definiert
          signal NVEM_NV_BAT_ZellStatus_Index_Anf_XIX_NVEM_12_XIX_HCP3_CANFD01: start 21, 4 bit, little-endian, data-type-policy=OVERRIDE, i-signal-type=PRIMITIVE, init-value=0, base-type=BT_NVEM_NV_BAT_ZellStatus_Index_Anf, compu {8=Cx8_Cell_Nr_9 (CM_NVEM_NV_BAT_ZellStatus_Index_Anf_Cx8_Cell_Nr_9), 15=Cxf_Cell_Nr_16 (CM_NVEM_NV_BAT_ZellStatus_Index_Anf_Cxf_Cell_Nr_16), 5=Cx5_Cell_Nr_6 (CM_NVEM_NV_BAT_ZellStatus_Index_Anf_Cx5_Cell_Nr_6), 1=Cx1_Cell_Nr_2 (CM_NVEM_NV_BAT_ZellStatus_Index_Anf_Cx1_Cell_Nr_2), 9=Cx9_Cell_Nr_10 (CM_NVEM_NV_BAT_ZellStatus_Index_Anf_Cx9_Cell_Nr_10), 10=Cxa_Cell_Nr_11 (CM_NVEM_NV_BAT_ZellStatus_Index_Anf_Cxa_Cell_Nr_11), 11=Cxb_Cell_Nr_12 (CM_NVEM_NV_BAT_ZellStatus_Index_Anf_Cxb_Cell_Nr_12), 13=Cxd_Cell_Nr_14 (CM_NVEM_NV_BAT_ZellStatus_Index_Anf_Cxd_Cell_Nr_14), 12=Cxc_Cell_Nr_13 (CM_NVEM_NV_BAT_ZellStatus_Index_Anf_Cxc_Cell_Nr_13), 7=Cx7_Cell_Nr_8 (CM_NVEM_NV_BAT_ZellStatus_Index_Anf_Cx7_Cell_Nr_8), 2=Cx2_Cell_Nr_3 (CM_NVEM_NV_BAT_ZellStatus_Index_Anf_Cx2_Cell_Nr_3), 4=Cx4_Cell_Nr_5 (CM_NVEM_NV_BAT_ZellStatus_Index_Anf_Cx4_Cell_Nr_5), 0=Cx0_Cell_Nr_1 (CM_NVEM_NV_BAT_ZellStatus_Index_Anf_Cx0_Cell_Nr_1), 3=Cx3_Cell_Nr_4 (CM_NVEM_NV_BAT_ZellStatus_Index_Anf_Cx3_Cell_Nr_4), 14=Cxe_Cell_Nr_15 (CM_NVEM_NV_BAT_ZellStatus_Index_Anf_Cxe_Cell_Nr_15), 6=Cx6_Cell_Nr_7 (CM_NVEM_NV_BAT_ZellStatus_Index_Anf_Cx6_Cell_Nr_7)}, range raw 0..15, transfer-property=TRIGGERED-WITHOUT-REPETITION  # Multiplex signal for cell number of low voltage battery.
          signal NVEM_NV_BAT_ZellStatus_Typ_Anf_XIX_NVEM_12_XIX_HCP3_CANFD01: start 25, 3 bit, little-endian, data-type-policy=OVERRIDE, i-signal-type=PRIMITIVE, init-value=0, base-type=BT_NVEM_NV_BAT_ZellStatus_Typ_Anf, compu {0=Cx0_Init (CM_NVEM_NV_BAT_ZellStatus_Typ_Anf_Cx0_Init), 2=Cx2_Temperature (CM_NVEM_NV_BAT_ZellStatus_Typ_Anf_Cx2_Temperature), 6=Cx6_reserved (CM_NVEM_NV_BAT_ZellStatus_Typ_Anf_Cx6_reserved), 5=Cx5_SoH_C (CM_NVEM_NV_BAT_ZellStatus_Typ_Anf_Cx5_SoH_C), 4=Cx4_SoF (CM_NVEM_NV_BAT_ZellStatus_Typ_Anf_Cx4_SoF), 1=Cx1_Voltage (CM_NVEM_NV_BAT_ZellStatus_Typ_Anf_Cx1_Voltage), 3=Cx3_Voltage_limit (CM_NVEM_NV_BAT_ZellStatus_Typ_Anf_Cx3_Voltage_limit) (Voltage limit), 7=Cx7_reserved (CM_NVEM_NV_BAT_ZellStatus_Typ_Anf_Cx7_reserved)}, range raw 0..7, transfer-property=TRIGGERED-WITHOUT-REPETITION  # Multiplex signal for cell status of low voltage battery.
          signal NVEM_Freigabe_OTA_XIX_NVEM_12_XIX_HCP3_CANFD01: start 28, 2 bit, little-endian, data-type-policy=OVERRIDE, i-signal-type=PRIMITIVE, init-value=0, base-type=BT_NVEM_Freigabe_OTA, compu {0=Cx0_Init (CM_NVEM_Freigabe_OTA_Cx0_Init), 1=Cx1_Keine_Freigabe (CM_NVEM_Freigabe_OTA_Cx1_Keine_Freigabe), 2=Cx2_Freigabe (CM_NVEM_Freigabe_OTA_Cx2_Freigabe)}, range raw 0..2, transfer-property=TRIGGERED-WITHOUT-REPETITION  # Bestätigung oder Ablehnung eines konkreten, angefragten Online-Updates durch das Energiemangement
          signal BEM_Generatordiagnose_XIX_NVEM_12_XIX_HCP3_CANFD01: start 30, 2 bit, little-endian, data-type-policy=OVERRIDE, i-signal-type=PRIMITIVE, init-value=0, base-type=BT_BEM_Generatordiagnose, compu {1=Cx1_Ladekontrollanzeige_ein_Vorhalt (CM_BEM_Generatordiagnose_Cx1_Ladekontrollanzeige_ein_Vorhalt) (Ladekontrollanzeige ein (Vorhalt)), 3=Cx3_Hybrid_DCDC_Wandler_defekt (CM_BEM_Generatordiagnose_Cx3_Hybrid_DCDC_Wandler_defekt), 2=Cx2_rotes_Batteriesymbol_und_Text_Generator_defekt (CM_BEM_Generatordiagnose_Cx2_rotes_Batteriesymbol_und_Text_Generator_defekt) (rotes Batteriesymbol und Text (Generator defekt)), 0=Cx0_keine_Anzeige (CM_BEM_Generatordiagnose_Cx0_keine_Anzeige) (keine Anzeige)}, range raw 0..3, transfer-property=TRIGGERED-WITHOUT-REPETITION  # Ansteuerung Generatorwarnleuchte im Kombi
          signal NVEM_DC_uSoll_NV_XIX_NVEM_12_XIX_HCP3_CANFD01: start 32, 8 bit, little-endian, data-type-policy=OVERRIDE, i-signal-type=PRIMITIVE, init-value=116, base-type=BT_NVEM_DC_uSoll_NV, invalid-value=Invalid_NVEM_DC_uSoll_NV_XIX_NVEM_12_XIX_HCP3_CANFD01:255, compu {phys=raw*0.025+10.6 for raw 0..216, 255=Cxff_Fehler (CM_NVEM_DC_uSoll_NV_Cxff_Fehler); unit Unit_Volt}, range phys 10.6..16 Unit_Volt, raw 0..255, unit=Unit_Volt, transfer-property=TRIGGERED-WITHOUT-REPETITION  # Sollspannung 12V Seite des DC Wandlers, feine Auflösung
          signal NVEM_DC_iSoll_NV_XIX_NVEM_12_XIX_HCP3_CANFD01: start 40, 8 bit, little-endian, data-type-policy=OVERRIDE, i-signal-type=PRIMITIVE, init-value=254, base-type=BT_NVEM_DC_iSoll_NV, invalid-value=Invalid_NVEM_DC_iSoll_NV_XIX_NVEM_12_XIX_HCP3_CANFD01:255, compu {phys=raw-253 for raw 0..253, 255=Cxff_Fehler (CM_NVEM_DC_iSoll_NV_Cxff_Fehler), 254=Cxfe_Init (CM_NVEM_DC_iSoll_NV_Cxfe_Init); unit Unit_Amper}, range phys -253..0 Unit_Amper, raw 0..255, unit=Unit_Amper, transfer-property=TRIGGERED-WITHOUT-REPETITION  # Soll-Entladestrom 12V Seite des DCDC Wandlers
          signal BEM_Batt_Ab_XIX_NVEM_12_XIX_HCP3_CANFD01: start 48, 1 bit, little-endian, data-type-policy=OVERRIDE, i-signal-type=PRIMITIVE, init-value=0, base-type=BT_BEM_Batt_Ab, compu {0=Cx0_verbunden (CM_BEM_Batt_Ab_Cx0_verbunden), 1=Cx1_nicht_verbunden (CM_BEM_Batt_Ab_Cx1_nicht_verbunden)}, range raw 0..1, transfer-property=TRIGGERED-WITHOUT-REPETITION  # Batterieverbindungskontrolle: 0x0: Batterie am Bordnetz 0x1: Batterie ab erkannt
          signal BEM_Red_Innengeblaese_XIX_NVEM_12_XIX_HCP3_CANFD01: start 49, 2 bit, little-endian, data-type-policy=OVERRIDE, i-signal-type=PRIMITIVE, init-value=0, base-type=BT_BEM_Red_Innengeblaese, compu {3=Cx3_Reduzierung_Stufe_2_und_Abschaltung_Kompressor (CM_BEM_Red_Innengeblaese_Cx3_Reduzierung_Stufe_2_und_Abschaltung_Kompressor) (Reduzierung Stufe 2 und Abschaltung Kompressor), 1=Cx1_Reduzierung_Stufe_1 (CM_BEM_Red_Innengeblaese_Cx1_Reduzierung_Stufe_1) (Reduzierung Stufe 1), 2=Cx2_Reduzierung_Stufe_2 (CM_BEM_Red_Innengeblaese_Cx2_Reduzierung_Stufe_2) (Reduzierung Stufe 2), 0=Cx0_keine_Reduzierung (CM_BEM_Red_Innengeblaese_Cx0_keine_Reduzierung) (keine Reduzierung)}, range raw 0..3, transfer-property=TRIGGERED-WITHOUT-REPETITION  # Reduzierung Innengebläse
          signal NVEM_MV_DC_uMinLV_XIX_NVEM_12_XIX_HCP3_CANFD01: start 51, 7 bit, little-endian, data-type-policy=OVERRIDE, i-signal-type=PRIMITIVE, init-value=126, base-type=BT_NVEM_MV_DC_uMinLV, invalid-value=Invalid_NVEM_MV_DC_uMinLV_XIX_NVEM_12_XIX_HCP3_CANFD01:127, compu {phys=raw*0.1+3.5 for raw 0..125, 127=Cx7f_Fehler (CM_NVEM_MV_DC_uMinLV_Cx7f_Fehler), 126=Cx7e_Init (CM_NVEM_MV_DC_uMinLV_Cx7e_Init); unit Unit_Volt}, range phys 3.5..16 Unit_Volt, raw 0..127, unit=Unit_Volt, transfer-property=TRIGGERED-WITHOUT-REPETITION  # Abregelgrenze: minimal erlaubte Bordnetzspannung im Hochsetzbetrieb vom 12V-Bordnetz ins 48V-Netz
          signal NVEM_MV_DC_uSollLV_XIX_NVEM_12_XIX_HCP3_CANFD01: start 58, 7 bit, little-endian, data-type-policy=OVERRIDE, i-signal-type=PRIMITIVE, init-value=126, base-type=BT_NVEM_MV_DC_uSollLV, invalid-value=Invalid_NVEM_MV_DC_uSollLV_XIX_NVEM_12_XIX_HCP3_CANFD01:127, compu {phys=raw*0.05+10.6 for raw 0..108, 127=Cx7f_Fehler (CM_NVEM_MV_DC_uSollLV_Cx7f_Fehler), 126=Cx7e_Init (CM_NVEM_MV_DC_uSollLV_Cx7e_Init); unit Unit_Volt}, range phys 10.6..16 Unit_Volt, raw 0..127, unit=Unit_Volt, transfer-property=TRIGGERED-WITHOUT-REPETITION  # Sollwert für die 12V-Bordnetzspannung im Tiefsetzbetrieb vom 48V-Netz ins 12V-Bordnetz
          signal BEM_STH_Einschaltverbot_XIX_NVEM_12_XIX_HCP3_CANFD01: start 65, 1 bit, little-endian, data-type-policy=OVERRIDE, i-signal-type=PRIMITIVE, init-value=0, base-type=BT_BEM_STH_Einschaltverbot, compu {1=Cx1_Standheizung_lueftung_nicht_aktivierbar (CM_BEM_STH_Einschaltverbot_Cx1_Standheizung_lueftung_nicht_aktivierbar) (Standheizung/-lueftung nicht aktivierbar), 0=Cx0_volle_Verfuegbarkeit_Standheizung_lueftung (CM_BEM_STH_Einschaltverbot_Cx0_volle_Verfuegbarkeit_Standheizung_lueftung) (volle Verfuegbarkeit Standheizung/-lueftung)}, range raw 0..1, transfer-property=TRIGGERED-WITHOUT-REPETITION  # Einschränkung Standheizung/-lüftung durch BEM: Setzt der BEM das Bit, dann darf die Standheizung nicht mehr einschalten (Die Standheizung muss aber nicht abschalten, sondern darf weiterbrennen) (Initialisierungswert aus EEprom)
          signal BEM_STH_Zielzeit_XIX_NVEM_12_XIX_HCP3_CANFD01: start 66, 4 bit, little-endian, data-type-policy=OVERRIDE, i-signal-type=PRIMITIVE, init-value=14, base-type=BT_BEM_STH_Zielzeit, invalid-value=Invalid_BEM_STH_Zielzeit_XIX_NVEM_12_XIX_HCP3_CANFD01:15, compu {phys=raw*5 for raw 0..12, 15=Cxf_Fehler (CM_BEM_STH_Zielzeit_Cxf_Fehler), 14=Cxe_Init (CM_BEM_STH_Zielzeit_Cxe_Init); unit Unit_Minut}, range phys 0..60 Unit_Minut, raw 0..15, unit=Unit_Minut, transfer-property=TRIGGERED-WITHOUT-REPETITION  # Maximal mögliche Zeit für den Standheizungsbetrieb, um die Startfähigkeit nicht zu gefährden
          signal NVEM_Verbraucher_Information_XIX_NVEM_12_XIX_HCP3_CANFD01: start 70, 3 bit, little-endian, data-type-policy=OVERRIDE, i-signal-type=PRIMITIVE, init-value=6, base-type=BT_NVEM_Verbraucher_Information, invalid-value=Invalid_NVEM_Verbraucher_Information_XIX_NVEM_12_XIX_HCP3_CANFD01:7, compu {7=Cx7_Fehler (CM_NVEM_Verbraucher_Information_Cx7_Fehler), 0=Cx0_Keine_Anzeige (CM_NVEM_Verbraucher_Information_Cx0_Keine_Anzeige), 1=Cx1_MMI_Vorwarnung (CM_NVEM_Verbraucher_Information_Cx1_MMI_Vorwarnung), 2=Cx2_Anzeige_Verbraucherabschaltung (CM_NVEM_Verbraucher_Information_Cx2_Anzeige_Verbraucherabschaltung), 5=Cx5_reserviert (CM_NVEM_Verbraucher_Information_Cx5_reserviert), 3=Cx3_reserviert (CM_NVEM_Verbraucher_Information_Cx3_reserviert), 4=Cx4_reserviert (CM_NVEM_Verbraucher_Information_Cx4_reserviert), 6=Cx6_Init (CM_NVEM_Verbraucher_Information_Cx6_Init)}, range raw 0..7, transfer-property=TRIGGERED-WITHOUT-REPETITION  # Mit diesem Signal löst Das NVM eine Anzeige bzgl. einer bevorstehenden oder erfolgten Verbraucherabschaltung aus
          signal NVEM3_Absch_SCR_XIX_NVEM_12_XIX_HCP3_CANFD01: start 73, 1 bit, little-endian, data-type-policy=OVERRIDE, i-signal-type=PRIMITIVE, init-value=0, base-type=BT_NVEM3_Absch_SCR, compu {1=Cx1_Abschaltung_SCR (CM_NVEM3_Absch_SCR_Cx1_Abschaltung_SCR), 0=Cx0_Init (CM_NVEM3_Absch_SCR_Cx0_Init)}, range raw 0..1, transfer-property=TRIGGERED-WITHOUT-REPETITION  # Abschaltung der SCR-Heizung durch das NVEM bei energetisch kritischen Zuständen.
          signal NVEM_Bordnetz_Information_XIX_NVEM_12_XIX_HCP3_CANFD01: start 76, 4 bit, little-endian, data-type-policy=OVERRIDE, i-signal-type=PRIMITIVE, init-value=14, base-type=BT_NVEM_Bordnetz_Information, invalid-value=Invalid_NVEM_Bordnetz_Information_XIX_NVEM_12_XIX_HCP3_CANFD01:15, compu {15=Cxf_Fehler (CM_NVEM_Bordnetz_Information_Cxf_Fehler), 1=Cx1_NV_Batterie_iO (CM_NVEM_Bordnetz_Information_Cx1_NV_Batterie_iO), 8=Cx8_Ladekontrollleuchte (CM_NVEM_Bordnetz_Information_Cx8_Ladekontrollleuchte), 0=Cx0_keine_Anzeige (CM_NVEM_Bordnetz_Information_Cx0_keine_Anzeige), 4=Cx4_NV_Batterie_schwach (CM_NVEM_Bordnetz_Information_Cx4_NV_Batterie_schwach), 3=Cx3_NV_Batterie_pruefen (CM_NVEM_Bordnetz_Information_Cx3_NV_Batterie_pruefen), 2=Cx2_NV_Batterie_laden (CM_NVEM_Bordnetz_Information_Cx2_NV_Batterie_laden), 13=Cxd_reserviert (CM_NVEM_Bordnetz_Information_Cxd_reserviert), 7=Cx7_NV_Energiesystem_unplausibel (CM_NVEM_Bordnetz_Information_Cx7_NV_Energiesystem_unplausibel), 14=Cxe_Init (CM_NVEM_Bordnetz_Information_Cxe_Init), 6=Cx6_NV_Batterie_Service (CM_NVEM_Bordnetz_Information_Cx6_NV_Batterie_Service), 5=Cx5_NV_Batterie_Ab (CM_NVEM_Bordnetz_Information_Cx5_NV_Batterie_Ab), 9=Cx9_Generator_defekt (CM_NVEM_Bordnetz_Information_Cx9_Generator_defekt), 10=Cxa_reserviert (CM_NVEM_Bordnetz_Information_Cxa_reserviert), 11=Cxb_reserviert (CM_NVEM_Bordnetz_Information_Cxb_reserviert), 12=Cxc_reserviert (CM_NVEM_Bordnetz_Information_Cxc_reserviert)}, range raw 0..15, transfer-property=TRIGGERED-WITHOUT-REPETITION  # Informationsanzeigen zum 12V - Bordnetz
          signal NVEM_DC_uMin_NV_XIX_NVEM_12_XIX_HCP3_CANFD01: start 80, 8 bit, little-endian, data-type-policy=OVERRIDE, i-signal-type=PRIMITIVE, init-value=122, base-type=BT_NVEM_DC_uMin_NV, compu {phys=raw*0.1 for raw 0..255; unit Unit_Volt}, range phys 0..25.5 Unit_Volt, raw 0..255, unit=Unit_Volt, transfer-property=TRIGGERED-WITHOUT-REPETITION  # Mindestspannung des DCDC Wandlers im Hochsetzbetrieb auf 12V Seite
          signal NVEM_MV_DC_iSoll_NV_XIX_NVEM_12_XIX_HCP3_CANFD01: start 88, 8 bit, little-endian, data-type-policy=OVERRIDE, i-signal-type=PRIMITIVE, init-value=254, base-type=BT_NVEM_MV_DC_iSoll_NV, invalid-value=Invalid_NVEM_MV_DC_iSoll_NV_XIX_NVEM_12_XIX_HCP3_CANFD01:255, compu {phys=raw-253 for raw 0..253, 255=Cxff_Fehler (CM_NVEM_MV_DC_iSoll_NV_Cxff_Fehler), 254=Cxfe_Init (CM_NVEM_MV_DC_iSoll_NV_Cxfe_Init); unit Unit_Amper}, range phys -253..0 Unit_Amper, raw 0..255, unit=Unit_Amper, transfer-property=TRIGGERED-WITHOUT-REPETITION  # Sollstromvorgabe NVEM an MV - DCDC Wandler
      frame OBDC_CCF_Req_FD_XIX_HCP3_CANFD01: id 0x1C440224, from HCP3_IONode, frame-length=64, can-addressing-mode=EXTENDED, can-frame-rx-behavior=CAN-FD, can-frame-tx-behavior=CAN-FD
        n pdu OBDC_CCF_Req_FD_XIX_HCP3_CANFD01: length=64
      frame OBDC_CCF_Resp_FD_XIX_HCP3_CANFD01: id 0x1C460224, to HCP3_IONode, frame-length=64, can-addressing-mode=EXTENDED, can-frame-rx-behavior=CAN-FD, can-frame-tx-behavior=CAN-FD
        n pdu OBDC_CCF_Resp_FD_XIX_HCP3_CANFD01: length=64
      frame OBDC_CID_Req_FD_XIX_HCP3_CANFD01: id 0x1C440222, from HCP3_IONode, frame-length=64, can-addressing-mode=EXTENDED, can-frame-rx-behavior=CAN-FD, can-frame-tx-behavior=CAN-FD
        n pdu OBDC_CID_Req_FD_XIX_HCP3_CANFD01: length=64
      frame OBDC_CID_Resp_FD_XIX_HCP3_CANFD01: id 0x1C460222, to HCP3_IONode, frame-length=64, can-addressing-mode=EXTENDED, can-frame-rx-behavior=CAN-FD, can-frame-tx-behavior=CAN-FD
        n pdu OBDC_CID_Resp_FD_XIX_HCP3_CANFD01: length=64
      frame OBDC_Funktionaler_Req_All_FD_XIX_HCP3_CANFD01: id 0x1C410200, from HCP3_IONode, frame-length=64, can-addressing-mode=EXTENDED, can-frame-rx-behavior=CAN-FD, can-frame-tx-behavior=CAN-FD
        n pdu OBDC_Funktionaler_Req_All_FD_XIX_HCP3_CANFD01: length=64
      frame OBDC_HUD_Req_FD_XIX_HCP3_CANFD01: id 0x1C40021B, from HCP3_IONode, frame-length=64, can-addressing-mode=EXTENDED, can-frame-rx-behavior=CAN-FD, can-frame-tx-behavior=CAN-FD
        n pdu OBDC_HUD_Req_FD_XIX_HCP3_CANFD01: length=64
      frame OBDC_HUD_Resp_FD_XIX_HCP3_CANFD01: id 0x1C42021B, to HCP3_IONode, frame-length=64, can-addressing-mode=EXTENDED, can-frame-rx-behavior=CAN-FD, can-frame-tx-behavior=CAN-FD
        n pdu OBDC_HUD_Resp_FD_XIX_HCP3_CANFD01: length=64
      frame OBDC_PID_Req_FD_XIX_HCP3_CANFD01: id 0x1C440223, from HCP3_IONode, frame-length=64, can-addressing-mode=EXTENDED, can-frame-rx-behavior=CAN-FD, can-frame-tx-behavior=CAN-FD
        n pdu OBDC_PID_Req_FD_XIX_HCP3_CANFD01: length=64
      frame OBDC_PID_Resp_FD_XIX_HCP3_CANFD01: id 0x1C460223, to HCP3_IONode, frame-length=64, can-addressing-mode=EXTENDED, can-frame-rx-behavior=CAN-FD, can-frame-tx-behavior=CAN-FD
        n pdu OBDC_PID_Resp_FD_XIX_HCP3_CANFD01: length=64
      frame OBDC_SSN_LSR_1_Req_FD_XIX_HCP3_CANFD01: id 0x1C407093, from HCP3_IONode, frame-length=64, can-addressing-mode=EXTENDED, can-frame-rx-behavior=CAN-FD, can-frame-tx-behavior=CAN-FD
        n pdu OBDC_SSN_LSR_1_Req_FD_XIX_HCP3_CANFD01: length=64
      frame OBDC_SSN_LSR_1_Resp_FD_XIX_HCP3_CANFD01: id 0x1C427093, to HCP3_IONode, frame-length=64, can-addressing-mode=EXTENDED, can-frame-rx-behavior=CAN-FD, can-frame-tx-behavior=CAN-FD
        n pdu OBDC_SSN_LSR_1_Resp_FD_XIX_HCP3_CANFD01: length=64
      frame OBDC_WLC1_Req_FD_XIX_HCP3_CANFD01: id 0x1C4002A5, from HCP3_IONode, frame-length=64, can-addressing-mode=EXTENDED, can-frame-rx-behavior=CAN-FD, can-frame-tx-behavior=CAN-FD
        n pdu OBDC_WLC1_Req_FD_XIX_HCP3_CANFD01: length=64
      frame OBDC_WLC1_Resp_FD_XIX_HCP3_CANFD01: id 0x1C4202A5, to HCP3_IONode, frame-length=64, can-addressing-mode=EXTENDED, can-frame-rx-behavior=CAN-FD, can-frame-tx-behavior=CAN-FD
        n pdu OBDC_WLC1_Resp_FD_XIX_HCP3_CANFD01: length=64
      frame OBDC_WLC2_Req_FD_XIX_HCP3_CANFD01: id 0x1C4002A6, from HCP3_IONode, frame-length=64, can-addressing-mode=EXTENDED, can-frame-rx-behavior=CAN-FD, can-frame-tx-behavior=CAN-FD
        n pdu OBDC_WLC2_Req_FD_XIX_HCP3_CANFD01: length=64
      frame OBDC_WLC2_Resp_FD_XIX_HCP3_CANFD01: id 0x1C4202A6, to HCP3_IONode, frame-length=64, can-addressing-mode=EXTENDED, can-frame-rx-behavior=CAN-FD, can-frame-tx-behavior=CAN-FD
        n pdu OBDC_WLC2_Resp_FD_XIX_HCP3_CANFD01: length=64
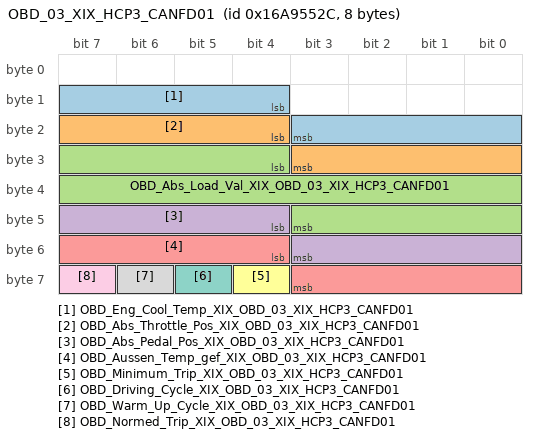
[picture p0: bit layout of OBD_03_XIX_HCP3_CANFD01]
      frame OBD_03_XIX_HCP3_CANFD01: id 0x16A9552C, from HCP3_IONode, frame-length=8, can-addressing-mode=EXTENDED, can-frame-rx-behavior=CAN-FD, can-frame-tx-behavior=CAN-FD
        pdu OBD_03_XIX_HCP3_CANFD01: length=8, transmission-mode-true-timing=cyclic-timing={time-offset=0.0, time-period=0.32}, unused-bit-pattern=0
          signal OBD_Eng_Cool_Temp_XIX_OBD_03_XIX_HCP3_CANFD01: start 12, 8 bit, little-endian, data-type-policy=OVERRIDE, i-signal-type=PRIMITIVE, init-value=255, base-type=BT_OBD_Eng_Cool_Temp, compu {phys=raw-40 for raw 0..255; unit Unit_DegreCelsi}, range phys -40..215 Unit_DegreCelsi, raw 0..255, unit=Unit_DegreCelsi, transfer-property=PENDING  # Engine Coolant Temperature Übertragung von Meßgrößen an das Getriebesteuergerät für Freeze Frame Abspeicherung bei Getriebefehlern PID $05 Engine Coolant Temperature; -40 .. +215°C mit 1°C/bit und 40°C Offset
          signal OBD_Abs_Throttle_Pos_XIX_OBD_03_XIX_HCP3_CANFD01: start 20, 8 bit, little-endian, data-type-policy=OVERRIDE, i-signal-type=PRIMITIVE, init-value=255, base-type=BT_OBD_Abs_Throttle_Pos, compu {phys=raw*0.3921568627 for raw 0..255; unit Unit_PerCent}, range phys 0..100 Unit_PerCent, raw 0..255, unit=Unit_PerCent, transfer-property=PENDING  # Absolute Throttle Position Übertragung von Meßgrößen an das Getriebesteuergerät für Freeze Frame Abspeicherung bei Getriebefehlern PID $11 Absolute Throttle Position; 0 .. 100% mit 100/255 %/bit
          signal OBD_Abs_Load_Val_XIX_OBD_03_XIX_HCP3_CANFD01: start 28, 16 bit, little-endian, data-type-policy=OVERRIDE, i-signal-type=PRIMITIVE, init-value=65535, base-type=BT_OBD_Abs_Load_Val, compu {phys=raw*0.3921568627 for raw 0..65535; unit Unit_PerCent}, range phys 0..25700 Unit_PerCent, raw 0..65535, unit=Unit_PerCent, transfer-property=PENDING  # Absolute Load Value Übertragung von Meßgrößen an das Getriebesteuergerät für Freeze Frame Abspeicherung bei Getriebefehlern PID $43 Absolute Load Value; 0 .. 25700% mit 100/255 %/bit
          signal OBD_Abs_Pedal_Pos_XIX_OBD_03_XIX_HCP3_CANFD01: start 44, 8 bit, little-endian, data-type-policy=OVERRIDE, i-signal-type=PRIMITIVE, init-value=255, base-type=BT_OBD_Abs_Pedal_Pos, compu {phys=raw*0.3921568627 for raw 0..255; unit Unit_PerCent}, range phys 0..100 Unit_PerCent, raw 0..255, unit=Unit_PerCent, transfer-property=PENDING  # Absolute Pedal Position Übertragung von Meßgrößen an das Getriebesteuergerät für Freeze Frame Abspeicherung bei Getriebefehlern PID $49 Accelerator Pedal Position D; 0 .. 100% mit 100/255 %/bit
          signal OBD_Aussen_Temp_gef_XIX_OBD_03_XIX_HCP3_CANFD01: start 52, 8 bit, little-endian, data-type-policy=OVERRIDE, i-signal-type=PRIMITIVE, init-value=254, base-type=BT_OBD_Aussen_Temp_gef, invalid-value=Invalid_OBD_Aussen_Temp_gef_XIX_OBD_03_XIX_HCP3_CANFD01:255, compu {phys=raw-40 for raw 0..253, 255=Cxff_Fehler (CM_OBD_Aussen_Temp_gef_Cxff_Fehler), 254=Cxfe_Initwert (CM_OBD_Aussen_Temp_gef_Cxfe_Initwert); unit Unit_DegreCelsi}, range phys -40..213 Unit_DegreCelsi, raw 0..255, unit=Unit_DegreCelsi, transfer-property=PENDING  # Gefilterte Aussentemperatur vom Motor für OBD Funktionen.
          signal OBD_Minimum_Trip_XIX_OBD_03_XIX_HCP3_CANFD01: start 60, 1 bit, little-endian, data-type-policy=OVERRIDE, i-signal-type=PRIMITIVE, init-value=0, base-type=BT_OBD_Minimum_Trip, compu {0=Cx0_kein_Min_Normed_Trip (CM_OBD_Minimum_Trip_Cx0_kein_Min_Normed_Trip), 1=Cx1_Min_Normed_Trip (CM_OBD_Minimum_Trip_Cx1_Min_Normed_Trip)}, range raw 0..1, transfer-property=PENDING  # Grundlage OBD-Gesetz CCR 1968.2 (d)(4.3) Denominator Specifications Bildung des General Denominator "Normed Trip": 600 sec. (kumulativ) Zeit nach Motorstart 300 sec. (kumulativ) mit Fahrzeuggeschwindigkeit > 25 mph (40 km/h) 30 sec. (kontinuierlich) Leerlauf Wenn alle diese Bedingungen erfüllt wurden ist ein OBD_Min_Normed_Trip erfüllt
          signal OBD_Driving_Cycle_XIX_OBD_03_XIX_HCP3_CANFD01: start 61, 1 bit, little-endian, data-type-policy=OVERRIDE, i-signal-type=PRIMITIVE, init-value=0, base-type=BT_OBD_Driving_Cycle, compu {0=Cx0_kein_Driving_Cycle_erkannt (CM_OBD_Driving_Cycle_Cx0_kein_Driving_Cycle_erkannt), 1=Cx1_Driving_Cycle_erkannt (CM_OBD_Driving_Cycle_Cx1_Driving_Cycle_erkannt)}, range raw 0..1, transfer-property=PENDING  # Signalisierung Driving Cycle Qualifizierung - Trigger Ignition Cycle Counter
          signal OBD_Warm_Up_Cycle_XIX_OBD_03_XIX_HCP3_CANFD01: start 62, 1 bit, little-endian, data-type-policy=OVERRIDE, i-signal-type=PRIMITIVE, init-value=0, base-type=BT_OBD_Warm_Up_Cycle, compu {0=Cx0_kein_Warm_Up_Cycle_erkannt (CM_OBD_Warm_Up_Cycle_Cx0_kein_Warm_Up_Cycle_erkannt), 1=Cx1_Warm_Up_Cycle_erkannt (CM_OBD_Warm_Up_Cycle_Cx1_Warm_Up_Cycle_erkannt)}, range raw 0..1, transfer-property=PENDING  # Mit dem Warm-Up-Cycle wird der zentrale Verlernzähler vom Gateway inkrementiert
          signal OBD_Normed_Trip_XIX_OBD_03_XIX_HCP3_CANFD01: start 63, 1 bit, little-endian, data-type-policy=OVERRIDE, i-signal-type=PRIMITIVE, init-value=0, base-type=BT_OBD_Normed_Trip, compu {1=Cx1_Normed_Trip (CM_OBD_Normed_Trip_Cx1_Normed_Trip), 0=Cx0_kein_Normed_Trip (CM_OBD_Normed_Trip_Cx0_kein_Normed_Trip)}, range raw 0..1, transfer-property=PENDING  # Gesetzlich definierte "Normed Condition" erfüllt, "General Denominator" darf erhöht werden
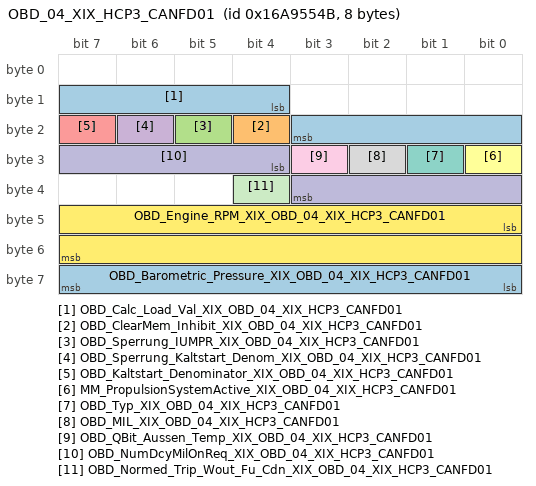
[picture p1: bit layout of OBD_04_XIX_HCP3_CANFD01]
      frame OBD_04_XIX_HCP3_CANFD01: id 0x16A9554B, from HCP3_IONode, frame-length=8, can-addressing-mode=EXTENDED, can-frame-rx-behavior=CAN-FD, can-frame-tx-behavior=CAN-FD
        pdu OBD_04_XIX_HCP3_CANFD01: length=8, minimum-delay=0.08, transmission-mode-true-timing={cyclic-timing={time-offset=0.0, time-period=0.32}, event-controlled-timing={number-of-repetitions=0, repetition-period=0.0}}, unused-bit-pattern=0
          signal OBD_Calc_Load_Val_XIX_OBD_04_XIX_HCP3_CANFD01: start 12, 8 bit, little-endian, data-type-policy=OVERRIDE, i-signal-type=PRIMITIVE, init-value=255, base-type=BT_OBD_Calc_Load_Val, compu {phys=raw*0.3921568627 for raw 0..255; unit Unit_PerCent}, range phys 0..100 Unit_PerCent, raw 0..255, unit=Unit_PerCent, transfer-property=PENDING  # Calculated Load Value Übertragung von Meßgrößen an das Getriebesteuergerät für Freeze Frame Abspeicherung bei Getriebefehlern PID $04 Calculated Load Value; 0 .. 100% mit 100/255 % per bit
          signal OBD_ClearMem_Inhibit_XIX_OBD_04_XIX_HCP3_CANFD01: start 20, 1 bit, little-endian, data-type-policy=OVERRIDE, i-signal-type=PRIMITIVE, init-value=0, base-type=BT_OBD_ClearMem_Inhibit, compu {1=Cx1_FSP_Loeschen_nicht_zulaessig (CM_OBD_ClearMem_Inhibit_Cx1_FSP_Loeschen_nicht_zulaessig), 0=Cx0_FSP_Loeschen_zulaessig (CM_OBD_ClearMem_Inhibit_Cx0_FSP_Loeschen_zulaessig)}, range raw 0..1, transfer-property=PENDING  # Bei FSP_Loeschen_zulässig müssen alle OBD-ECUs im Gesamtfahrzeug einen Service 04hex Request (Ereignisspeicher löschen) korrekt ausführen. In MLB-, MLBevo-, MQB-Fahrzeugkonzepten muss der MIL-Master/Motorsteuergerät bei Kl.15 ein, projektabhängig, konstant OBD_ClearMem_Inhibit = 0 senden, sofern das Löschen des Ereignisspeichers noch in jedem Betriebszustand (auch bei laufendem Motor, etc.) gefordert ist. Projektspezifisch im MLB-, MLBevo-, und MQB-Fahrzeugkonzepten und vollumfänglich in MQB_37W- und MLB3-Fahrzeugkonzepten wird das Ereignisspeicher löschen in allen OBD-ECUs auf den Betriebszustand stehendes Fahrzeug und stehender Motor beschränkt und die entsprechende Freigabe das Ereignisspeicher Löschens vom MIL-Master über das Bussignal OBD_ClearMem_Inhibit für alle anderen OBD-ECUs im Gesamtfahrzeug signalisiert. Hinweis: Steuergerät- oder Komponentenspezifische Randbedingungen sind unter Abhängigkeit des Sicherheitskonzepts zu prüfen und zu bewerten.
          signal OBD_Sperrung_IUMPR_XIX_OBD_04_XIX_HCP3_CANFD01: start 21, 1 bit, little-endian, data-type-policy=OVERRIDE, i-signal-type=PRIMITIVE, init-value=0, base-type=BT_OBD_Sperrung_IUMPR, compu {0=Cx0_IUMPR_Berechnung_freigegeben (CM_OBD_Sperrung_IUMPR_Cx0_IUMPR_Berechnung_freigegeben), 1=Cx1_IUMPR_Berechnung_gesperrt (CM_OBD_Sperrung_IUMPR_Cx1_IUMPR_Berechnung_gesperrt)}, range raw 0..1, transfer-property=PENDING  # Wenn der General Denominator auf Grund eines Fehlers in den Eingangsgrößen gesperrt wird, wird diese Information über Bussystem als OBD-Statusinformation OBD_Sperrung_IUMPR für andere OBD-Steuergeräte bereitgestellt. Das MSG (MIL-Master) setzt dieses Bit, wenn auf Grund vorliegender Sperrbedingungen keine Inkrementierung des GeneralDenominator mehr stattfindet. Im Empfänger-SG ist entsprechend die Inkrementierung des oder der Numeratoren einzufrieren.
          signal OBD_Sperrung_Kaltstart_Denom_XIX_OBD_04_XIX_HCP3_CANFD01: start 22, 1 bit, little-endian, data-type-policy=OVERRIDE, i-signal-type=PRIMITIVE, init-value=0, base-type=BT_OBD_Sperrung_Kaltstart_Denom, compu {1=Cx1_EVAP_Berechnung_gesperrt (CM_OBD_Sperrung_Kaltstart_Denom_Cx1_EVAP_Berechnung_gesperrt), 0=Cx0_EVAP_Berechnung_freigegeben (CM_OBD_Sperrung_Kaltstart_Denom_Cx0_EVAP_Berechnung_freigegeben)}, range raw 0..1, transfer-property=PENDING  # Information vom MIL Master, dass die Bildung des EVAP Denominators im Motor nicht möglich ist und damit der noECM-Denominator gesperrt werden darf.
          signal OBD_Kaltstart_Denominator_XIX_OBD_04_XIX_HCP3_CANFD01: start 23, 1 bit, little-endian, data-type-policy=OVERRIDE, i-signal-type=PRIMITIVE, init-value=0, base-type=BT_OBD_Kaltstart_Denominator, compu {0=Cx0_Denominator_nicht_hochzaehlen (CM_OBD_Kaltstart_Denominator_Cx0_Denominator_nicht_hochzaehlen), 1=Cx1_Bedingungen_zum_Inkr_des_Kaltstart_Denom_erf (CM_OBD_Kaltstart_Denominator_Cx1_Bedingungen_zum_Inkr_des_Kaltstart_Denom_erf)}, range raw 0..1, transfer-property=PENDING  # Bestimmte Diagnosen werden nur unter Kaltstartbedingungen durchgeführt, der entsprechende Denominator bei IUMPR-pflichtigen Systemen wird anhand dieses vom MSG gebildeten Signals inkrementiert. (Entspricht EVAP-Denominator)
          signal MM_PropulsionSystemActive_XIX_OBD_04_XIX_HCP3_CANFD01: start 24, 1 bit, little-endian, data-type-policy=OVERRIDE, i-signal-type=PRIMITIVE, init-value=0, base-type=BT_MM_PropulsionSystemActive, compu {1=Cx1_PropulsionSystemActive (CM_MM_PropulsionSystemActive_Cx1_PropulsionSystemActive), 0=Cx0_PropulsionSystemNotActive (CM_MM_PropulsionSystemActive_Cx0_PropulsionSystemNotActive)}, range raw 0..1, transfer-property=TRIGGERED-ON-CHANGE-WITHOUT-REPETITION  # Fahrzeug ist fahrbereit
          signal OBD_Typ_XIX_OBD_04_XIX_HCP3_CANFD01: start 25, 1 bit, little-endian, data-type-policy=OVERRIDE, i-signal-type=PRIMITIVE, init-value=0, base-type=BT_OBD_Typ, compu {1=Cx1_FullOBD (CM_OBD_Typ_Cx1_FullOBD), 0=Cx0_OBDReady (CM_OBD_Typ_Cx0_OBDReady)}, range raw 0..1, transfer-property=PENDING  # Abgastyp OBD Hinweis: In Fahrzeugen mit dem Zielmarkt China und einer Zertifizierung ab China 6 muss auf dem Signal "OBD_Typ" der Wert "US_OBD" gesendet werden."
          signal OBD_MIL_XIX_OBD_04_XIX_HCP3_CANFD01: start 26, 1 bit, little-endian, data-type-policy=OVERRIDE, i-signal-type=PRIMITIVE, init-value=0, base-type=BT_OBD_MIL, invalid-value=Invalid_OBD_MIL_XIX_OBD_04_XIX_HCP3_CANFD01:1, compu {1=Cx1_Fehler (CM_OBD_MIL_Cx1_Fehler), 0=Cx0_Lampe_aus (CM_OBD_MIL_Cx0_Lampe_aus)}, range raw 0..1, transfer-property=TRIGGERED-ON-CHANGE-WITHOUT-REPETITION  # Ansteuerung der MIL
          signal OBD_QBit_Aussen_Temp_XIX_OBD_04_XIX_HCP3_CANFD01: start 27, 1 bit, little-endian, data-type-policy=OVERRIDE, i-signal-type=PRIMITIVE, init-value=1, base-type=BT_OBD_QBit_Aussen_Temp, compu {0=Cx0_gueltiger_Wert (CM_OBD_QBit_Aussen_Temp_Cx0_gueltiger_Wert), 1=Cx1_Ersatz_Init_oder_Fehlerwert (CM_OBD_QBit_Aussen_Temp_Cx1_Ersatz_Init_oder_Fehlerwert)}, range raw 0..1, transfer-property=TRIGGERED-ON-CHANGE-WITHOUT-REPETITION  # QBit der Aussentemperatur. Gesetzt bei Ersatzwert, Init oder Fehler.
          signal OBD_NumDcyMilOnReq_XIX_OBD_04_XIX_HCP3_CANFD01: start 28, 8 bit, little-endian, data-type-policy=OVERRIDE, i-signal-type=PRIMITIVE, init-value=0, base-type=BT_OBD_NumDcyMilOnReq, compu {phys=raw for raw 0..255; unit Unit_None}, range phys 0..255 Unit_None, raw 0..255, unit=Unit_None, transfer-property=PENDING  # Anzahl der DrivingCycle für MIL-Entprellung von MIL-Master
          signal OBD_Normed_Trip_Wout_Fu_Cdn_XIX_OBD_04_XIX_HCP3_CANFD01: start 36, 1 bit, little-endian, data-type-policy=OVERRIDE, i-signal-type=PRIMITIVE, init-value=0, base-type=BT_OBD_Normed_Trip_Wout_Fu_Cdn, compu {1=Cx1_Normed_Trip_wo_Fu_Cdn (CM_OBD_Normed_Trip_Wout_Fu_Cdn_Cx1_Normed_Trip_wo_Fu_Cdn), 0=Cx0_kein_Normed_Trip_wo_Fu_Cdn (CM_OBD_Normed_Trip_Wout_Fu_Cdn_Cx0_kein_Normed_Trip_wo_Fu_Cdn)}, range raw 0..1, transfer-property=PENDING  # Bedingung für General Denominator-Inkrementierung ohne FueledEngine-Operation -> wird für die Berechnung des General Denominators in der Motorsteuerung (ScanTool-Ausgabe Mode$09, InfoType$08, OBDCOND) benötigt
          signal OBD_Engine_RPM_XIX_OBD_04_XIX_HCP3_CANFD01: start 40, 16 bit, little-endian, data-type-policy=OVERRIDE, i-signal-type=PRIMITIVE, init-value=0, base-type=BT_OBD_Engine_RPM, compu {phys=raw*0.25 for raw 0..65535; unit Unit_MinutInver}, range phys 0..16383.75 Unit_MinutInver, raw 0..65535, unit=Unit_MinutInver, transfer-property=PENDING  # Motordrehzahl des Verbrennungsmotors für OBD freeze frame
          signal OBD_Barometric_Pressure_XIX_OBD_04_XIX_HCP3_CANFD01: start 56, 8 bit, little-endian, data-type-policy=OVERRIDE, i-signal-type=PRIMITIVE, init-value=0, base-type=BT_OBD_Barometric_Pressure, compu {phys=raw for raw 0..255; unit Unit_KiloPascal}, range phys 0..255 Unit_KiloPascal, raw 0..255, unit=Unit_KiloPascal, transfer-property=PENDING  # Umgebungsdruck für OBD freeze frame
      frame ORU_01_XIX_HCP3_CANFD01: id 0x1A555548, from HCP3_IONode, frame-length=8, can-addressing-mode=EXTENDED, can-frame-rx-behavior=CAN-FD, can-frame-tx-behavior=CAN-FD
        pdu ORU_01_XIX_HCP3_CANFD01: length=8, transmission-mode-true-timing=cyclic-timing={time-offset=0.0, time-period=0.5}, unused-bit-pattern=0
          signal ORU_AgLgtSdsl_XIX_ORU_01_XIX_HCP3_CANFD01: start 12, 11 bit, little-endian, data-type-policy=OVERRIDE, i-signal-type=PRIMITIVE, init-value=2001, base-type=BT_ORU_AgLgtSdsl, invalid-value=Invalid_ORU_AgLgtSdsl_XIX_ORU_01_XIX_HCP3_CANFD01:2002, compu {phys=raw*0.1-100 for raw 0..2000, 2002=Cx7d2_Fehler (CM_ORU_AgLgtSdsl_Cx7d2_Fehler), 2001=Cx7d1_InitWert (CM_ORU_AgLgtSdsl_Cx7d1_InitWert); unit Unit_PerCent}, range phys -100..100 Unit_PerCent, raw 0..2002, unit=Unit_PerCent, transfer-property=PENDING  # Vehicle inclination angle at standstill in percent
          signal ORU_Status_XIX_ORU_01_XIX_HCP3_CANFD01: start 61, 3 bit, little-endian, data-type-policy=OVERRIDE, i-signal-type=PRIMITIVE, init-value=0, base-type=BT_ORU_Status, compu {6=Cx6_PENDING_NOTREADY (CM_ORU_Status_Cx6_PENDING_NOTREADY), 1=Cx1_PENDING (CM_ORU_Status_Cx1_PENDING), 5=Cx5_RUNNING_HV (CM_ORU_Status_Cx5_RUNNING_HV), 2=Cx2_PREPARATION (CM_ORU_Status_Cx2_PREPARATION), 7=Cx7_FAILURE_POWERTRAIN_DISABLED (CM_ORU_Status_Cx7_FAILURE_POWERTRAIN_DISABLED), 0=Cx0_IDLE (CM_ORU_Status_Cx0_IDLE), 4=Cx4_RUNNING (CM_ORU_Status_Cx4_RUNNING), 3=Cx3_PREPARATION_HV (CM_ORU_Status_Cx3_PREPARATION_HV)}, range raw 0..7, transfer-property=PENDING  # Verteilung des internen ORU Zustandes
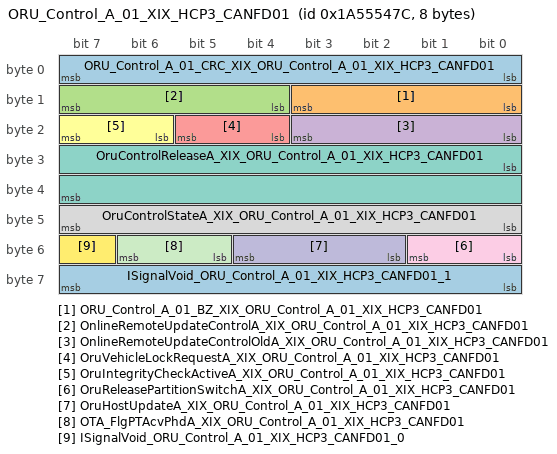
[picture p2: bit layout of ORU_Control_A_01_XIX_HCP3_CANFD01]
      frame ORU_Control_A_01_XIX_HCP3_CANFD01: id 0x1A55547C, from HCP3_IONode, frame-length=8, can-addressing-mode=EXTENDED, can-frame-rx-behavior=CAN-FD, can-frame-tx-behavior=CAN-FD
        pdu ORU_Control_A_01_XIX_HCP3_CANFD01: length=8, transmission-mode-true-timing=cyclic-timing={time-offset=0.0, time-period=0.5}, unused-bit-pattern=0
          signal ORU_Control_A_01_CRC_XIX_ORU_Control_A_01_XIX_HCP3_CANFD01: start 0, 8 bit, little-endian, data-type-policy=OVERRIDE, i-signal-type=PRIMITIVE, init-value=0, base-type=BT_ORU_Control_A_01_CRC, compu {phys=raw for raw 0..255}, range phys 0..255, raw 0..255, transfer-property=TRIGGERED-ON-CHANGE
          signal ORU_Control_A_01_BZ_XIX_ORU_Control_A_01_XIX_HCP3_CANFD01: start 8, 4 bit, little-endian, data-type-policy=OVERRIDE, i-signal-type=PRIMITIVE, init-value=0, base-type=BT_ORU_Control_A_01_BZ, compu {phys=raw for raw 0..15}, range phys 0..15, raw 0..15, transfer-property=TRIGGERED-ON-CHANGE
          signal OnlineRemoteUpdateControlA_XIX_ORU_Control_A_01_XIX_HCP3_CANFD01: start 12, 4 bit, little-endian, data-type-policy=OVERRIDE, i-signal-type=PRIMITIVE, init-value=0, base-type=BT_OnlineRemoteUpdateControlA, invalid-value=Invalid_OnlineRemoteUpdateControlA_XIX_ORU_Control_A_01_XIX_HCP3_CANFD01:15, compu {15=Cxf_Fehler (CM_OnlineRemoteUpdateControlA_Cxf_Fehler), 8=Cx8_FUNCTIONAL_SAFETY_RELEASED (CM_OnlineRemoteUpdateControlA_Cx8_FUNCTIONAL_SAFETY_RELEASED), 5=Cx5_RUNNING_HV (CM_OnlineRemoteUpdateControlA_Cx5_RUNNING_HV), 9=Cx9_PREPARATION_SG (CM_OnlineRemoteUpdateControlA_Cx9_PREPARATION_SG), 0=Cx0_IDLE (CM_OnlineRemoteUpdateControlA_Cx0_IDLE), 7=Cx7_OTA_FAILURE_POWERTRAIN_DISABLED (CM_OnlineRemoteUpdateControlA_Cx7_OTA_FAILURE_POWERTRAIN_DISABLED), 3=Cx3_PREPARATION_HV (CM_OnlineRemoteUpdateControlA_Cx3_PREPARATION_HV), 2=Cx2_PREPARATION (CM_OnlineRemoteUpdateControlA_Cx2_PREPARATION), 4=Cx4_RUNNING (CM_OnlineRemoteUpdateControlA_Cx4_RUNNING), 1=Cx1_PENDING (CM_OnlineRemoteUpdateControlA_Cx1_PENDING), 6=Cx6_PENDING_NOTREADY (CM_OnlineRemoteUpdateControlA_Cx6_PENDING_NOTREADY)}, range raw 0..15, transfer-property=TRIGGERED-ON-CHANGE  # Current state of the oru control component
          signal OnlineRemoteUpdateControlOldA_XIX_ORU_Control_A_01_XIX_HCP3_CANFD01: start 16, 4 bit, little-endian, data-type-policy=OVERRIDE, i-signal-type=PRIMITIVE, init-value=0, base-type=BT_OnlineRemoteUpdateControlOldA, invalid-value=Invalid_OnlineRemoteUpdateControlOldA_XIX_ORU_Control_A_01_XIX_HCP3_CANFD01:15, compu {15=Cxf_Fehler (CM_OnlineRemoteUpdateControlOldA_Cxf_Fehler), 3=Cx3_PREPARATION_HV (CM_OnlineRemoteUpdateControlOldA_Cx3_PREPARATION_HV), 6=Cx6_PENDING_NOTREADY (CM_OnlineRemoteUpdateControlOldA_Cx6_PENDING_NOTREADY), 9=Cx9_PREPARATION_SG (CM_OnlineRemoteUpdateControlOldA_Cx9_PREPARATION_SG), 4=Cx4_RUNNING (CM_OnlineRemoteUpdateControlOldA_Cx4_RUNNING), 2=Cx2_PREPARATION (CM_OnlineRemoteUpdateControlOldA_Cx2_PREPARATION), 5=Cx5_RUNNING_HV (CM_OnlineRemoteUpdateControlOldA_Cx5_RUNNING_HV), 1=Cx1_PENDING (CM_OnlineRemoteUpdateControlOldA_Cx1_PENDING), 0=Cx0_IDLE (CM_OnlineRemoteUpdateControlOldA_Cx0_IDLE), 8=Cx8_FUNCTIONAL_SAFETY_RELEASE (CM_OnlineRemoteUpdateControlOldA_Cx8_FUNCTIONAL_SAFETY_RELEASE), 7=Cx7_OTA_FAILURE_POWERTRAIN_DISABLED (CM_OnlineRemoteUpdateControlOldA_Cx7_OTA_FAILURE_POWERTRAIN_DISABLED)}, range raw 0..15, transfer-property=TRIGGERED-ON-CHANGE  # Old state of the ORU control A signal (state 5 cycles before)
          signal OruVehicleLockRequestA_XIX_ORU_Control_A_01_XIX_HCP3_CANFD01: start 20, 2 bit, little-endian, data-type-policy=OVERRIDE, i-signal-type=PRIMITIVE, init-value=0, base-type=BT_OruVehicleLockRequestA, invalid-value=Invalid_OruVehicleLockRequestA_XIX_ORU_Control_A_01_XIX_HCP3_CANFD01:3, compu {3=Cx3_Fehler (CM_OruVehicleLockRequestA_Cx3_Fehler), 2=Cx2_Release (CM_OruVehicleLockRequestA_Cx2_Release), 1=Cx1_Lock (CM_OruVehicleLockRequestA_Cx1_Lock), 0=Cx0_Init (CM_OruVehicleLockRequestA_Cx0_Init)}, range raw 0..3, transfer-property=TRIGGERED-ON-CHANGE  # Releases or locks one or more ECUs with their specific functions (e.g. immobilizer)
          signal OruIntegrityCheckActiveA_XIX_ORU_Control_A_01_XIX_HCP3_CANFD01: start 22, 2 bit, little-endian, data-type-policy=OVERRIDE, i-signal-type=PRIMITIVE, init-value=0, base-type=BT_OruIntegrityCheckActiveA, invalid-value=Invalid_OruIntegrityCheckActiveA_XIX_ORU_Control_A_01_XIX_HCP3_CANFD01:3, compu {3=Cx3_Fehler (CM_OruIntegrityCheckActiveA_Cx3_Fehler), 1=Cx1_Inactive (CM_OruIntegrityCheckActiveA_Cx1_Inactive), 2=Cx2_Active (CM_OruIntegrityCheckActiveA_Cx2_Active), 0=Cx0_Init (CM_OruIntegrityCheckActiveA_Cx0_Init)}, range raw 0..3, transfer-property=TRIGGERED-ON-CHANGE  # Signal to indicate if the integrity check is active
          signal OruControlReleaseA_XIX_ORU_Control_A_01_XIX_HCP3_CANFD01: start 24, 16 bit, little-endian, data-type-policy=OVERRIDE, i-signal-type=PRIMITIVE, init-value=0, base-type=BT_OruControlReleaseA, compu {phys=raw for raw 0..65535; unit Unit_None}, range phys 0..65535 Unit_None, raw 0..65535, unit=Unit_None, transfer-property=TRIGGERED-ON-CHANGE  # Release of an ecu to be flashed by oru
          signal OruControlStateA_XIX_ORU_Control_A_01_XIX_HCP3_CANFD01: start 40, 8 bit, little-endian, data-type-policy=OVERRIDE, i-signal-type=PRIMITIVE, init-value=0, base-type=BT_OruControlStateA, invalid-value=Invalid_OruControlStateA_XIX_ORU_Control_A_01_XIX_HCP3_CANFD01:129, compu {129=Cx81_Fehler (CM_OruControlStateA_Cx81_Fehler), 63=Cx3f_Done (CM_OruControlStateA_Cx3f_Done), 15=Cxf_Running (CM_OruControlStateA_Cxf_Running), 0=Cx0_Idle (CM_OruControlStateA_Cx0_Idle), 1=Cx1_Check (CM_OruControlStateA_Cx1_Check), 3=Cx3_DataPresent (CM_OruControlStateA_Cx3_DataPresent), 31=Cx1f_Save (CM_OruControlStateA_Cx1f_Save), 65=Cx41_Fail (CM_OruControlStateA_Cx41_Fail), 7=Cx7_LockActive (CM_OruControlStateA_Cx7_LockActive)}, range raw 0..129, transfer-property=TRIGGERED-ON-CHANGE  # Internal State of ORU Control component.
          signal OruReleasePartitionSwitchA_XIX_ORU_Control_A_01_XIX_HCP3_CANFD01: start 48, 2 bit, little-endian, data-type-policy=OVERRIDE, i-signal-type=PRIMITIVE, init-value=0, base-type=BT_OruReleasePartitionSwitchA, invalid-value=Invalid_OruReleasePartitionSwitchA_XIX_ORU_Control_A_01_XIX_HCP3_CANFD01:3, compu {3=Cx3_Fehler (CM_OruReleasePartitionSwitchA_Cx3_Fehler), 1=Cx1_Lock (CM_OruReleasePartitionSwitchA_Cx1_Lock), 0=Cx0_Init (CM_OruReleasePartitionSwitchA_Cx0_Init), 2=Cx2_Release (CM_OruReleasePartitionSwitchA_Cx2_Release)}, range raw 0..3, transfer-property=TRIGGERED-ON-CHANGE  # Release to switch the partition in case of an A/B partition update
          signal OruHostUpdateA_XIX_ORU_Control_A_01_XIX_HCP3_CANFD01: start 50, 3 bit, little-endian, data-type-policy=OVERRIDE, i-signal-type=PRIMITIVE, init-value=0, base-type=BT_OruHostUpdateA, invalid-value=Invalid_OruHostUpdateA_XIX_ORU_Control_A_01_XIX_HCP3_CANFD01:4, compu {4=Cx4_Fehler (CM_OruHostUpdateA_Cx4_Fehler), 0=Cx0_Init (CM_OruHostUpdateA_Cx0_Init), 3=Cx3_HostControlOther (CM_OruHostUpdateA_Cx3_HostControlOther), 2=Cx2_HostControl2 (CM_OruHostUpdateA_Cx2_HostControl2), 1=Cx1_HostControl1 (CM_OruHostUpdateA_Cx1_HostControl1)}, range raw 0..4, transfer-property=TRIGGERED-ON-CHANGE  # Releases an update of an critical funcion's host (due to functional safety)
          signal OTA_FlgPTAcvPhdA_XIX_ORU_Control_A_01_XIX_HCP3_CANFD01: start 53, 2 bit, little-endian, data-type-policy=OVERRIDE, i-signal-type=PRIMITIVE, init-value=0, base-type=BT_OTA_FlgPTAcvPhdA, invalid-value=Invalid_OTA_FlgPTAcvPhdA_XIX_ORU_Control_A_01_XIX_HCP3_CANFD01:3, compu {3=Cx3_Fehler (CM_OTA_FlgPTAcvPhdA_Cx3_Fehler), 2=Cx2_Release (CM_OTA_FlgPTAcvPhdA_Cx2_Release), 1=Cx1_Lock (CM_OTA_FlgPTAcvPhdA_Cx1_Lock), 0=Cx0_Init (CM_OTA_FlgPTAcvPhdA_Cx0_Init)}, range raw 0..3, transfer-property=TRIGGERED-ON-CHANGE  # Signal to reqest a locking of the powertrain that is used in case of an failed update to prevent the customer from driving with a potentially unsafe car.
          mapping SG_ORU_Control_A_01_XIX_HCP3_CANFD01: i-signal-group=SG_ORU_Control_A_01_XIX_HCP3_CANFD01, transfer-property=TRIGGERED-ON-CHANGE
          signal ISignalVoid_ORU_Control_A_01_XIX_HCP3_CANFD01_0: start 55, 1 bit, little-endian, system signal SignalVoid_ORU_Control_A_01_0, data-type-policy=OVERRIDE, i-signal-type=PRIMITIVE, base-type=BT_SignalVoid, transfer-property=PENDING
          signal ISignalVoid_ORU_Control_A_01_XIX_HCP3_CANFD01_1: start 56, 8 bit, little-endian, system signal SignalVoid_ORU_Control_A_01_1, data-type-policy=OVERRIDE, i-signal-type=PRIMITIVE, base-type=BT_SignalVoid, transfer-property=PENDING
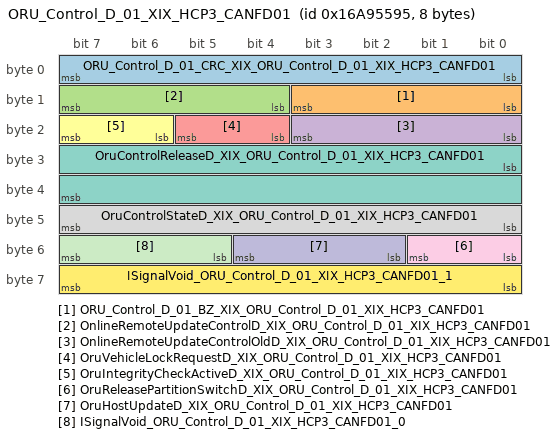
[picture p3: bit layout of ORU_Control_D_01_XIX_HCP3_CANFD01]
      frame ORU_Control_D_01_XIX_HCP3_CANFD01: id 0x16A95595, from HCP3_IONode, frame-length=8, can-addressing-mode=EXTENDED, can-frame-rx-behavior=CAN-FD, can-frame-tx-behavior=CAN-FD
        pdu ORU_Control_D_01_XIX_HCP3_CANFD01: length=8, transmission-mode-true-timing=cyclic-timing={time-offset=0.0, time-period=0.32}, unused-bit-pattern=0
          signal ORU_Control_D_01_CRC_XIX_ORU_Control_D_01_XIX_HCP3_CANFD01: start 0, 8 bit, little-endian, data-type-policy=OVERRIDE, i-signal-type=PRIMITIVE, init-value=0, base-type=BT_ORU_Control_D_01_CRC, compu {phys=raw for raw 0..255}, range phys 0..255, raw 0..255, transfer-property=TRIGGERED-ON-CHANGE
          signal ORU_Control_D_01_BZ_XIX_ORU_Control_D_01_XIX_HCP3_CANFD01: start 8, 4 bit, little-endian, data-type-policy=OVERRIDE, i-signal-type=PRIMITIVE, init-value=0, base-type=BT_ORU_Control_D_01_BZ, compu {phys=raw for raw 0..15}, range phys 0..15, raw 0..15, transfer-property=TRIGGERED-ON-CHANGE
          signal OnlineRemoteUpdateControlD_XIX_ORU_Control_D_01_XIX_HCP3_CANFD01: start 12, 4 bit, little-endian, data-type-policy=OVERRIDE, i-signal-type=PRIMITIVE, init-value=0, base-type=BT_OnlineRemoteUpdateControlD, invalid-value=Invalid_OnlineRemoteUpdateControlD_XIX_ORU_Control_D_01_XIX_HCP3_CANFD01:15, compu {15=Cxf_Fehler (CM_OnlineRemoteUpdateControlD_Cxf_Fehler), 8=Cx8_FUNCTIONAL_SAFETY_RELEASE (CM_OnlineRemoteUpdateControlD_Cx8_FUNCTIONAL_SAFETY_RELEASE), 5=Cx5_RUNNING_HV (CM_OnlineRemoteUpdateControlD_Cx5_RUNNING_HV), 4=Cx4_RUNNING (CM_OnlineRemoteUpdateControlD_Cx4_RUNNING), 0=Cx0_IDLE (CM_OnlineRemoteUpdateControlD_Cx0_IDLE), 2=Cx2_PREPARATION (CM_OnlineRemoteUpdateControlD_Cx2_PREPARATION), 3=Cx3_PREPARATION_HV (CM_OnlineRemoteUpdateControlD_Cx3_PREPARATION_HV), 6=Cx6_PENDING_NOTREADY (CM_OnlineRemoteUpdateControlD_Cx6_PENDING_NOTREADY), 1=Cx1_PENDING (CM_OnlineRemoteUpdateControlD_Cx1_PENDING), 9=Cx9_PREPARATION_SG (CM_OnlineRemoteUpdateControlD_Cx9_PREPARATION_SG), 7=Cx7_OTA_FAILURE_POWERTRAIN_DISABLED (CM_OnlineRemoteUpdateControlD_Cx7_OTA_FAILURE_POWERTRAIN_DISABLED)}, range raw 0..15, transfer-property=TRIGGERED-ON-CHANGE  # This signal is part of the ORU functional safety concept to inform ECUs, if an update is possible
          signal OnlineRemoteUpdateControlOldD_XIX_ORU_Control_D_01_XIX_HCP3_CANFD01: start 16, 4 bit, little-endian, data-type-policy=OVERRIDE, i-signal-type=PRIMITIVE, init-value=0, base-type=BT_OnlineRemoteUpdateControlOldD, invalid-value=Invalid_OnlineRemoteUpdateControlOldD_XIX_ORU_Control_D_01_XIX_HCP3_CANFD01:15, compu {15=Cxf_Fehler (CM_OnlineRemoteUpdateControlOldD_Cxf_Fehler), 8=Cx8_FUNCTIONAL_SAFETY_RELEASE (CM_OnlineRemoteUpdateControlOldD_Cx8_FUNCTIONAL_SAFETY_RELEASE), 3=Cx3_PREPARATION_HV (CM_OnlineRemoteUpdateControlOldD_Cx3_PREPARATION_HV), 7=Cx7_OTA_FAILURE_POWERTRAIN_DISABLED (CM_OnlineRemoteUpdateControlOldD_Cx7_OTA_FAILURE_POWERTRAIN_DISABLED), 4=Cx4_RUNNING (CM_OnlineRemoteUpdateControlOldD_Cx4_RUNNING), 6=Cx6_PENDING_NOTREADY (CM_OnlineRemoteUpdateControlOldD_Cx6_PENDING_NOTREADY), 2=Cx2_PREPARATION (CM_OnlineRemoteUpdateControlOldD_Cx2_PREPARATION), 1=Cx1_PENDING (CM_OnlineRemoteUpdateControlOldD_Cx1_PENDING), 5=Cx5_RUNNING_HV (CM_OnlineRemoteUpdateControlOldD_Cx5_RUNNING_HV), 0=Cx0_IDLE (CM_OnlineRemoteUpdateControlOldD_Cx0_IDLE), 9=Cx9_PREPARATION_SG (CM_OnlineRemoteUpdateControlOldD_Cx9_PREPARATION_SG)}, range raw 0..15, transfer-property=TRIGGERED-ON-CHANGE  # Old state of the ORU control C component (state as of 5 previous cycles)
          signal OruVehicleLockRequestD_XIX_ORU_Control_D_01_XIX_HCP3_CANFD01: start 20, 2 bit, little-endian, data-type-policy=OVERRIDE, i-signal-type=PRIMITIVE, init-value=0, base-type=BT_OruVehicleLockRequestD, invalid-value=Invalid_OruVehicleLockRequestD_XIX_ORU_Control_D_01_XIX_HCP3_CANFD01:3, compu {3=Cx3_Fehler (CM_OruVehicleLockRequestD_Cx3_Fehler), 1=Cx1_Lock (CM_OruVehicleLockRequestD_Cx1_Lock), 0=Cx0_Init (CM_OruVehicleLockRequestD_Cx0_Init), 2=Cx2_Release (CM_OruVehicleLockRequestD_Cx2_Release)}, range raw 0..3, transfer-property=TRIGGERED-ON-CHANGE  # Releases or locks one or more ECUs with their specific functions (e.g. immobilizer)
          signal OruIntegrityCheckActiveD_XIX_ORU_Control_D_01_XIX_HCP3_CANFD01: start 22, 2 bit, little-endian, data-type-policy=OVERRIDE, i-signal-type=PRIMITIVE, init-value=0, base-type=BT_OruIntegrityCheckActiveD, invalid-value=Invalid_OruIntegrityCheckActiveD_XIX_ORU_Control_D_01_XIX_HCP3_CANFD01:3, compu {3=Cx3_Fehler (CM_OruIntegrityCheckActiveD_Cx3_Fehler), 1=Cx1_Inactive (CM_OruIntegrityCheckActiveD_Cx1_Inactive), 2=Cx2_Active (CM_OruIntegrityCheckActiveD_Cx2_Active), 0=Cx0_Init (CM_OruIntegrityCheckActiveD_Cx0_Init)}, range raw 0..3, transfer-property=TRIGGERED-ON-CHANGE  # Signal to indicate if the integrity check is active
          signal OruControlReleaseD_XIX_ORU_Control_D_01_XIX_HCP3_CANFD01: start 24, 16 bit, little-endian, data-type-policy=OVERRIDE, i-signal-type=PRIMITIVE, init-value=0, base-type=BT_OruControlReleaseD, compu {phys=raw for raw 0..65535; unit Unit_None}, range phys 0..65535 Unit_None, raw 0..65535, unit=Unit_None, transfer-property=TRIGGERED-ON-CHANGE  # This signal is used to allow an ECU to start an update session. As this is a critical point, 2 components have to approve this
          signal OruControlStateD_XIX_ORU_Control_D_01_XIX_HCP3_CANFD01: start 40, 8 bit, little-endian, data-type-policy=OVERRIDE, i-signal-type=PRIMITIVE, init-value=0, base-type=BT_OruControlStateD, invalid-value=Invalid_OruControlStateD_XIX_ORU_Control_D_01_XIX_HCP3_CANFD01:129, compu {129=Cx81_Fehler (CM_OruControlStateD_Cx81_Fehler), 15=Cxf_Running (CM_OruControlStateD_Cxf_Running), 1=Cx1_Check (CM_OruControlStateD_Cx1_Check), 65=Cx41_Fail (CM_OruControlStateD_Cx41_Fail), 31=Cx1f_Save (CM_OruControlStateD_Cx1f_Save), 0=Cx0_Idle (CM_OruControlStateD_Cx0_Idle), 63=Cx3f_Done (CM_OruControlStateD_Cx3f_Done), 3=Cx3_DataPresent (CM_OruControlStateD_Cx3_DataPresent), 7=Cx7_LockActive (CM_OruControlStateD_Cx7_LockActive)}, range raw 0..129, transfer-property=TRIGGERED-ON-CHANGE  # This signal is used to allow an ECU to start an update session.
          signal OruReleasePartitionSwitchD_XIX_ORU_Control_D_01_XIX_HCP3_CANFD01: start 48, 2 bit, little-endian, data-type-policy=OVERRIDE, i-signal-type=PRIMITIVE, init-value=0, base-type=BT_OruReleasePartitionSwitchD, invalid-value=Invalid_OruReleasePartitionSwitchD_XIX_ORU_Control_D_01_XIX_HCP3_CANFD01:3, compu {3=Cx3_Fehler (CM_OruReleasePartitionSwitchD_Cx3_Fehler), 2=Cx2_Release (CM_OruReleasePartitionSwitchD_Cx2_Release), 0=Cx0_Init (CM_OruReleasePartitionSwitchD_Cx0_Init), 1=Cx1_Lock (CM_OruReleasePartitionSwitchD_Cx1_Lock)}, range raw 0..3, transfer-property=TRIGGERED-ON-CHANGE  # Release to switch the partition in case of an A/B partition update
          signal OruHostUpdateD_XIX_ORU_Control_D_01_XIX_HCP3_CANFD01: start 50, 3 bit, little-endian, data-type-policy=OVERRIDE, i-signal-type=PRIMITIVE, init-value=0, base-type=BT_OruHostUpdateD, invalid-value=Invalid_OruHostUpdateD_XIX_ORU_Control_D_01_XIX_HCP3_CANFD01:4, compu {4=Cx4_Fehler (CM_OruHostUpdateD_Cx4_Fehler), 0=Cx0_Init (CM_OruHostUpdateD_Cx0_Init), 1=Cx1_HostControl1 (CM_OruHostUpdateD_Cx1_HostControl1), 3=Cx3_HostControlOther (CM_OruHostUpdateD_Cx3_HostControlOther), 2=Cx2_HostControl2 (CM_OruHostUpdateD_Cx2_HostControl2)}, range raw 0..4, transfer-property=TRIGGERED-ON-CHANGE  # Releases an update of an critical funcion's host (due to functional safety)
          mapping SG_ORU_Control_D_01_XIX_HCP3_CANFD01: i-signal-group=SG_ORU_Control_D_01_XIX_HCP3_CANFD01, transfer-property=TRIGGERED-ON-CHANGE
          signal ISignalVoid_ORU_Control_D_01_XIX_HCP3_CANFD01_0: start 53, 3 bit, little-endian, system signal SignalVoid_ORU_Control_D_01_0, data-type-policy=OVERRIDE, i-signal-type=PRIMITIVE, base-type=BT_SignalVoid, transfer-property=PENDING
          signal ISignalVoid_ORU_Control_D_01_XIX_HCP3_CANFD01_1: start 56, 8 bit, little-endian, system signal SignalVoid_ORU_Control_D_01_1, data-type-policy=OVERRIDE, i-signal-type=PRIMITIVE, base-type=BT_SignalVoid, transfer-property=PENDING
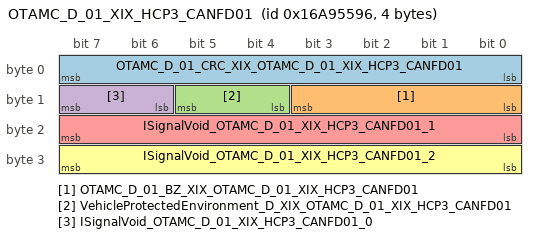
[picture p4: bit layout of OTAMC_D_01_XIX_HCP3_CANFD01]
      frame OTAMC_D_01_XIX_HCP3_CANFD01: id 0x16A95596, from HCP3_IONode, frame-length=4, can-addressing-mode=EXTENDED, can-frame-rx-behavior=CAN-FD, can-frame-tx-behavior=CAN-FD
        pdu OTAMC_D_01_XIX_HCP3_CANFD01: length=4, transmission-mode-true-timing=cyclic-timing={time-offset=0.0, time-period=0.32}, unused-bit-pattern=0
          signal OTAMC_D_01_CRC_XIX_OTAMC_D_01_XIX_HCP3_CANFD01: start 0, 8 bit, little-endian, data-type-policy=OVERRIDE, i-signal-type=PRIMITIVE, init-value=0, base-type=BT_OTAMC_D_01_CRC, compu {phys=raw for raw 0..255}, range phys 0..255, raw 0..255, transfer-property=TRIGGERED-ON-CHANGE
          signal OTAMC_D_01_BZ_XIX_OTAMC_D_01_XIX_HCP3_CANFD01: start 8, 4 bit, little-endian, data-type-policy=OVERRIDE, i-signal-type=PRIMITIVE, init-value=0, base-type=BT_OTAMC_D_01_BZ, compu {phys=raw for raw 0..15}, range phys 0..15, raw 0..15, transfer-property=TRIGGERED-ON-CHANGE
          signal VehicleProtectedEnvironment_D_XIX_OTAMC_D_01_XIX_HCP3_CANFD01: start 12, 2 bit, little-endian, data-type-policy=OVERRIDE, i-signal-type=PRIMITIVE, init-value=0, base-type=BT_VehicleProtectedEnvironment_D, compu {2=Cx2_VPE_aftersales (CM_VehicleProtectedEnvironment_D_Cx2_VPE_aftersales), 0=Cx0_VPE_none (CM_VehicleProtectedEnvironment_D_Cx0_VPE_none), 1=Cx1_VPE_production (CM_VehicleProtectedEnvironment_D_Cx1_VPE_production)}, range raw 0..2, transfer-property=TRIGGERED-ON-CHANGE  # Environment of vehicle in case of Remote Production
          mapping SG_OTAMC_D_01_XIX_HCP3_CANFD01: i-signal-group=SG_OTAMC_D_01_XIX_HCP3_CANFD01, transfer-property=TRIGGERED-ON-CHANGE
          signal ISignalVoid_OTAMC_D_01_XIX_HCP3_CANFD01_0: start 14, 2 bit, little-endian, system signal SignalVoid_OTAMC_D_01_0, data-type-policy=OVERRIDE, i-signal-type=PRIMITIVE, base-type=BT_SignalVoid, transfer-property=PENDING
          signal ISignalVoid_OTAMC_D_01_XIX_HCP3_CANFD01_1: start 16, 8 bit, little-endian, system signal SignalVoid_OTAMC_D_01_1, data-type-policy=OVERRIDE, i-signal-type=PRIMITIVE, base-type=BT_SignalVoid, transfer-property=PENDING
          signal ISignalVoid_OTAMC_D_01_XIX_HCP3_CANFD01_2: start 24, 8 bit, little-endian, system signal SignalVoid_OTAMC_D_01_2, data-type-policy=OVERRIDE, i-signal-type=PRIMITIVE, base-type=BT_SignalVoid, transfer-property=PENDING
      frame PID_01_XIX_HCP3_CANFD01: id 0x16A95527, to HCP3_IONode, frame-length=48, can-addressing-mode=EXTENDED, can-frame-rx-behavior=CAN-FD, can-frame-tx-behavior=CAN-FD
        pdu PID_01_XIX_HCP3_CANFD01: length=48, minimum-delay=0.04, transmission-mode-true-timing={cyclic-timing={time-offset=0.0, time-period=1.0}, event-controlled-timing={number-of-repetitions=0, repetition-period=0.0}}, unused-bit-pattern=0
          signal PID_LVDS_State_XIX_PID_01_XIX_HCP3_CANFD01: start 12, 1 bit, little-endian, data-type-policy=OVERRIDE, i-signal-type=PRIMITIVE, init-value=0, base-type=BT_PID_LVDS_State, compu {0=Cx0_LVDS_Unlocked (CM_PID_LVDS_State_Cx0_LVDS_Unlocked), 1=Cx1_LVDS_Lock (CM_PID_LVDS_State_Cx1_LVDS_Lock)}, range raw 0..1, transfer-property=TRIGGERED-ON-CHANGE-WITHOUT-REPETITION, to HCP3_IONode(timeout 5 s)  # LVDS_Lock= 1 Valide videosignal from MU LVDS_Unlocked = 0 No valid videosignal from MU
          signal PID_State_XIX_PID_01_XIX_HCP3_CANFD01: start 13, 3 bit, little-endian, data-type-policy=OVERRIDE, i-signal-type=PRIMITIVE, init-value=0, base-type=BT_PID_State, compu {1=Cx1_Disp_On (CM_PID_State_Cx1_Disp_On), 0=Cx0_Disp_Off (CM_PID_State_Cx0_Disp_Off), 2=Cx2_LowPow (CM_PID_State_Cx2_LowPow)}, range raw 0..2, transfer-property=TRIGGERED-ON-CHANGE-WITHOUT-REPETITION, to HCP3_IONode(timeout 5 s)  # Power state of PID
          signal PID_PCB_Temp_Error_XIX_PID_01_XIX_HCP3_CANFD01: start 16, 1 bit, little-endian, data-type-policy=OVERRIDE, i-signal-type=PRIMITIVE, init-value=0, base-type=BT_PID_PCB_Temp_Error, invalid-value=Invalid_PID_PCB_Temp_Error_XIX_PID_01_XIX_HCP3_CANFD01:1, compu {1=Cx1_Fehler (CM_PID_PCB_Temp_Error_Cx1_Fehler), 0=Cx0_normal (CM_PID_PCB_Temp_Error_Cx0_normal)}, range raw 0..1, transfer-property=TRIGGERED-ON-CHANGE-WITHOUT-REPETITION, to HCP3_IONode(timeout 5 s)  # Display unit has detected a temperature error of the PCB
          signal PID_Temp_Error_XIX_PID_01_XIX_HCP3_CANFD01: start 17, 1 bit, little-endian, data-type-policy=OVERRIDE, i-signal-type=PRIMITIVE, init-value=0, base-type=BT_PID_Temp_Error, invalid-value=Invalid_PID_Temp_Error_XIX_PID_01_XIX_HCP3_CANFD01:1, compu {1=Cx1_Fehler (CM_PID_Temp_Error_Cx1_Fehler), 0=Cx0_normal (CM_PID_Temp_Error_Cx0_normal)}, range raw 0..1, transfer-property=TRIGGERED-ON-CHANGE-WITHOUT-REPETITION, to HCP3_IONode(timeout 5 s)  # Display unit has detected a temperature error of the display panel
          signal PID_HDCP_Status_XIX_PID_01_XIX_HCP3_CANFD01: start 18, 1 bit, little-endian, data-type-policy=OVERRIDE, i-signal-type=PRIMITIVE, init-value=0, base-type=BT_PID_HDCP_Status, invalid-value=Invalid_PID_HDCP_Status_XIX_PID_01_XIX_HCP3_CANFD01:1, compu {1=Cx1_Fehler (CM_PID_HDCP_Status_Cx1_Fehler), 0=Cx0_Kein_Fehler (CM_PID_HDCP_Status_Cx0_Kein_Fehler)}, range raw 0..1, transfer-property=TRIGGERED-ON-CHANGE-WITHOUT-REPETITION, to HCP3_IONode(timeout 5 s)  # Current status of HDCP
          signal PID_SystemMode_XIX_PID_01_XIX_HCP3_CANFD01: start 19, 1 bit, little-endian, data-type-policy=OVERRIDE, i-signal-type=PRIMITIVE, init-value=0, base-type=BT_PID_SystemMode, compu {0=Cx0_bootloader (CM_PID_SystemMode_Cx0_bootloader), 1=Cx1_applikation (CM_PID_SystemMode_Cx1_applikation)}, range raw 0..1, transfer-property=TRIGGERED-ON-CHANGE-WITHOUT-REPETITION, to HCP3_IONode(timeout 5 s)  # Current system mode
          signal PID_LVDS_Errorstate_XIX_PID_01_XIX_HCP3_CANFD01: start 20, 2 bit, little-endian, data-type-policy=OVERRIDE, i-signal-type=PRIMITIVE, init-value=0, base-type=BT_PID_LVDS_Errorstate, compu {1=Cx1_SW_error (CM_PID_LVDS_Errorstate_Cx1_SW_error), 0=Cx0_no_error (CM_PID_LVDS_Errorstate_Cx0_no_error), 2=Cx2_HW_error (CM_PID_LVDS_Errorstate_Cx2_HW_error)}, range raw 0..2, transfer-property=PENDING, to HCP3_IONode(timeout 5 s)  # PID_LVDS_Errorstate = 0 no error detected PID_LVDS_Errorstate = 1 SW error detected PID_LVDS_Errorstate = 2 HW error detected
          signal PID_CL30_Overvoltage_Error_XIX_PID_01_XIX_HCP3_CANFD01: start 22, 1 bit, little-endian, data-type-policy=OVERRIDE, i-signal-type=PRIMITIVE, init-value=0, base-type=BT_PID_CL30_Overvoltage_Error, invalid-value=Invalid_PID_CL30_Overvoltage_Error_XIX_PID_01_XIX_HCP3_CANFD01:1, compu {1=Cx1_Fehler (CM_PID_CL30_Overvoltage_Error_Cx1_Fehler), 0=Cx0_normal (CM_PID_CL30_Overvoltage_Error_Cx0_normal)}, range raw 0..1, transfer-property=TRIGGERED-ON-CHANGE-WITHOUT-REPETITION, to HCP3_IONode(timeout 5 s)  # Display unit detected overvoltage error
          signal PID_CL30_Undervoltage_Error_XIX_PID_01_XIX_HCP3_CANFD01: start 23, 1 bit, little-endian, data-type-policy=OVERRIDE, i-signal-type=PRIMITIVE, init-value=0, base-type=BT_PID_CL30_Undervoltage_Error, invalid-value=Invalid_PID_CL30_Undervoltage_Error_XIX_PID_01_XIX_HCP3_CANFD01:1, compu {1=Cx1_Fehler (CM_PID_CL30_Undervoltage_Error_Cx1_Fehler), 0=Cx0_normal (CM_PID_CL30_Undervoltage_Error_Cx0_normal)}, range raw 0..1, transfer-property=TRIGGERED-ON-CHANGE-WITHOUT-REPETITION, to HCP3_IONode(timeout 5 s)  # Display unit detected undervoltage error
          signal PID_CL_30F_XIX_PID_01_XIX_HCP3_CANFD01: start 24, 8 bit, little-endian, data-type-policy=OVERRIDE, i-signal-type=PRIMITIVE, init-value=254, base-type=BT_PID_CL_30F, invalid-value=Invalid_PID_CL_30F_XIX_PID_01_XIX_HCP3_CANFD01:255, compu {phys=raw*0.1 for raw 0..253, 255=Cxff_Fehler (CM_PID_CL_30F_Cxff_Fehler), 254=Cxfe_Init (CM_PID_CL_30F_Cxfe_Init); unit Unit_Volt}, range phys 0..25.3 Unit_Volt, raw 0..255, unit=Unit_Volt, transfer-property=PENDING, to HCP3_IONode(timeout 5 s)  # Measured supply voltage of the display unit in volt
          signal PID_FanSpeed_XIX_PID_01_XIX_HCP3_CANFD01: start 32, 7 bit, little-endian, data-type-policy=OVERRIDE, i-signal-type=PRIMITIVE, init-value=126, base-type=BT_PID_FanSpeed, invalid-value=Invalid_PID_FanSpeed_XIX_PID_01_XIX_HCP3_CANFD01:127, compu {phys=raw for raw 0..100, 127=Cx7f_Fehler (CM_PID_FanSpeed_Cx7f_Fehler), 126=Cx7e_Init (CM_PID_FanSpeed_Cx7e_Init); unit Unit_PerCent}, range phys 0..100 Unit_PerCent, raw 0..127, unit=Unit_PerCent, transfer-property=PENDING, to HCP3_IONode(timeout 5 s)  # Speed of fan in display unit
          signal PID_Photosensor_XIX_PID_01_XIX_HCP3_CANFD01: start 39, 9 bit, little-endian, data-type-policy=OVERRIDE, i-signal-type=PRIMITIVE, init-value=510, base-type=BT_PID_Photosensor, invalid-value=Invalid_PID_Photosensor_XIX_PID_01_XIX_HCP3_CANFD01:511, compu {phys=raw*0.25 for raw 1..400, 511=Cx1ff_Fehler (CM_PID_Photosensor_Cx1ff_Fehler), 0=Cx0_Sensor_unbeleuchtet (CM_PID_Photosensor_Cx0_Sensor_unbeleuchtet), 510=Cx1fe_Initialwert (CM_PID_Photosensor_Cx1fe_Initialwert); unit Unit_PerCent}, range phys 0.25..100 Unit_PerCent, raw 0..511, unit=Unit_PerCent, transfer-property=PENDING, to HCP3_IONode(timeout 5 s)  # Measured value photosensor of the display unit (PCM or CDR) logarithmically distorted (see description of functions Nightdesign - according to Audi Spec) PCM/CDR_Signal
          signal PID_DispDerating_XIX_PID_01_XIX_HCP3_CANFD01: start 48, 8 bit, little-endian, data-type-policy=OVERRIDE, i-signal-type=PRIMITIVE, init-value=254, base-type=BT_PID_DispDerating, invalid-value=Invalid_PID_DispDerating_XIX_PID_01_XIX_HCP3_CANFD01:255, compu {phys=raw for raw 0..100, 255=Cxff_Fehler (CM_PID_DispDerating_Cxff_Fehler), 254=Cxfe_Init (CM_PID_DispDerating_Cxfe_Init); unit Unit_PerCent}, range phys 0..100 Unit_PerCent, raw 0..255, unit=Unit_PerCent, transfer-property=PENDING, to HCP3_IONode(timeout 5 s)  # Limitation of power dissipation depending on the temperature
          signal PID_TempSensor_XIX_PID_01_XIX_HCP3_CANFD01: start 56, 8 bit, little-endian, data-type-policy=OVERRIDE, i-signal-type=PRIMITIVE, init-value=254, base-type=BT_PID_TempSensor, invalid-value=Invalid_PID_TempSensor_XIX_PID_01_XIX_HCP3_CANFD01:255, compu {phys=raw-55 for raw 0..182, 255=Cxff_Fehler (CM_PID_TempSensor_Cxff_Fehler), 254=Cxfe_Init (CM_PID_TempSensor_Cxfe_Init); unit Unit_DegreCelsi}, range phys -55..127 Unit_DegreCelsi, raw 0..255, unit=Unit_DegreCelsi, transfer-property=PENDING, to HCP3_IONode(timeout 5 s)  # Display Unit current temperatur of the displaypanel
          signal PID_TempSensorMax_XIX_PID_01_XIX_HCP3_CANFD01: start 64, 8 bit, little-endian, data-type-policy=OVERRIDE, i-signal-type=PRIMITIVE, init-value=254, base-type=BT_PID_TempSensorMax, invalid-value=Invalid_PID_TempSensorMax_XIX_PID_01_XIX_HCP3_CANFD01:255, compu {phys=raw-55 for raw 0..182, 255=Cxff_Fehler (CM_PID_TempSensorMax_Cxff_Fehler), 254=Cxfe_Init (CM_PID_TempSensorMax_Cxfe_Init); unit Unit_DegreCelsi}, range phys -55..127 Unit_DegreCelsi, raw 0..255, unit=Unit_DegreCelsi, transfer-property=PENDING, to HCP3_IONode(timeout 5 s)  # Stored maximum sensor temperature of the display panel. Value remains over quiescent current
          signal PID_PCB_TempSensor_XIX_PID_01_XIX_HCP3_CANFD01: start 72, 8 bit, little-endian, data-type-policy=OVERRIDE, i-signal-type=PRIMITIVE, init-value=254, base-type=BT_PID_PCB_TempSensor, invalid-value=Invalid_PID_PCB_TempSensor_XIX_PID_01_XIX_HCP3_CANFD01:255, compu {phys=raw-55 for raw 0..182, 255=Cxff_Fehler (CM_PID_PCB_TempSensor_Cxff_Fehler), 254=Cxfe_Init (CM_PID_PCB_TempSensor_Cxfe_Init); unit Unit_DegreCelsi}, range phys -55..127 Unit_DegreCelsi, raw 0..255, unit=Unit_DegreCelsi, transfer-property=PENDING, to HCP3_IONode(timeout 5 s)  # Display Unit current temperatur of the PCB
          signal PID_PCB_TempSensorMax_XIX_PID_01_XIX_HCP3_CANFD01: start 80, 8 bit, little-endian, data-type-policy=OVERRIDE, i-signal-type=PRIMITIVE, init-value=254, base-type=BT_PID_PCB_TempSensorMax, invalid-value=Invalid_PID_PCB_TempSensorMax_XIX_PID_01_XIX_HCP3_CANFD01:255, compu {phys=raw-55 for raw 0..182, 255=Cxff_Fehler (CM_PID_PCB_TempSensorMax_Cxff_Fehler), 254=Cxfe_Init (CM_PID_PCB_TempSensorMax_Cxfe_Init); unit Unit_DegreCelsi}, range phys -55..127 Unit_DegreCelsi, raw 0..255, unit=Unit_DegreCelsi, transfer-property=PENDING, to HCP3_IONode(timeout 5 s)  # Stored maximum sensor temperature of the PCB (display unit). Value remains over quiescent current
          signal PID_OperatingTime_min_XIX_PID_01_XIX_HCP3_CANFD01: start 88, 8 bit, little-endian, data-type-policy=OVERRIDE, i-signal-type=PRIMITIVE, init-value=254, base-type=BT_PID_OperatingTime_min, invalid-value=Invalid_PID_OperatingTime_min_XIX_PID_01_XIX_HCP3_CANFD01:255, compu {phys=raw for raw 0..59, 255=Cxff_Fehler (CM_PID_OperatingTime_min_Cxff_Fehler), 254=Cxfe_Init (CM_PID_OperatingTime_min_Cxfe_Init); unit Unit_Minut}, range phys 0..59 Unit_Minut, raw 0..255, unit=Unit_Minut, transfer-property=PENDING, to HCP3_IONode(timeout 5 s)  # Display Unit operatingtime minutes share
          signal PID_OperatingTime_hr_XIX_PID_01_XIX_HCP3_CANFD01: start 96, 16 bit, little-endian, data-type-policy=OVERRIDE, i-signal-type=PRIMITIVE, init-value=65534, base-type=BT_PID_OperatingTime_hr, invalid-value=Invalid_PID_OperatingTime_hr_XIX_PID_01_XIX_HCP3_CANFD01:65535, compu {phys=raw for raw 0..65533, 65535=Cxffff_Fehler (CM_PID_OperatingTime_hr_Cxffff_Fehler), 65534=Cxfffe_Init (CM_PID_OperatingTime_hr_Cxfffe_Init); unit Unit_Hours}, range phys 0..65533 Unit_Hours, raw 0..65535, unit=Unit_Hours, transfer-property=PENDING, to HCP3_IONode(timeout 5 s)  # Display Unit operatingtime hours share
          signal PID_VW_SL_Spare_Part_Nr_Index_XIX_PID_01_XIX_HCP3_CANFD01: start 112, 16 bit, little-endian, data-type-policy=OVERRIDE, i-signal-type=PRIMITIVE, init-value=45, base-type=BT_PID_VW_SL_Spare_Part_Nr_Index, compu {phys=raw for raw 0..65534, 65535=Cxffff_Error (CM_PID_VW_SL_Spare_Part_Nr_Index_Cxffff_Error); unit Unit_None}, range phys 0..65534 Unit_None, raw 0..65535, unit=Unit_None, transfer-property=PENDING, to HCP3_IONode(timeout 5 s)  # Index of VW SparePartNumber
          signal PID_VW_SL_App_SW_Version_Nr_XIX_PID_01_XIX_HCP3_CANFD01: start 128, 32 bit, little-endian, data-type-policy=OVERRIDE, i-signal-type=PRIMITIVE, init-value=45, base-type=BT_PID_VW_SL_App_SW_Version_Nr, compu {phys=raw for raw 0..4294967294, 4294967295=Cxffffffff_Error (CM_PID_VW_SL_App_SW_Version_Nr_Cxffffffff_Error); unit Unit_None}, range phys 0..4294967294 Unit_None, raw 0..4294967295, unit=Unit_None, transfer-property=PENDING, to HCP3_IONode(timeout 5 s)  # VW Software Version Number
          signal PID_VW_SL_HW_Version_Nr_XIX_PID_01_XIX_HCP3_CANFD01: start 160, 24 bit, little-endian, data-type-policy=OVERRIDE, i-signal-type=PRIMITIVE, init-value=45, base-type=BT_PID_VW_SL_HW_Version_Nr, compu {phys=raw for raw 0..16777214, 16777215=Cxffffff_Error (CM_PID_VW_SL_HW_Version_Nr_Cxffffff_Error); unit Unit_None}, range phys 0..16777214 Unit_None, raw 0..16777215, unit=Unit_None, transfer-property=PENDING, to HCP3_IONode(timeout 5 s)  # VW ECU Hardware Version Number
          signal PID_VW_SL_Spare_Part_Nr_EndNr_XIX_PID_01_XIX_HCP3_CANFD01: start 184, 24 bit, little-endian, data-type-policy=OVERRIDE, i-signal-type=PRIMITIVE, init-value=45, base-type=BT_PID_VW_SL_Spare_Part_Nr_EndNr, compu {phys=raw for raw 0..16777214, 16777215=Cxffffff_Error (CM_PID_VW_SL_Spare_Part_Nr_EndNr_Cxffffff_Error); unit Unit_None}, range phys 0..16777214 Unit_None, raw 0..16777215, unit=Unit_None, transfer-property=PENDING, to HCP3_IONode(timeout 5 s)  # End number of VW SparePartNumber
          signal PID_VW_SL_Spare_Part_Nr_MittelNr_XIX_PID_01_XIX_HCP3_CANFD01: start 208, 24 bit, little-endian, data-type-policy=OVERRIDE, i-signal-type=PRIMITIVE, init-value=45, base-type=BT_PID_VW_SL_Spare_Part_Nr_MittelNr, compu {phys=raw for raw 0..16777214, 16777215=Cxffffff_Error (CM_PID_VW_SL_Spare_Part_Nr_MittelNr_Cxffffff_Error); unit Unit_None}, range phys 0..16777214 Unit_None, raw 0..16777215, unit=Unit_None, transfer-property=PENDING, to HCP3_IONode(timeout 5 s)  # Middle number of VW SparePartNumber
          signal PID_VW_SL_Spare_Part_Nr_TMA_XIX_PID_01_XIX_HCP3_CANFD01: start 232, 24 bit, little-endian, data-type-policy=OVERRIDE, i-signal-type=PRIMITIVE, init-value=45, base-type=BT_PID_VW_SL_Spare_Part_Nr_TMA, compu {phys=raw for raw 0..16777214, 16777215=Cxffffff_Error (CM_PID_VW_SL_Spare_Part_Nr_TMA_Cxffffff_Error); unit Unit_None}, range phys 0..16777214 Unit_None, raw 0..16777215, unit=Unit_None, transfer-property=PENDING, to HCP3_IONode(timeout 5 s)  # TMA of VW SparePartNumber
          signal PID_Touch_Errorstate_XIX_PID_01_XIX_HCP3_CANFD01: start 256, 2 bit, little-endian, data-type-policy=OVERRIDE, i-signal-type=PRIMITIVE, init-value=0, base-type=BT_PID_Touch_Errorstate, compu {1=Cx1_SW_error (CM_PID_Touch_Errorstate_Cx1_SW_error), 2=Cx2_HW_error (CM_PID_Touch_Errorstate_Cx2_HW_error), 0=Cx0_no_error (CM_PID_Touch_Errorstate_Cx0_no_error)}, range raw 0..2, transfer-property=PENDING, to HCP3_IONode(timeout 5 s)  # PID_Touch_Errorstate = 0 no error detected PID_Touch_Errorstate = 1 SW error detected PID_Touch_Errorstate = 2 HW error detected
          signal PID_Haptik_Errorstate_XIX_PID_01_XIX_HCP3_CANFD01: start 258, 2 bit, little-endian, data-type-policy=OVERRIDE, i-signal-type=PRIMITIVE, init-value=0, base-type=BT_PID_Haptik_Errorstate, compu {1=Cx1_SW_error (CM_PID_Haptik_Errorstate_Cx1_SW_error), 0=Cx0_no_error (CM_PID_Haptik_Errorstate_Cx0_no_error), 2=Cx2_HW_error (CM_PID_Haptik_Errorstate_Cx2_HW_error)}, range raw 0..2, transfer-property=PENDING, to HCP3_IONode(timeout 5 s)  # PID_Haptik_Errorstate = 0 no error detected PID_Haptik_Errorstate = 1 SW error detected PID_Haptik_Errorstate = 2 HW error detected
          signal PID_LVDS_Splitter_Errorstate_XIX_PID_01_XIX_HCP3_CANFD01: start 260, 2 bit, little-endian, data-type-policy=OVERRIDE, i-signal-type=PRIMITIVE, init-value=0, base-type=BT_PID_LVDS_Splitter_Errorstate, compu {1=Cx1_SW_error (CM_PID_LVDS_Splitter_Errorstate_Cx1_SW_error), 0=Cx0_no_error (CM_PID_LVDS_Splitter_Errorstate_Cx0_no_error), 2=Cx2_HW_error (CM_PID_LVDS_Splitter_Errorstate_Cx2_HW_error)}, range raw 0..2, transfer-property=PENDING, to HCP3_IONode(timeout 5 s)  # PID_LVDS_Splitter_Errorstate = 0 no error detected PID_LVDS_Splitter_Errorstate = 1 SW error detected PID_LVDS_Splitter_Errorstate = 2 HW error detected
          signal PID_ShutterFoil_Errorstate_XIX_PID_01_XIX_HCP3_CANFD01: start 262, 2 bit, little-endian, data-type-policy=OVERRIDE, i-signal-type=PRIMITIVE, init-value=0, base-type=BT_PID_ShutterFoil_Errorstate, compu {0=Cx0_no_error (CM_PID_ShutterFoil_Errorstate_Cx0_no_error), 1=Cx1_SW_error (CM_PID_ShutterFoil_Errorstate_Cx1_SW_error), 2=Cx2_HW_error (CM_PID_ShutterFoil_Errorstate_Cx2_HW_error)}, range raw 0..2, transfer-property=PENDING, to HCP3_IONode(timeout 5 s)  # PID_ShutterFoil_Errorstate = 0 no error detected PID_ShutterFoil_Errorstate = 1 SW error detected PID_ShutterFoil_Errorstate = 2 HW error detected
          signal PID_Proximity_Errorstate_XIX_PID_01_XIX_HCP3_CANFD01: start 264, 2 bit, little-endian, data-type-policy=OVERRIDE, i-signal-type=PRIMITIVE, init-value=0, base-type=BT_PID_Proximity_Errorstate, compu {1=Cx1_SW_error (CM_PID_Proximity_Errorstate_Cx1_SW_error), 0=Cx0_no_error (CM_PID_Proximity_Errorstate_Cx0_no_error), 2=Cx2_HW_error (CM_PID_Proximity_Errorstate_Cx2_HW_error)}, range raw 0..2, transfer-property=PENDING, to HCP3_IONode(timeout 5 s)  # PID_Proximity_Errorstate = 0 no error detected PID_Proximity_Errorstate = 1 SW error detected PID_Proximity_Errorstate = 2 HW error detected
          signal PID_Slider_Errorstate_XIX_PID_01_XIX_HCP3_CANFD01: start 266, 2 bit, little-endian, data-type-policy=OVERRIDE, i-signal-type=PRIMITIVE, init-value=0, base-type=BT_PID_Slider_Errorstate, compu {0=Cx0_no_error (CM_PID_Slider_Errorstate_Cx0_no_error), 1=Cx1_SW_error (CM_PID_Slider_Errorstate_Cx1_SW_error), 2=Cx2_HW_error (CM_PID_Slider_Errorstate_Cx2_HW_error)}, range raw 0..2, transfer-property=PENDING, to HCP3_IONode(timeout 5 s)  # PID_Slider_Errorstate = 0 no error detected PID_Slider_Errorstate = 1 SW error detected PID_Slider_Errorstate = 2 HW error detected
          signal PID_Backlight_ShortCircuit_XIX_PID_01_XIX_HCP3_CANFD01: start 268, 1 bit, little-endian, data-type-policy=OVERRIDE, i-signal-type=PRIMITIVE, init-value=0, base-type=BT_PID_Backlight_ShortCircuit, invalid-value=Invalid_PID_Backlight_ShortCircuit_XIX_PID_01_XIX_HCP3_CANFD01:1, compu {1=Cx1_Fehler (CM_PID_Backlight_ShortCircuit_Cx1_Fehler), 0=Cx0_normal (CM_PID_Backlight_ShortCircuit_Cx0_normal)}, range raw 0..1, transfer-property=TRIGGERED-ON-CHANGE-WITHOUT-REPETITION, to HCP3_IONode(timeout 5 s)  # Backlight has a short circuit
          signal PID_Backlight_OpenCircuit_XIX_PID_01_XIX_HCP3_CANFD01: start 269, 1 bit, little-endian, data-type-policy=OVERRIDE, i-signal-type=PRIMITIVE, init-value=0, base-type=BT_PID_Backlight_OpenCircuit, invalid-value=Invalid_PID_Backlight_OpenCircuit_XIX_PID_01_XIX_HCP3_CANFD01:1, compu {1=Cx1_Fehler (CM_PID_Backlight_OpenCircuit_Cx1_Fehler), 0=Cx0_normal (CM_PID_Backlight_OpenCircuit_Cx0_normal)}, range raw 0..1, transfer-property=TRIGGERED-ON-CHANGE-WITHOUT-REPETITION, to HCP3_IONode(timeout 5 s)  # With current measurements, at least one LED line is broken
          signal PID_SW_inconsistent_XIX_PID_01_XIX_HCP3_CANFD01: start 270, 1 bit, little-endian, data-type-policy=OVERRIDE, i-signal-type=PRIMITIVE, init-value=0, base-type=BT_PID_SW_inconsistent, invalid-value=Invalid_PID_SW_inconsistent_XIX_PID_01_XIX_HCP3_CANFD01:1, compu {1=Cx1_Fehler (CM_PID_SW_inconsistent_Cx1_Fehler), 0=Cx0_Kein_Fehler (CM_PID_SW_inconsistent_Cx0_Kein_Fehler)}, range raw 0..1, transfer-property=PENDING, to HCP3_IONode(timeout 5 s)  # SW_inconsistent = 1 SW Status is inconsistent - error SW_inconsistent = 0 no error - SW is consistent
          signal PID_EEPROM_Error_XIX_PID_01_XIX_HCP3_CANFD01: start 271, 1 bit, little-endian, data-type-policy=OVERRIDE, i-signal-type=PRIMITIVE, init-value=0, base-type=BT_PID_EEPROM_Error, invalid-value=Invalid_PID_EEPROM_Error_XIX_PID_01_XIX_HCP3_CANFD01:1, compu {1=Cx1_Fehler (CM_PID_EEPROM_Error_Cx1_Fehler), 0=Cx0_normal (CM_PID_EEPROM_Error_Cx0_normal)}, range raw 0..1, transfer-property=TRIGGERED-ON-CHANGE-WITHOUT-REPETITION, to HCP3_IONode(timeout 5 s)  # EEPROM error detected
          signal PID_Touchstate_XIX_PID_01_XIX_HCP3_CANFD01: start 272, 1 bit, little-endian, data-type-policy=OVERRIDE, i-signal-type=PRIMITIVE, init-value=0, base-type=BT_PID_Touchstate, compu {0=Cx0_not_touched (CM_PID_Touchstate_Cx0_not_touched), 1=Cx1_touched (CM_PID_Touchstate_Cx1_touched)}, range raw 0..1, transfer-property=TRIGGERED-ON-CHANGE-WITHOUT-REPETITION, to HCP3_IONode(timeout 5 s)  # This signal provides the current touchstate of the touchscreen (not_touched/touched).
      frame PID_DispCtrlPID_Req_FD_XIX_HCP3_CANFD01: id 0x1CD02367, to HCP3_IONode, frame-length=64, can-addressing-mode=EXTENDED, can-frame-rx-behavior=CAN-FD, can-frame-tx-behavior=CAN-FD
        n pdu PID_DispCtrlPID_Req_FD_XIX_HCP3_CANFD01: length=64
      frame PID_DispCtrlPID_Resp_FD_XIX_HCP3_CANFD01: id 0x1CD22367, from HCP3_IONode, frame-length=64, can-addressing-mode=EXTENDED, can-frame-rx-behavior=CAN-FD, can-frame-tx-behavior=CAN-FD
        n pdu PID_DispCtrlPID_Resp_FD_XIX_HCP3_CANFD01: length=64
      frame PID_DispInpPID_Req_FD_XIX_HCP3_CANFD01: id 0x1CD0236A, to HCP3_IONode, frame-length=64, can-addressing-mode=EXTENDED, can-frame-rx-behavior=CAN-FD, can-frame-tx-behavior=CAN-FD
        n pdu PID_DispInpPID_Req_FD_XIX_HCP3_CANFD01: length=64
